VERSION ""

NS_ :

BS_:

BU_: Dummy_FO TestTool_FO LRR_FO RFSRR_FO LFSRR_FO RSRR_FO VIS_FO EOCM_F_FO

BO_ 1323 F_Fwd_Fus_Obj_TrackB_11: 7 EOCM_F_FO
 SG_ FwdFusTrkB11DynProp : 11|3@0+ (1,0) [0|7] ""  Dummy_FO
 SG_ FwdFusTrkB11RelLnAccl : 8|9@0- (0.125,0) [-32|31.875] "m/s^2"  Dummy_FO
 SG_ FwdFusTrkB11RelLane : 31|2@0+ (1,0) [0|3] ""  Dummy_FO
 SG_ FwdFusTrkB11Height : 54|6@0+ (0.25,0) [0|15.75] "m"  Dummy_FO
 SG_ FFusTrkB11ObjSrcLFSrr : 29|1@0+ (1,0) [0|1] ""  Dummy_FO
 SG_ FFusTrkB11ObjSrcLCSrr : 28|1@0+ (1,0) [0|1] ""  Dummy_FO
 SG_ FFusTrkB11ObjSrcRCSrr : 27|1@0+ (1,0) [0|1] ""  Dummy_FO
 SG_ FFusTrkB11ObjSrcRFSrr : 26|1@0+ (1,0) [0|1] ""  Dummy_FO
 SG_ FFusTrkB11ObjSrcVIs : 25|1@0+ (1,0) [0|1] ""  Dummy_FO
 SG_ FwdFusTrkB11ObjSrcLrr : 24|1@0+ (1,0) [0|1] ""  Dummy_FO
 SG_ FwdFusTrkB11NmCycTrkd : 39|3@0+ (1,0) [0|7] ""  Dummy_FO
 SG_ FwdFusTrkB11LatPosDev : 36|3@0+ (1,0) [0|7] ""  Dummy_FO
 SG_ FwdFusTrkB11LngPosDev : 33|3@0+ (1,0) [0|7] ""  Dummy_FO
 SG_ FwdFusTrkBAnlgRlLn11 : 46|8@0- (0.1,0) [-12.8|12.7] ""  Dummy_FO
 SG_ FwdFusTrkB11RollingCnt : 7|2@0+ (1,0) [0|3] ""  Dummy_FO
 SG_ FwdFusTrkB11Width : 5|6@0+ (0.25,0) [0|15.75] "m"  Dummy_FO
 SG_ FwdFusTrkB11MsgIndex : 15|4@0+ (1,0) [0|15] ""  Dummy_FO

BO_ 1322 F_Fwd_Fus_Obj_TrackB_10: 7 EOCM_F_FO
 SG_ FwdFusTrkBAnlgRlLn10 : 46|8@0- (0.1,0) [-12.8|12.7] ""  Dummy_FO
 SG_ FwdFusTrkB10RollingCnt : 7|2@0+ (1,0) [0|3] ""  Dummy_FO
 SG_ FwdFusTrkB10Width : 5|6@0+ (0.25,0) [0|15.75] "m"  Dummy_FO
 SG_ FwdFusTrkB10MsgIndex : 15|4@0+ (1,0) [0|15] ""  Dummy_FO
 SG_ FwdFusTrkB10DynProp : 11|3@0+ (1,0) [0|7] ""  Dummy_FO
 SG_ FwdFusTrkB10RelLnAccl : 8|9@0- (0.125,0) [-32|31.875] "m/s^2"  Dummy_FO
 SG_ FwdFusTrkB10RelLane : 31|2@0+ (1,0) [0|3] ""  Dummy_FO
 SG_ FwdFusTrkB10Height : 54|6@0+ (0.25,0) [0|15.75] "m"  Dummy_FO
 SG_ FFusTrkB10ObjSrcLFSrr : 29|1@0+ (1,0) [0|1] ""  Dummy_FO
 SG_ FFusTrkB10ObjSrcLCSrr : 28|1@0+ (1,0) [0|1] ""  Dummy_FO
 SG_ FFusTrkB10ObjSrcRCSrr : 27|1@0+ (1,0) [0|1] ""  Dummy_FO
 SG_ FFusTrkB10ObjSrcRFSrr : 26|1@0+ (1,0) [0|1] ""  Dummy_FO
 SG_ FFusTrkB10ObjSrcVIs : 25|1@0+ (1,0) [0|1] ""  Dummy_FO
 SG_ FwdFusTrkB10ObjSrcLrr : 24|1@0+ (1,0) [0|1] ""  Dummy_FO
 SG_ FwdFusTrkB10NmCycTrkd : 39|3@0+ (1,0) [0|7] ""  Dummy_FO
 SG_ FwdFusTrkB10LatPosDev : 36|3@0+ (1,0) [0|7] ""  Dummy_FO
 SG_ FwdFusTrkB10LngPosDev : 33|3@0+ (1,0) [0|7] ""  Dummy_FO

BO_ 1313 F_Fwd_Fus_Obj_TrackB_1: 7 EOCM_F_FO
 SG_ FwdFusTrkBAnlgRlLn1 : 46|8@0- (0.1,0) [-12.8|12.7] ""  Dummy_FO
 SG_ FwdFusTrkB1RollingCnt : 7|2@0+ (1,0) [0|3] ""  Dummy_FO
 SG_ FwdFusTrkB1Width : 5|6@0+ (0.25,0) [0|15.75] "m"  Dummy_FO
 SG_ FwdFusTrkB1MsgIndex : 15|4@0+ (1,0) [0|15] ""  Dummy_FO
 SG_ FwdFusTrkB1DynProp : 11|3@0+ (1,0) [0|7] ""  Dummy_FO
 SG_ FwdFusTrkB1RelLnAccl : 8|9@0- (0.125,0) [-32|31.875] "m/s^2"  Dummy_FO
 SG_ FwdFusTrkB1RelLane : 31|2@0+ (1,0) [0|3] ""  Dummy_FO
 SG_ FwdFusTrkB1Height : 54|6@0+ (0.25,0) [0|15.75] "m"  Dummy_FO
 SG_ FFusTrkB1ObjSrcLFSrr : 29|1@0+ (1,0) [0|1] ""  Dummy_FO
 SG_ FFusTrkB1ObjSrcLCSrr : 28|1@0+ (1,0) [0|1] ""  Dummy_FO
 SG_ FFusTrkB1ObjSrcRCSrr : 27|1@0+ (1,0) [0|1] ""  Dummy_FO
 SG_ FFusTrkB1ObjSrcRFSrr : 26|1@0+ (1,0) [0|1] ""  Dummy_FO
 SG_ FFusTrkB1ObjSrcVIs : 25|1@0+ (1,0) [0|1] ""  Dummy_FO
 SG_ FwdFusTrkB1ObjSrcLrr : 24|1@0+ (1,0) [0|1] ""  Dummy_FO
 SG_ FwdFusTrkB1NmCycTrkd : 39|3@0+ (1,0) [0|7] ""  Dummy_FO
 SG_ FwdFusTrkB1LatPosDev : 36|3@0+ (1,0) [0|7] ""  Dummy_FO
 SG_ FwdFusTrkB1LngPosDev : 33|3@0+ (1,0) [0|7] ""  Dummy_FO

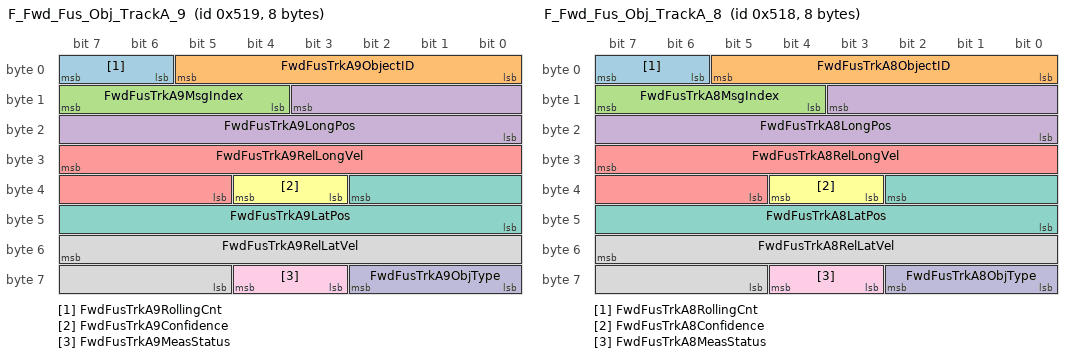
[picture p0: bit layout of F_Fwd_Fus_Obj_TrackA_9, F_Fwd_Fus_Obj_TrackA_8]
BO_ 1305 F_Fwd_Fus_Obj_TrackA_9: 8 EOCM_F_FO
 SG_ FwdFusTrkA9RollingCnt : 7|2@0+ (1,0) [0|3] ""  Dummy_FO
 SG_ FwdFusTrkA9ObjectID : 5|6@0+ (1,0) [0|63] ""  Dummy_FO
 SG_ FwdFusTrkA9MsgIndex : 15|4@0+ (1,0) [0|15] ""  Dummy_FO
 SG_ FwdFusTrkA9LongPos : 11|12@0- (0.125,0) [-256|255.875] "m"  Dummy_FO
 SG_ FwdFusTrkA9RelLongVel : 31|11@0- (0.125,0) [-128|127.875] "m/s"  Dummy_FO
 SG_ FwdFusTrkA9Confidence : 36|2@0+ (1,0) [0|3] ""  Dummy_FO
 SG_ FwdFusTrkA9LatPos : 34|11@0- (0.125,0) [-128|127.875] "m"  Dummy_FO
 SG_ FwdFusTrkA9RelLatVel : 55|11@0- (0.125,0) [-128|127.875] "m/s"  Dummy_FO
 SG_ FwdFusTrkA9MeasStatus : 60|2@0+ (1,0) [0|3] ""  Dummy_FO
 SG_ FwdFusTrkA9ObjType : 58|3@0+ (1,0) [0|7] ""  Dummy_FO

BO_ 1304 F_Fwd_Fus_Obj_TrackA_8: 8 EOCM_F_FO
 SG_ FwdFusTrkA8RollingCnt : 7|2@0+ (1,0) [0|3] ""  Dummy_FO
 SG_ FwdFusTrkA8ObjectID : 5|6@0+ (1,0) [0|63] ""  Dummy_FO
 SG_ FwdFusTrkA8MsgIndex : 15|4@0+ (1,0) [0|15] ""  Dummy_FO
 SG_ FwdFusTrkA8LongPos : 11|12@0- (0.125,0) [-256|255.875] "m"  Dummy_FO
 SG_ FwdFusTrkA8RelLongVel : 31|11@0- (0.125,0) [-128|127.875] "m/s"  Dummy_FO
 SG_ FwdFusTrkA8Confidence : 36|2@0+ (1,0) [0|3] ""  Dummy_FO
 SG_ FwdFusTrkA8LatPos : 34|11@0- (0.125,0) [-128|127.875] "m"  Dummy_FO
 SG_ FwdFusTrkA8RelLatVel : 55|11@0- (0.125,0) [-128|127.875] "m/s"  Dummy_FO
 SG_ FwdFusTrkA8MeasStatus : 60|2@0+ (1,0) [0|3] ""  Dummy_FO
 SG_ FwdFusTrkA8ObjType : 58|3@0+ (1,0) [0|7] ""  Dummy_FO

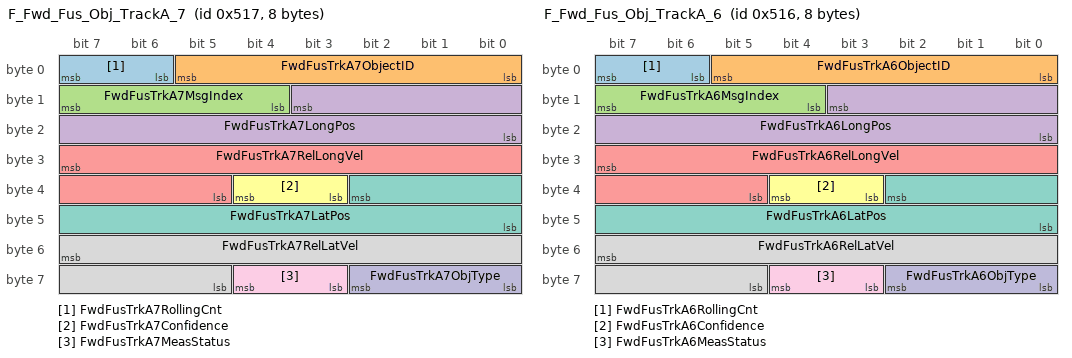
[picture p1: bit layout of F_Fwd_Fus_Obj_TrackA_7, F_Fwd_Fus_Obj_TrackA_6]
BO_ 1303 F_Fwd_Fus_Obj_TrackA_7: 8 EOCM_F_FO
 SG_ FwdFusTrkA7RollingCnt : 7|2@0+ (1,0) [0|3] ""  Dummy_FO
 SG_ FwdFusTrkA7ObjectID : 5|6@0+ (1,0) [0|63] ""  Dummy_FO
 SG_ FwdFusTrkA7MsgIndex : 15|4@0+ (1,0) [0|15] ""  Dummy_FO
 SG_ FwdFusTrkA7LongPos : 11|12@0- (0.125,0) [-256|255.875] "m"  Dummy_FO
 SG_ FwdFusTrkA7RelLongVel : 31|11@0- (0.125,0) [-128|127.875] "m/s"  Dummy_FO
 SG_ FwdFusTrkA7Confidence : 36|2@0+ (1,0) [0|3] ""  Dummy_FO
 SG_ FwdFusTrkA7LatPos : 34|11@0- (0.125,0) [-128|127.875] "m"  Dummy_FO
 SG_ FwdFusTrkA7RelLatVel : 55|11@0- (0.125,0) [-128|127.875] "m/s"  Dummy_FO
 SG_ FwdFusTrkA7MeasStatus : 60|2@0+ (1,0) [0|3] ""  Dummy_FO
 SG_ FwdFusTrkA7ObjType : 58|3@0+ (1,0) [0|7] ""  Dummy_FO

BO_ 1302 F_Fwd_Fus_Obj_TrackA_6: 8 EOCM_F_FO
 SG_ FwdFusTrkA6RollingCnt : 7|2@0+ (1,0) [0|3] ""  Dummy_FO
 SG_ FwdFusTrkA6ObjectID : 5|6@0+ (1,0) [0|63] ""  Dummy_FO
 SG_ FwdFusTrkA6MsgIndex : 15|4@0+ (1,0) [0|15] ""  Dummy_FO
 SG_ FwdFusTrkA6LongPos : 11|12@0- (0.125,0) [-256|255.875] "m"  Dummy_FO
 SG_ FwdFusTrkA6RelLongVel : 31|11@0- (0.125,0) [-128|127.875] "m/s"  Dummy_FO
 SG_ FwdFusTrkA6Confidence : 36|2@0+ (1,0) [0|3] ""  Dummy_FO
 SG_ FwdFusTrkA6LatPos : 34|11@0- (0.125,0) [-128|127.875] "m"  Dummy_FO
 SG_ FwdFusTrkA6RelLatVel : 55|11@0- (0.125,0) [-128|127.875] "m/s"  Dummy_FO
 SG_ FwdFusTrkA6MeasStatus : 60|2@0+ (1,0) [0|3] ""  Dummy_FO
 SG_ FwdFusTrkA6ObjType : 58|3@0+ (1,0) [0|7] ""  Dummy_FO

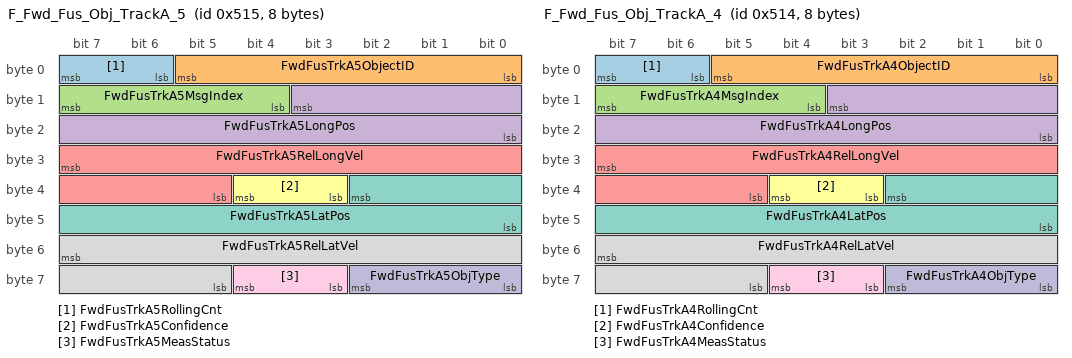
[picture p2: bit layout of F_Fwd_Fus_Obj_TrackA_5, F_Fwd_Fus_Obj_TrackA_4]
BO_ 1301 F_Fwd_Fus_Obj_TrackA_5: 8 EOCM_F_FO
 SG_ FwdFusTrkA5RollingCnt : 7|2@0+ (1,0) [0|3] ""  Dummy_FO
 SG_ FwdFusTrkA5ObjectID : 5|6@0+ (1,0) [0|63] ""  Dummy_FO
 SG_ FwdFusTrkA5MsgIndex : 15|4@0+ (1,0) [0|15] ""  Dummy_FO
 SG_ FwdFusTrkA5LongPos : 11|12@0- (0.125,0) [-256|255.875] "m"  Dummy_FO
 SG_ FwdFusTrkA5RelLongVel : 31|11@0- (0.125,0) [-128|127.875] "m/s"  Dummy_FO
 SG_ FwdFusTrkA5Confidence : 36|2@0+ (1,0) [0|3] ""  Dummy_FO
 SG_ FwdFusTrkA5LatPos : 34|11@0- (0.125,0) [-128|127.875] "m"  Dummy_FO
 SG_ FwdFusTrkA5RelLatVel : 55|11@0- (0.125,0) [-128|127.875] "m/s"  Dummy_FO
 SG_ FwdFusTrkA5MeasStatus : 60|2@0+ (1,0) [0|3] ""  Dummy_FO
 SG_ FwdFusTrkA5ObjType : 58|3@0+ (1,0) [0|7] ""  Dummy_FO

BO_ 1300 F_Fwd_Fus_Obj_TrackA_4: 8 EOCM_F_FO
 SG_ FwdFusTrkA4RollingCnt : 7|2@0+ (1,0) [0|3] ""  Dummy_FO
 SG_ FwdFusTrkA4ObjectID : 5|6@0+ (1,0) [0|63] ""  Dummy_FO
 SG_ FwdFusTrkA4MsgIndex : 15|4@0+ (1,0) [0|15] ""  Dummy_FO
 SG_ FwdFusTrkA4LongPos : 11|12@0- (0.125,0) [-256|255.875] "m"  Dummy_FO
 SG_ FwdFusTrkA4RelLongVel : 31|11@0- (0.125,0) [-128|127.875] "m/s"  Dummy_FO
 SG_ FwdFusTrkA4Confidence : 36|2@0+ (1,0) [0|3] ""  Dummy_FO
 SG_ FwdFusTrkA4LatPos : 34|11@0- (0.125,0) [-128|127.875] "m"  Dummy_FO
 SG_ FwdFusTrkA4RelLatVel : 55|11@0- (0.125,0) [-128|127.875] "m/s"  Dummy_FO
 SG_ FwdFusTrkA4MeasStatus : 60|2@0+ (1,0) [0|3] ""  Dummy_FO
 SG_ FwdFusTrkA4ObjType : 58|3@0+ (1,0) [0|7] ""  Dummy_FO

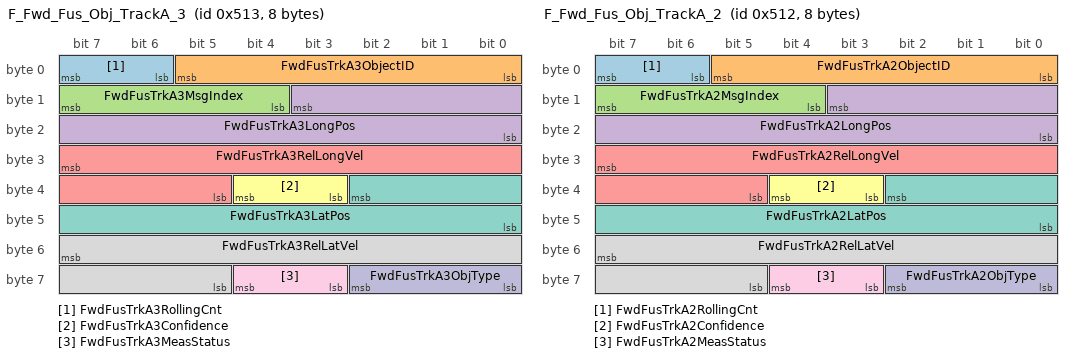
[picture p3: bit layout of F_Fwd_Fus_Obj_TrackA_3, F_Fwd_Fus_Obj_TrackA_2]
BO_ 1299 F_Fwd_Fus_Obj_TrackA_3: 8 EOCM_F_FO
 SG_ FwdFusTrkA3RollingCnt : 7|2@0+ (1,0) [0|3] ""  Dummy_FO
 SG_ FwdFusTrkA3ObjectID : 5|6@0+ (1,0) [0|63] ""  Dummy_FO
 SG_ FwdFusTrkA3MsgIndex : 15|4@0+ (1,0) [0|15] ""  Dummy_FO
 SG_ FwdFusTrkA3LongPos : 11|12@0- (0.125,0) [-256|255.875] "m"  Dummy_FO
 SG_ FwdFusTrkA3RelLongVel : 31|11@0- (0.125,0) [-128|127.875] "m/s"  Dummy_FO
 SG_ FwdFusTrkA3Confidence : 36|2@0+ (1,0) [0|3] ""  Dummy_FO
 SG_ FwdFusTrkA3LatPos : 34|11@0- (0.125,0) [-128|127.875] "m"  Dummy_FO
 SG_ FwdFusTrkA3RelLatVel : 55|11@0- (0.125,0) [-128|127.875] "m/s"  Dummy_FO
 SG_ FwdFusTrkA3MeasStatus : 60|2@0+ (1,0) [0|3] ""  Dummy_FO
 SG_ FwdFusTrkA3ObjType : 58|3@0+ (1,0) [0|7] ""  Dummy_FO

BO_ 1298 F_Fwd_Fus_Obj_TrackA_2: 8 EOCM_F_FO
 SG_ FwdFusTrkA2RollingCnt : 7|2@0+ (1,0) [0|3] ""  Dummy_FO
 SG_ FwdFusTrkA2ObjectID : 5|6@0+ (1,0) [0|63] ""  Dummy_FO
 SG_ FwdFusTrkA2MsgIndex : 15|4@0+ (1,0) [0|15] ""  Dummy_FO
 SG_ FwdFusTrkA2LongPos : 11|12@0- (0.125,0) [-256|255.875] "m"  Dummy_FO
 SG_ FwdFusTrkA2RelLongVel : 31|11@0- (0.125,0) [-128|127.875] "m/s"  Dummy_FO
 SG_ FwdFusTrkA2Confidence : 36|2@0+ (1,0) [0|3] ""  Dummy_FO
 SG_ FwdFusTrkA2LatPos : 34|11@0- (0.125,0) [-128|127.875] "m"  Dummy_FO
 SG_ FwdFusTrkA2RelLatVel : 55|11@0- (0.125,0) [-128|127.875] "m/s"  Dummy_FO
 SG_ FwdFusTrkA2MeasStatus : 60|2@0+ (1,0) [0|3] ""  Dummy_FO
 SG_ FwdFusTrkA2ObjType : 58|3@0+ (1,0) [0|7] ""  Dummy_FO

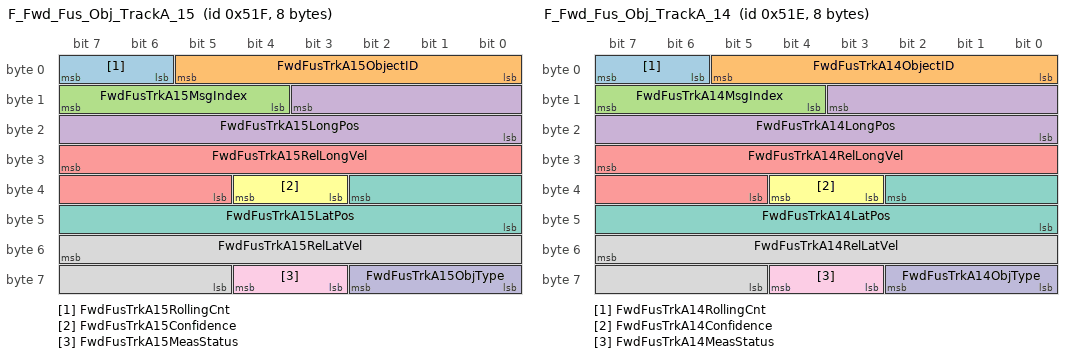
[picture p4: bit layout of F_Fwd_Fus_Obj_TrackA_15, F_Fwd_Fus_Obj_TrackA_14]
BO_ 1311 F_Fwd_Fus_Obj_TrackA_15: 8 EOCM_F_FO
 SG_ FwdFusTrkA15RollingCnt : 7|2@0+ (1,0) [0|3] ""  Dummy_FO
 SG_ FwdFusTrkA15ObjectID : 5|6@0+ (1,0) [0|63] ""  Dummy_FO
 SG_ FwdFusTrkA15MsgIndex : 15|4@0+ (1,0) [0|15] ""  Dummy_FO
 SG_ FwdFusTrkA15LongPos : 11|12@0- (0.125,0) [-256|255.875] "m"  Dummy_FO
 SG_ FwdFusTrkA15RelLongVel : 31|11@0- (0.125,0) [-128|127.875] "m/s"  Dummy_FO
 SG_ FwdFusTrkA15Confidence : 36|2@0+ (1,0) [0|3] ""  Dummy_FO
 SG_ FwdFusTrkA15LatPos : 34|11@0- (0.125,0) [-128|127.875] "m"  Dummy_FO
 SG_ FwdFusTrkA15RelLatVel : 55|11@0- (0.125,0) [-128|127.875] "m/s"  Dummy_FO
 SG_ FwdFusTrkA15MeasStatus : 60|2@0+ (1,0) [0|3] ""  Dummy_FO
 SG_ FwdFusTrkA15ObjType : 58|3@0+ (1,0) [0|7] ""  Dummy_FO

BO_ 1310 F_Fwd_Fus_Obj_TrackA_14: 8 EOCM_F_FO
 SG_ FwdFusTrkA14RollingCnt : 7|2@0+ (1,0) [0|3] ""  Dummy_FO
 SG_ FwdFusTrkA14ObjectID : 5|6@0+ (1,0) [0|63] ""  Dummy_FO
 SG_ FwdFusTrkA14MsgIndex : 15|4@0+ (1,0) [0|15] ""  Dummy_FO
 SG_ FwdFusTrkA14LongPos : 11|12@0- (0.125,0) [-256|255.875] "m"  Dummy_FO
 SG_ FwdFusTrkA14RelLongVel : 31|11@0- (0.125,0) [-128|127.875] "m/s"  Dummy_FO
 SG_ FwdFusTrkA14Confidence : 36|2@0+ (1,0) [0|3] ""  Dummy_FO
 SG_ FwdFusTrkA14LatPos : 34|11@0- (0.125,0) [-128|127.875] "m"  Dummy_FO
 SG_ FwdFusTrkA14RelLatVel : 55|11@0- (0.125,0) [-128|127.875] "m/s"  Dummy_FO
 SG_ FwdFusTrkA14MeasStatus : 60|2@0+ (1,0) [0|3] ""  Dummy_FO
 SG_ FwdFusTrkA14ObjType : 58|3@0+ (1,0) [0|7] ""  Dummy_FO

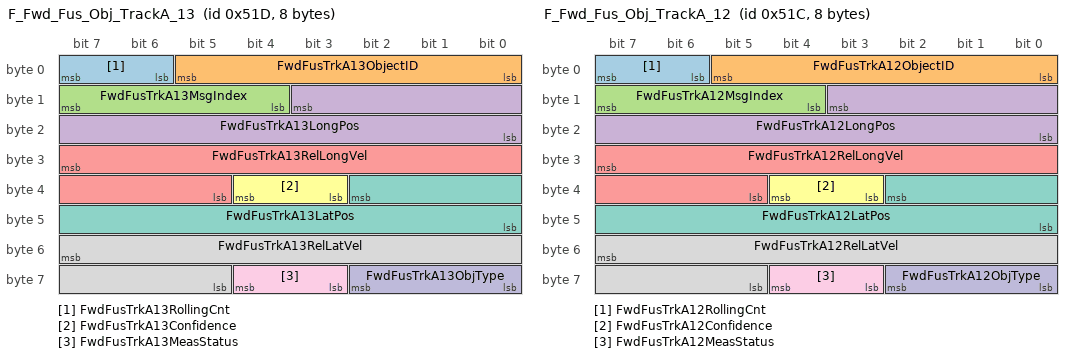
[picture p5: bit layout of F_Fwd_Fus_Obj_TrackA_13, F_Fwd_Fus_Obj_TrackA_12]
BO_ 1309 F_Fwd_Fus_Obj_TrackA_13: 8 EOCM_F_FO
 SG_ FwdFusTrkA13RollingCnt : 7|2@0+ (1,0) [0|3] ""  Dummy_FO
 SG_ FwdFusTrkA13ObjectID : 5|6@0+ (1,0) [0|63] ""  Dummy_FO
 SG_ FwdFusTrkA13MsgIndex : 15|4@0+ (1,0) [0|15] ""  Dummy_FO
 SG_ FwdFusTrkA13LongPos : 11|12@0- (0.125,0) [-256|255.875] "m"  Dummy_FO
 SG_ FwdFusTrkA13RelLongVel : 31|11@0- (0.125,0) [-128|127.875] "m/s"  Dummy_FO
 SG_ FwdFusTrkA13Confidence : 36|2@0+ (1,0) [0|3] ""  Dummy_FO
 SG_ FwdFusTrkA13LatPos : 34|11@0- (0.125,0) [-128|127.875] "m"  Dummy_FO
 SG_ FwdFusTrkA13RelLatVel : 55|11@0- (0.125,0) [-128|127.875] "m/s"  Dummy_FO
 SG_ FwdFusTrkA13MeasStatus : 60|2@0+ (1,0) [0|3] ""  Dummy_FO
 SG_ FwdFusTrkA13ObjType : 58|3@0+ (1,0) [0|7] ""  Dummy_FO

BO_ 1308 F_Fwd_Fus_Obj_TrackA_12: 8 EOCM_F_FO
 SG_ FwdFusTrkA12RollingCnt : 7|2@0+ (1,0) [0|3] ""  Dummy_FO
 SG_ FwdFusTrkA12ObjectID : 5|6@0+ (1,0) [0|63] ""  Dummy_FO
 SG_ FwdFusTrkA12MsgIndex : 15|4@0+ (1,0) [0|15] ""  Dummy_FO
 SG_ FwdFusTrkA12LongPos : 11|12@0- (0.125,0) [-256|255.875] "m"  Dummy_FO
 SG_ FwdFusTrkA12RelLongVel : 31|11@0- (0.125,0) [-128|127.875] "m/s"  Dummy_FO
 SG_ FwdFusTrkA12Confidence : 36|2@0+ (1,0) [0|3] ""  Dummy_FO
 SG_ FwdFusTrkA12LatPos : 34|11@0- (0.125,0) [-128|127.875] "m"  Dummy_FO
 SG_ FwdFusTrkA12RelLatVel : 55|11@0- (0.125,0) [-128|127.875] "m/s"  Dummy_FO
 SG_ FwdFusTrkA12MeasStatus : 60|2@0+ (1,0) [0|3] ""  Dummy_FO
 SG_ FwdFusTrkA12ObjType : 58|3@0+ (1,0) [0|7] ""  Dummy_FO

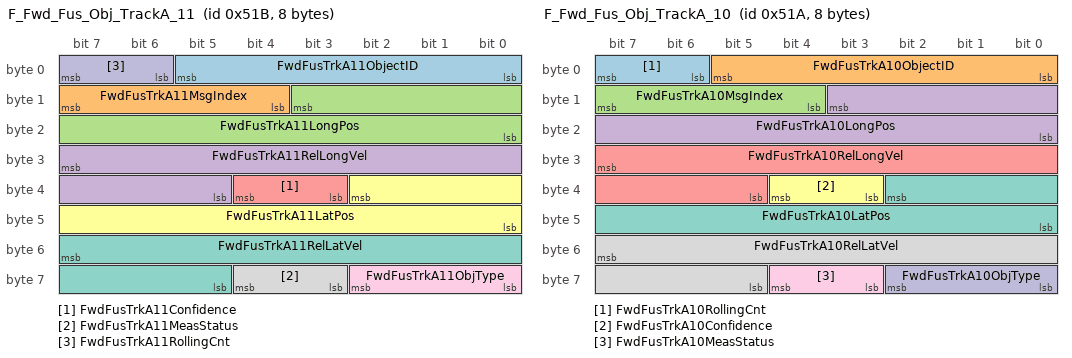
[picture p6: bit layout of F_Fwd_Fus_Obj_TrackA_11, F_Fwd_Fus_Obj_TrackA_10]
BO_ 1307 F_Fwd_Fus_Obj_TrackA_11: 8 EOCM_F_FO
 SG_ FwdFusTrkA11ObjectID : 5|6@0+ (1,0) [0|63] ""  Dummy_FO
 SG_ FwdFusTrkA11MsgIndex : 15|4@0+ (1,0) [0|15] ""  Dummy_FO
 SG_ FwdFusTrkA11LongPos : 11|12@0- (0.125,0) [-256|255.875] "m"  Dummy_FO
 SG_ FwdFusTrkA11RelLongVel : 31|11@0- (0.125,0) [-128|127.875] "m/s"  Dummy_FO
 SG_ FwdFusTrkA11Confidence : 36|2@0+ (1,0) [0|3] ""  Dummy_FO
 SG_ FwdFusTrkA11LatPos : 34|11@0- (0.125,0) [-128|127.875] "m"  Dummy_FO
 SG_ FwdFusTrkA11RelLatVel : 55|11@0- (0.125,0) [-128|127.875] "m/s"  Dummy_FO
 SG_ FwdFusTrkA11MeasStatus : 60|2@0+ (1,0) [0|3] ""  Dummy_FO
 SG_ FwdFusTrkA11ObjType : 58|3@0+ (1,0) [0|7] ""  Dummy_FO
 SG_ FwdFusTrkA11RollingCnt : 7|2@0+ (1,0) [0|3] ""  Dummy_FO

BO_ 1306 F_Fwd_Fus_Obj_TrackA_10: 8 EOCM_F_FO
 SG_ FwdFusTrkA10RollingCnt : 7|2@0+ (1,0) [0|3] ""  Dummy_FO
 SG_ FwdFusTrkA10ObjectID : 5|6@0+ (1,0) [0|63] ""  Dummy_FO
 SG_ FwdFusTrkA10MsgIndex : 15|4@0+ (1,0) [0|15] ""  Dummy_FO
 SG_ FwdFusTrkA10LongPos : 11|12@0- (0.125,0) [-256|255.875] "m"  Dummy_FO
 SG_ FwdFusTrkA10RelLongVel : 31|11@0- (0.125,0) [-128|127.875] "m/s"  Dummy_FO
 SG_ FwdFusTrkA10Confidence : 36|2@0+ (1,0) [0|3] ""  Dummy_FO
 SG_ FwdFusTrkA10LatPos : 34|11@0- (0.125,0) [-128|127.875] "m"  Dummy_FO
 SG_ FwdFusTrkA10RelLatVel : 55|11@0- (0.125,0) [-128|127.875] "m/s"  Dummy_FO
 SG_ FwdFusTrkA10MeasStatus : 60|2@0+ (1,0) [0|3] ""  Dummy_FO
 SG_ FwdFusTrkA10ObjType : 58|3@0+ (1,0) [0|7] ""  Dummy_FO

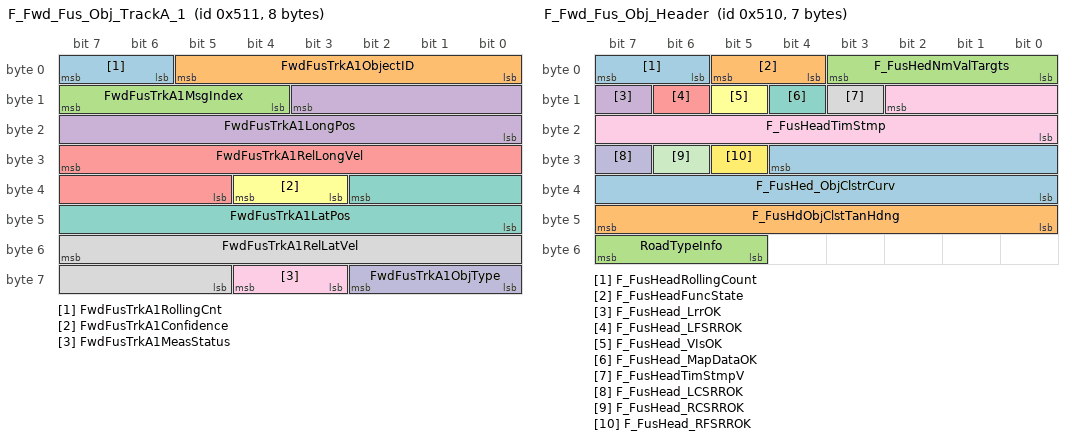
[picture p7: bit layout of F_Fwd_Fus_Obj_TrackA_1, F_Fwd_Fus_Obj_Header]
BO_ 1297 F_Fwd_Fus_Obj_TrackA_1: 8 EOCM_F_FO
 SG_ FwdFusTrkA1RollingCnt : 7|2@0+ (1,0) [0|3] ""  Dummy_FO
 SG_ FwdFusTrkA1ObjectID : 5|6@0+ (1,0) [0|63] ""  Dummy_FO
 SG_ FwdFusTrkA1MsgIndex : 15|4@0+ (1,0) [0|15] ""  Dummy_FO
 SG_ FwdFusTrkA1LongPos : 11|12@0- (0.125,0) [-256|255.875] "m"  Dummy_FO
 SG_ FwdFusTrkA1RelLongVel : 31|11@0- (0.125,0) [-128|127.875] "m/s"  Dummy_FO
 SG_ FwdFusTrkA1Confidence : 36|2@0+ (1,0) [0|3] ""  Dummy_FO
 SG_ FwdFusTrkA1LatPos : 34|11@0- (0.125,0) [-128|127.875] "m"  Dummy_FO
 SG_ FwdFusTrkA1RelLatVel : 55|11@0- (0.125,0) [-128|127.875] "m/s"  Dummy_FO
 SG_ FwdFusTrkA1MeasStatus : 60|2@0+ (1,0) [0|3] ""  Dummy_FO
 SG_ FwdFusTrkA1ObjType : 58|3@0+ (1,0) [0|7] ""  Dummy_FO

BO_ 1296 F_Fwd_Fus_Obj_Header: 7 EOCM_F_FO
 SG_ F_FusHeadRollingCount : 7|2@0+ (1,0) [0|3] ""  Dummy_FO
 SG_ F_FusHeadFuncState : 5|2@0+ (1,0) [0|3] ""  Dummy_FO
 SG_ F_FusHedNmValTargts : 3|4@0+ (1,0) [0|15] ""  Dummy_FO
 SG_ F_FusHead_LrrOK : 15|1@0+ (1,0) [0|1] ""  Dummy_FO
 SG_ F_FusHead_LFSRROK : 14|1@0+ (1,0) [0|1] ""  Dummy_FO
 SG_ F_FusHead_VIsOK : 13|1@0+ (1,0) [0|1] ""  Dummy_FO
 SG_ F_FusHead_MapDataOK : 12|1@0+ (1,0) [0|1] ""  Dummy_FO
 SG_ F_FusHeadTimStmpV : 11|1@0+ (1,0) [0|1] ""  Dummy_FO
 SG_ F_FusHeadTimStmp : 10|11@0+ (1,0) [0|2047] "ms"  Dummy_FO
 SG_ F_FusHead_LCSRROK : 31|1@0+ (1,0) [0|1] ""  Dummy_FO
 SG_ F_FusHead_RCSRROK : 30|1@0+ (1,0) [0|1] ""  Dummy_FO
 SG_ F_FusHead_RFSRROK : 29|1@0+ (1,0) [0|1] ""  Dummy_FO
 SG_ F_FusHed_ObjClstrCurv : 28|13@0- (5E-005,0) [-0.2048|0.20475] "1/m"  Dummy_FO
 SG_ F_FusHdObjClstTanHdng : 47|8@0- (0.002,0) [-0.256|0.254] "m/m"  Dummy_FO
 SG_ RoadTypeInfo : 55|3@0+ (1,0) [0|7] ""  Dummy_FO

BO_ 257 USDT_Req_to_All_FO_ECUs: 8 TestTool_FO
 SG_ DgnInf : 7|64@0+ (1,0) [0|1.844674407371E+019] ""  VIS_FO,RFSRR_FO,LRR_FO,LFSRR_FO,RSRR_FO,EOCM_F_FO

BO_ 1338 VPDR_Debug: 8 EOCM_F_FO
 SG_ FrtRWARateDiagFA : 43|1@0+ (1,0) [0|1] ""  Dummy_FO
 SG_ FrtRWABiasDiagFA : 42|1@0+ (1,0) [0|1] ""  Dummy_FO
 SG_ HWAFrtVal : 41|1@0+ (1,0) [0|1] ""  Dummy_FO
 SG_ HWADotValFrt : 40|1@0+ (1,0) [0|1] ""  Dummy_FO
 SG_ S2VehAxRangeFA : 39|1@0+ (1,0) [0|1] ""  Dummy_FO
 SG_ S2VehAxRateFA : 38|1@0+ (1,0) [0|1] ""  Dummy_FO
 SG_ S2VehAxBiasFA : 37|1@0+ (1,0) [0|1] ""  Dummy_FO
 SG_ VehAxCompFA : 36|1@0+ (1,0) [0|1] ""  Dummy_FO
 SG_ S1VehAxVal : 35|1@0+ (1,0) [0|1] ""  Dummy_FO
 SG_ S2VehAxVal : 34|1@0+ (1,0) [0|1] ""  Dummy_FO
 SG_ FrtRWACorrFA : 33|1@0+ (1,0) [0|1] ""  Dummy_FO
 SG_ FrtRWARangeDiagFA : 32|1@0+ (1,0) [0|1] ""  Dummy_FO
 SG_ S2VehAyBiasFA : 31|1@0+ (1,0) [0|1] ""  Dummy_FO
 SG_ VehAyCompFA : 30|1@0+ (1,0) [0|1] ""  Dummy_FO
 SG_ S1VehAyVal : 29|1@0+ (1,0) [0|1] ""  Dummy_FO
 SG_ S2VehAyVal : 28|1@0+ (1,0) [0|1] ""  Dummy_FO
 SG_ VehAxCorrFA : 27|1@0+ (1,0) [0|1] ""  Dummy_FO
 SG_ S1VehAxRangeFA : 26|1@0+ (1,0) [0|1] ""  Dummy_FO
 SG_ S1VehAxRateFA : 25|1@0+ (1,0) [0|1] ""  Dummy_FO
 SG_ S1VehAxBiasFA : 24|1@0+ (1,0) [0|1] ""  Dummy_FO
 SG_ S1VehWzVal : 23|1@0+ (1,0) [0|1] ""  Dummy_FO
 SG_ S2VehWzVal : 22|1@0+ (1,0) [0|1] ""  Dummy_FO
 SG_ VehAyCorrDiagFA : 21|1@0+ (1,0) [0|1] ""  Dummy_FO
 SG_ S1VehAyRangeFA : 20|1@0+ (1,0) [0|1] ""  Dummy_FO
 SG_ S1VehAyRateFA : 19|1@0+ (1,0) [0|1] ""  Dummy_FO
 SG_ S1VehAyBiasFA : 18|1@0+ (1,0) [0|1] ""  Dummy_FO
 SG_ S2VehAyRangeFA : 17|1@0+ (1,0) [0|1] ""  Dummy_FO
 SG_ S2VehAyRateFA : 16|1@0+ (1,0) [0|1] ""  Dummy_FO
 SG_ VehWzCorrDiagFA : 15|1@0+ (1,0) [0|1] ""  Dummy_FO
 SG_ S1VehWzRangeFA : 14|1@0+ (1,0) [0|1] ""  Dummy_FO
 SG_ S1VehWzRateFA : 13|1@0+ (1,0) [0|1] ""  Dummy_FO
 SG_ S1VehWzBiasFA : 12|1@0+ (1,0) [0|1] ""  Dummy_FO
 SG_ S2VehWzRangeFA : 11|1@0+ (1,0) [0|1] ""  Dummy_FO
 SG_ S2VehWzRateFA : 10|1@0+ (1,0) [0|1] ""  Dummy_FO
 SG_ S2VehWzBiasFA : 9|1@0+ (1,0) [0|1] ""  Dummy_FO
 SG_ VehWzCompFA : 8|1@0+ (1,0) [0|1] ""  Dummy_FO
 SG_ WhlVxLFCorrDiagFA : 7|1@0+ (1,0) [0|1] ""  Dummy_FO
 SG_ WhlVxRFCorrDiagFA : 6|1@0+ (1,0) [0|1] ""  Dummy_FO
 SG_ WhlVxLRCorrDiagFA : 5|1@0+ (1,0) [0|1] ""  Dummy_FO
 SG_ WhlVxRRCorrDiagFA : 4|1@0+ (1,0) [0|1] ""  Dummy_FO
 SG_ WhlLFVal : 3|1@0+ (1,0) [0|1] ""  Dummy_FO
 SG_ WhlRFVal : 2|1@0+ (1,0) [0|1] ""  Dummy_FO
 SG_ WhlLRVal : 1|1@0+ (1,0) [0|1] ""  Dummy_FO
 SG_ WhlRRVal : 0|1@0+ (1,0) [0|1] ""  Dummy_FO

BO_ 1328 Diag_Debug1: 8 EOCM_F_FO
 SG_ AlrtWrnIndReqFP : 1|1@0+ (1,0) [0|1] ""  Dummy_FO
 SG_ AlrtWrnIndReqFA : 0|1@0+ (1,0) [0|1] ""  Dummy_FO
 SG_ ILRSRRSnsr_FP : 24|1@0+ (1,0) [0|1] ""  Dummy_FO
 SG_ ILRSRRSnsr_FA : 23|1@0+ (1,0) [0|1] ""  Dummy_FO
 SG_ ILRSRRFrehns_FA : 22|1@0+ (1,0) [0|1] ""  Dummy_FO
 SG_ VehPathEstCrvCSFP : 21|1@0+ (1,0) [0|1] ""  Dummy_FO
 SG_ VehPathEstCrvCSFA : 20|1@0+ (1,0) [0|1] ""  Dummy_FO
 SG_ VehPathWzEstCSFP : 19|1@0+ (1,0) [0|1] ""  Dummy_FO
 SG_ VehPathWzEstCSFA : 18|1@0+ (1,0) [0|1] ""  Dummy_FO
 SG_ VehPathVyEstCSFP : 17|1@0+ (1,0) [0|1] ""  Dummy_FO
 SG_ VehPathVyEstCSFA : 16|1@0+ (1,0) [0|1] ""  Dummy_FO
 SG_ VehPathVxEstCSFP : 15|1@0+ (1,0) [0|1] ""  Dummy_FO
 SG_ VehPathVxEstCSFA : 14|1@0+ (1,0) [0|1] ""  Dummy_FO
 SG_ TCPHiThrtTTCCSFP : 13|1@0+ (1,0) [0|1] ""  Dummy_FO
 SG_ TCPHiThrtTTCCSFA : 12|1@0+ (1,0) [0|1] ""  Dummy_FO
 SG_ TCPHiThrtLyCSFP : 11|1@0+ (1,0) [0|1] ""  Dummy_FO
 SG_ TCPHiThrtLyCSFA : 10|1@0+ (1,0) [0|1] ""  Dummy_FO
 SG_ TCPHiThLxVxAxCSFP : 9|1@0+ (1,0) [0|1] ""  Dummy_FO
 SG_ TCPHiThLxVxAxCSFA : 8|1@0+ (1,0) [0|1] ""  Dummy_FO
 SG_ CurSetValDiagFP : 7|1@0+ (1,0) [0|1] ""  Dummy_FO
 SG_ CurSetValDiagFA : 6|1@0+ (1,0) [0|1] ""  Dummy_FO
 SG_ CrsAltDvrSlTpDiagFP : 5|1@0+ (1,0) [0|1] ""  Dummy_FO
 SG_ CrsAltDvrSlTpDiagFA : 4|1@0+ (1,0) [0|1] ""  Dummy_FO
 SG_ FCAStatDiagFP : 3|1@0+ (1,0) [0|1] ""  Dummy_FO
 SG_ FCAStatDiagFA : 2|1@0+ (1,0) [0|1] ""  Dummy_FO
 SG_ RVBBrkCtrlStFP : 62|1@0+ (1,0) [0|1] ""  Dummy_FO
 SG_ RVBBrkCtrlStFA : 61|1@0+ (1,0) [0|1] ""  Dummy_FO
 SG_ RVBOpStFP : 60|1@0+ (1,0) [0|1] ""  Dummy_FO
 SG_ RVBOpStFA : 59|1@0+ (1,0) [0|1] ""  Dummy_FO
 SG_ RVBBrkCtrlAccFP : 58|1@0+ (1,0) [0|1] ""  Dummy_FO
 SG_ RVBBrkCtrlAccFA : 57|1@0+ (1,0) [0|1] ""  Dummy_FO
 SG_ RVBAxlTrqRqFP : 56|1@0+ (1,0) [0|1] ""  Dummy_FO
 SG_ RVBAxlTrqRqFA : 55|1@0+ (1,0) [0|1] ""  Dummy_FO
 SG_ TVRUPATTCFP : 54|1@0+ (1,0) [0|1] ""  Dummy_FO
 SG_ TVRUPATTCFA : 53|1@0+ (1,0) [0|1] ""  Dummy_FO
 SG_ TVRHiThrtObjIDFP : 52|1@0+ (1,0) [0|1] ""  Dummy_FO
 SG_ TVRHiThrtObjIDFA : 51|1@0+ (1,0) [0|1] ""  Dummy_FO
 SG_ TVRHiThrtTTCFP : 50|1@0+ (1,0) [0|1] ""  Dummy_FO
 SG_ TVRHiThrtTTCFA : 49|1@0+ (1,0) [0|1] ""  Dummy_FO
 SG_ TVRHiThrtLxFP : 48|1@0+ (1,0) [0|1] ""  Dummy_FO
 SG_ TVRHiThrtLxFA : 47|1@0+ (1,0) [0|1] ""  Dummy_FO
 SG_ TVRHiThrtLyFP : 46|1@0+ (1,0) [0|1] ""  Dummy_FO
 SG_ TVRHiThrtLyFA : 45|1@0+ (1,0) [0|1] ""  Dummy_FO
 SG_ ROFFuncStFP : 44|1@0+ (1,0) [0|1] ""  Dummy_FO
 SG_ ROFFuncStFA : 43|1@0+ (1,0) [0|1] ""  Dummy_FO
 SG_ ROFObjIDFP : 42|1@0+ (1,0) [0|1] ""  Dummy_FO
 SG_ ROFObjIDFA : 41|1@0+ (1,0) [0|1] ""  Dummy_FO
 SG_ ROFLatPstnVelRatFP : 40|1@0+ (1,0) [0|1] ""  Dummy_FO
 SG_ ROFLatPstnVelRatFA : 39|1@0+ (1,0) [0|1] ""  Dummy_FO
 SG_ ROFLonPstnVelFP : 38|1@0+ (1,0) [0|1] ""  Dummy_FO
 SG_ ROFLonPstnVelFA : 37|1@0+ (1,0) [0|1] ""  Dummy_FO
 SG_ ROFRltvLatVelDiagFP : 36|1@0+ (1,0) [0|1] ""  Dummy_FO
 SG_ ROFRltvLatVelDiagFA : 35|1@0+ (1,0) [0|1] ""  Dummy_FO
 SG_ ROFRltvLatPstnDiagFP : 34|1@0+ (1,0) [0|1] ""  Dummy_FO
 SG_ ROFRltvLatPstnDiagFA : 33|1@0+ (1,0) [0|1] ""  Dummy_FO
 SG_ ROFNrRltvLonPstnFP : 32|1@0+ (1,0) [0|1] ""  Dummy_FO
 SG_ ROFNrRltvLonPstnFA : 31|1@0+ (1,0) [0|1] ""  Dummy_FO
 SG_ ROFLonPstnVelRatFP : 30|1@0+ (1,0) [0|1] ""  Dummy_FO
 SG_ ROFLonPstnVelRatFA : 29|1@0+ (1,0) [0|1] ""  Dummy_FO
 SG_ ROFConfDiagFP : 28|1@0+ (1,0) [0|1] ""  Dummy_FO
 SG_ ROFConfDiagFA : 27|1@0+ (1,0) [0|1] ""  Dummy_FO
 SG_ ROFRltvLnDiagFP : 26|1@0+ (1,0) [0|1] ""  Dummy_FO
 SG_ ROFRltvLnDiagFA : 25|1@0+ (1,0) [0|1] ""  Dummy_FO

BO_ 1335 Diag_Debug3: 8 EOCM_F_FO
 SG_ BrkSysCmdAxDiagFPQ : 63|1@0+ (1,0) [0|1] ""  Dummy_FO
 SG_ BrkSysCmdAxDiagFAQ : 62|1@0+ (1,0) [0|1] ""  Dummy_FO
 SG_ AxleTorqReqDiagFPQ : 61|1@0+ (1,0) [0|1] ""  Dummy_FO
 SG_ AxleTorqReqDiagFAQ : 60|1@0+ (1,0) [0|1] ""  Dummy_FO
 SG_ AutoBrkTypeDiagFPQ : 59|1@0+ (1,0) [0|1] ""  Dummy_FO
 SG_ AutoBrkTypeDiagFAQ : 58|1@0+ (1,0) [0|1] ""  Dummy_FO
 SG_ TCPHiThrtTTCFPQ : 57|1@0+ (1,0) [0|1] ""  Dummy_FO
 SG_ TCPHiThrtTTCFAQ : 56|1@0+ (1,0) [0|1] ""  Dummy_FO
 SG_ TCPHiThrtTmpMemFPQ : 55|1@0+ (1,0) [0|1] ""  Dummy_FO
 SG_ TCPHiThrtTmpMemFAQ : 54|1@0+ (1,0) [0|1] ""  Dummy_FO
 SG_ TCPHiThrtLxVxAxFPQ : 53|1@0+ (1,0) [0|1] ""  Dummy_FO
 SG_ TCPHiThrtLxVxAxFAQ : 52|1@0+ (1,0) [0|1] ""  Dummy_FO
 SG_ TCPHiThrtVyFPQ : 51|1@0+ (1,0) [0|1] ""  Dummy_FO
 SG_ TCPHiThrtVyFAQ : 50|1@0+ (1,0) [0|1] ""  Dummy_FO
 SG_ TCPHiThrtLyFPQ : 49|1@0+ (1,0) [0|1] ""  Dummy_FO
 SG_ TCPHiThrtLyFAQ : 48|1@0+ (1,0) [0|1] ""  Dummy_FO
 SG_ TCPHiThrtConPriFPQ : 47|1@0+ (1,0) [0|1] ""  Dummy_FO
 SG_ TCPHiThrtConPriFAQ : 46|1@0+ (1,0) [0|1] ""  Dummy_FO
 SG_ TCPHiThrtCJLFPQ : 45|1@0+ (1,0) [0|1] ""  Dummy_FO
 SG_ TCPHiThrtCJLFAQ : 44|1@0+ (1,0) [0|1] ""  Dummy_FO
 SG_ TCPDynPropDiagFPQ : 43|1@0+ (1,0) [0|1] ""  Dummy_FO
 SG_ TCPDynPropDiagFAQ : 42|1@0+ (1,0) [0|1] ""  Dummy_FO
 SG_ FOFRdTypInfoFPQ : 41|1@0+ (1,0) [0|1] ""  Dummy_FO
 SG_ FOFRdTypInfoFAQ : 40|1@0+ (1,0) [0|1] ""  Dummy_FO
 SG_ FOFRltvLnDiagFPQ : 39|1@0+ (1,0) [0|1] ""  Dummy_FO
 SG_ FOFRltvLnDiagFAQ : 38|1@0+ (1,0) [0|1] ""  Dummy_FO
 SG_ FOFNumCycDiagFPQ : 37|1@0+ (1,0) [0|1] ""  Dummy_FO
 SG_ FOFNumCycDiagFAQ : 36|1@0+ (1,0) [0|1] ""  Dummy_FO
 SG_ FOFNumFusCyclsFPQ : 35|1@0+ (1,0) [0|1] ""  Dummy_FO
 SG_ FOFNumFusCyclsFAQ : 34|1@0+ (1,0) [0|1] ""  Dummy_FO
 SG_ FOFNrRltvLonPstnFPQ : 33|1@0+ (1,0) [0|1] ""  Dummy_FO
 SG_ FOFNrRltvLonPstnFAQ : 32|1@0+ (1,0) [0|1] ""  Dummy_FO
 SG_ FOFLonVelAccRatFPQ : 31|1@0+ (1,0) [0|1] ""  Dummy_FO
 SG_ FOFLonVelAccRatFAQ : 30|1@0+ (1,0) [0|1] ""  Dummy_FO
 SG_ FOFLonPstnVelRatFPQ : 29|1@0+ (1,0) [0|1] ""  Dummy_FO
 SG_ FOFLonPstnVelRatFAQ : 28|1@0+ (1,0) [0|1] ""  Dummy_FO
 SG_ FOFLonPosVelAccFPQ : 27|1@0+ (1,0) [0|1] ""  Dummy_FO
 SG_ FOFLonPosVelAccFAQ : 26|1@0+ (1,0) [0|1] ""  Dummy_FO
 SG_ FOFLatVelDiagFPQ : 25|1@0+ (1,0) [0|1] ""  Dummy_FO
 SG_ FOFLatVelDiagFAQ : 24|1@0+ (1,0) [0|1] ""  Dummy_FO
 SG_ FOFLatPstnDiagFPQ : 23|1@0+ (1,0) [0|1] ""  Dummy_FO
 SG_ FOFLatPstnDiagFAQ : 22|1@0+ (1,0) [0|1] ""  Dummy_FO
 SG_ FOFConfDiagFPQ : 21|1@0+ (1,0) [0|1] ""  Dummy_FO
 SG_ FOFConfDiagFAQ : 20|1@0+ (1,0) [0|1] ""  Dummy_FO
 SG_ ILFOvrlpRtlChk_FAQ : 19|1@0+ (1,0) [0|1] ""  Dummy_FO
 SG_ IRFOvrlpRtlChk_FAQ : 18|1@0+ (1,0) [0|1] ""  Dummy_FO
 SG_ LRROvrlpRtlChk_FAQ : 17|1@0+ (1,0) [0|1] ""  Dummy_FO
 SG_ VISOvrlpRtlChk_FAQ : 16|1@0+ (1,0) [0|1] ""  Dummy_FO
 SG_ VISAlign_FAQ : 15|1@0+ (1,0) [0|1] ""  Dummy_FO
 SG_ VISSnsr_FAQ : 14|1@0+ (1,0) [0|1] ""  Dummy_FO
 SG_ VISSnsr_FPQ : 13|1@0+ (1,0) [0|1] ""  Dummy_FO
 SG_ VISFrshns_FAQ : 12|1@0+ (1,0) [0|1] ""  Dummy_FO
 SG_ LRRAlign_FAQ : 11|1@0+ (1,0) [0|1] ""  Dummy_FO
 SG_ LRRFrshns_FAQ : 10|1@0+ (1,0) [0|1] ""  Dummy_FO
 SG_ LRRSnsr_FAQ : 9|1@0+ (1,0) [0|1] ""  Dummy_FO
 SG_ LRRSnsr_FPQ : 8|1@0+ (1,0) [0|1] ""  Dummy_FO
 SG_ IRFSRRAlign_FAQ : 7|1@0+ (1,0) [0|1] ""  Dummy_FO
 SG_ IRFSRRFrehns_FAQ : 6|1@0+ (1,0) [0|1] ""  Dummy_FO
 SG_ IRFSRRSnsr_FAQ : 5|1@0+ (1,0) [0|1] ""  Dummy_FO
 SG_ IRFSRRSnsr_FPQ : 4|1@0+ (1,0) [0|1] ""  Dummy_FO
 SG_ ILFSRRSnsr_FPQ : 3|1@0+ (1,0) [0|1] ""  Dummy_FO
 SG_ ILFSRRSnsr_FAQ : 2|1@0+ (1,0) [0|1] ""  Dummy_FO
 SG_ ILFSRRFrshns_FAQ : 1|1@0+ (1,0) [0|1] ""  Dummy_FO
 SG_ ILFSRRAlign_FAQ : 0|1@0+ (1,0) [0|1] ""  Dummy_FO

BO_ 1331 Diag_Debug2: 8 EOCM_F_FO
 SG_ TCPHiThrtTmpMemFP : 63|1@0+ (1,0) [0|1] ""  Dummy_FO
 SG_ TCPHiThrtTmpMemFA : 62|1@0+ (1,0) [0|1] ""  Dummy_FO
 SG_ TCPHiThrtConPriFP : 61|1@0+ (1,0) [0|1] ""  Dummy_FO
 SG_ TCPHiThrtConPriFA : 60|1@0+ (1,0) [0|1] ""  Dummy_FO
 SG_ TCPHiThrtCJLFP : 59|1@0+ (1,0) [0|1] ""  Dummy_FO
 SG_ TCPHiThrtTTCFP : 58|1@0+ (1,0) [0|1] ""  Dummy_FO
 SG_ TCPHiThrtTTCFA : 57|1@0+ (1,0) [0|1] ""  Dummy_FO
 SG_ TCPHiThrtVyFP : 56|1@0+ (1,0) [0|1] ""  Dummy_FO
 SG_ TCPHiThrtVyFA : 55|1@0+ (1,0) [0|1] ""  Dummy_FO
 SG_ TCPHiThrtLyFP : 54|1@0+ (1,0) [0|1] ""  Dummy_FO
 SG_ TCPHiThrtLyFA : 53|1@0+ (1,0) [0|1] ""  Dummy_FO
 SG_ TCPHiThrtLxVxAxFP : 52|1@0+ (1,0) [0|1] ""  Dummy_FO
 SG_ TCPHiThrtLxVxAxFA : 51|1@0+ (1,0) [0|1] ""  Dummy_FO
 SG_ FOFRdTypInfoFP : 50|1@0+ (1,0) [0|1] ""  Dummy_FO
 SG_ FOFRdTypInfoFA : 49|1@0+ (1,0) [0|1] ""  Dummy_FO
 SG_ AutoBrkTypeDiagFA : 48|1@0+ (1,0) [0|1] ""  Dummy_FO
 SG_ BrkSysCmdAxDiagFP : 47|1@0+ (1,0) [0|1] ""  Dummy_FO
 SG_ BrkSysCmdAxDiagFA : 46|1@0+ (1,0) [0|1] ""  Dummy_FO
 SG_ AxleTorqReqDiagFP : 45|1@0+ (1,0) [0|1] ""  Dummy_FO
 SG_ AxleTorqReqDiagFA : 44|1@0+ (1,0) [0|1] ""  Dummy_FO
 SG_ TCPDynPropDiagFP : 43|1@0+ (1,0) [0|1] ""  Dummy_FO
 SG_ TCPDynPropDiagFA : 42|1@0+ (1,0) [0|1] ""  Dummy_FO
 SG_ TCPHiThrtCJLFA : 41|1@0+ (1,0) [0|1] ""  Dummy_FO
 SG_ FOFNumFusCyclsFP : 40|1@0+ (1,0) [0|1] ""  Dummy_FO
 SG_ AutoBrkTypeDiagFP : 39|1@0+ (1,0) [0|1] ""  Dummy_FO
 SG_ FOFNumFusCyclsFA : 38|1@0+ (1,0) [0|1] ""  Dummy_FO
 SG_ FOFLatVelDiagFP : 37|1@0+ (1,0) [0|1] ""  Dummy_FO
 SG_ FOFLatVelDiagFA : 36|1@0+ (1,0) [0|1] ""  Dummy_FO
 SG_ FOFLatPstnDiagFP : 35|1@0+ (1,0) [0|1] ""  Dummy_FO
 SG_ FOFLatPstnDiagFA : 34|1@0+ (1,0) [0|1] ""  Dummy_FO
 SG_ FOFNumCycDiagFP : 33|1@0+ (1,0) [0|1] ""  Dummy_FO
 SG_ FOFNumCycDiagFA : 32|1@0+ (1,0) [0|1] ""  Dummy_FO
 SG_ FOFRltvLnDiagFP : 31|1@0+ (1,0) [0|1] ""  Dummy_FO
 SG_ FOFRltvLnDiagFA : 30|1@0+ (1,0) [0|1] ""  Dummy_FO
 SG_ FOFConfDiagFP : 29|1@0+ (1,0) [0|1] ""  Dummy_FO
 SG_ FOFConfDiagFA : 28|1@0+ (1,0) [0|1] ""  Dummy_FO
 SG_ FOFLonVelAccRatFP : 27|1@0+ (1,0) [0|1] ""  Dummy_FO
 SG_ FOFLonVelAccRatFA : 26|1@0+ (1,0) [0|1] ""  Dummy_FO
 SG_ FOFLonPstnVelRatFP : 25|1@0+ (1,0) [0|1] ""  Dummy_FO
 SG_ FOFLonPstnVelRatFA : 24|1@0+ (1,0) [0|1] ""  Dummy_FO
 SG_ FOFNrRltvLonPstnFP : 23|1@0+ (1,0) [0|1] ""  Dummy_FO
 SG_ FOFNrRltvLonPstnFA : 22|1@0+ (1,0) [0|1] ""  Dummy_FO
 SG_ FOFLonPosVelAccFP : 21|1@0+ (1,0) [0|1] ""  Dummy_FO
 SG_ FOFLonPosVelAccFA : 20|1@0+ (1,0) [0|1] ""  Dummy_FO
 SG_ VISOvrlpRtlChk_FA : 19|1@0+ (1,0) [0|1] ""  Dummy_FO
 SG_ LRROvrlpRtlChk_FA : 18|1@0+ (1,0) [0|1] ""  Dummy_FO
 SG_ IRFOvrlpRtlChk_FA : 17|1@0+ (1,0) [0|1] ""  Dummy_FO
 SG_ ILFOvrlpRtlChk_FA : 16|1@0+ (1,0) [0|1] ""  Dummy_FO
 SG_ VISAlign_FA : 15|1@0+ (1,0) [0|1] ""  Dummy_FO
 SG_ VISFrshns_FA : 14|1@0+ (1,0) [0|1] ""  Dummy_FO
 SG_ VISSnsr_FP : 13|1@0+ (1,0) [0|1] ""  Dummy_FO
 SG_ VISSnsr_FA : 12|1@0+ (1,0) [0|1] ""  Dummy_FO
 SG_ LRRAlign_FA : 11|1@0+ (1,0) [0|1] ""  Dummy_FO
 SG_ LRRFrshns_FA : 10|1@0+ (1,0) [0|1] ""  Dummy_FO
 SG_ LRRSnsr_FP : 9|1@0+ (1,0) [0|1] ""  Dummy_FO
 SG_ LRRSnsr_FA : 8|1@0+ (1,0) [0|1] ""  Dummy_FO
 SG_ IRFSRRAlign_FA : 7|1@0+ (1,0) [0|1] ""  Dummy_FO
 SG_ IRFSRRFrehns_FA : 6|1@0+ (1,0) [0|1] ""  Dummy_FO
 SG_ IRFSRRSnsr_FP : 5|1@0+ (1,0) [0|1] ""  Dummy_FO
 SG_ IRFSRRSnsr_FA : 4|1@0+ (1,0) [0|1] ""  Dummy_FO
 SG_ ILFSRRAlign_FA : 3|1@0+ (1,0) [0|1] ""  Dummy_FO
 SG_ ILFSRRFrshns_FA : 2|1@0+ (1,0) [0|1] ""  Dummy_FO
 SG_ ILFSRRSnsr_FP : 1|1@0+ (1,0) [0|1] ""  Dummy_FO
 SG_ ILFSRRSnsr_FA : 0|1@0+ (1,0) [0|1] ""  Dummy_FO

BO_ 1787 AL_Test_Tool_Rsp_RFSRR: 8 RFSRR_FO
 SG_ RFSRREngRspDta : 7|64@0+ (1,0) [0|1.844674407371E+019] ""  Dummy_FO

BO_ 1788 AL_Test_Tool_Rsp_LFSRR: 8 LFSRR_FO
 SG_ LFSRREngRspDta : 7|64@0+ (1,0) [0|1.844674407371E+019] ""  Dummy_FO

BO_ 1790 AL_Test_Tool_Req_RFSRR: 8 Dummy_FO
 SG_ RFSRREngCmdDta : 7|64@0+ (1,0) [0|1.844674407371E+019] ""  RFSRR_FO

BO_ 1791 AL_Test_Tool_Req_LFSRR: 8 Dummy_FO
 SG_ LFSRREngCmdDta : 7|64@0+ (1,0) [0|1.844674407371E+019] ""  LFSRR_FO

BO_ 1786 AL_Test_Tool_Rsp_RSRR: 8 RSRR_FO
 SG_ RSRREngRspDta : 7|64@0+ (1,0) [0|1.844674407371E+019] ""  Dummy_FO

BO_ 1789 AL_Test_Tool_Req_RSRR: 8 Dummy_FO
 SG_ RSRREngCmdDta : 7|64@0+ (1,0) [0|1.844674407371E+019] ""  RSRR_FO

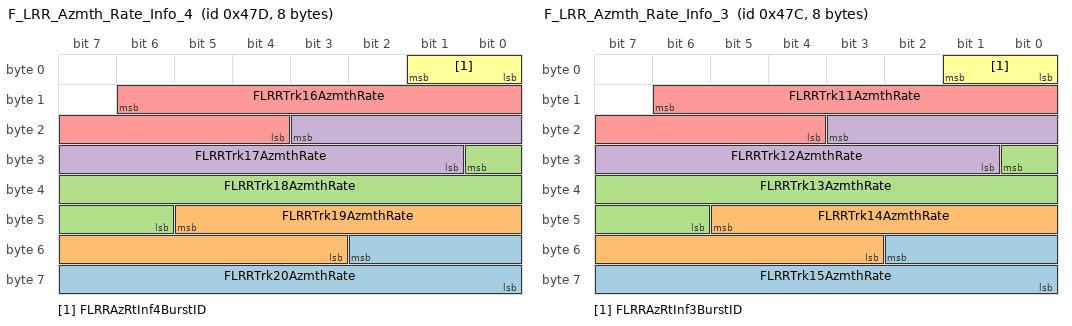
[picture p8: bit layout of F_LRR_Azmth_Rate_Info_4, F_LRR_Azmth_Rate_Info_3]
BO_ 1149 F_LRR_Azmth_Rate_Info_4: 8 LRR_FO
 SG_ FLRRTrk20AzmthRate : 50|11@0- (0.125,0) [-128|127.875] "deg/s"  EOCM_F_FO
 SG_ FLRRTrk19AzmthRate : 45|11@0- (0.125,0) [-128|127.875] "deg/s"  EOCM_F_FO
 SG_ FLRRTrk18AzmthRate : 24|11@0- (0.125,0) [-128|127.875] "deg/s"  EOCM_F_FO
 SG_ FLRRTrk17AzmthRate : 19|11@0- (0.125,0) [-128|127.875] "deg/s"  EOCM_F_FO
 SG_ FLRRTrk16AzmthRate : 14|11@0- (0.125,0) [-128|127.875] "deg/s"  EOCM_F_FO
 SG_ FLRRAzRtInf4BurstID : 1|2@0+ (1,0) [0|3] ""  EOCM_F_FO

BO_ 1148 F_LRR_Azmth_Rate_Info_3: 8 LRR_FO
 SG_ FLRRTrk15AzmthRate : 50|11@0- (0.125,0) [-128|127.875] "deg/s"  EOCM_F_FO
 SG_ FLRRTrk14AzmthRate : 45|11@0- (0.125,0) [-128|127.875] "deg/s"  EOCM_F_FO
 SG_ FLRRTrk13AzmthRate : 24|11@0- (0.125,0) [-128|127.875] "deg/s"  EOCM_F_FO
 SG_ FLRRTrk12AzmthRate : 19|11@0- (0.125,0) [-128|127.875] "deg/s"  EOCM_F_FO
 SG_ FLRRTrk11AzmthRate : 14|11@0- (0.125,0) [-128|127.875] "deg/s"  EOCM_F_FO
 SG_ FLRRAzRtInf3BurstID : 1|2@0+ (1,0) [0|3] ""  EOCM_F_FO

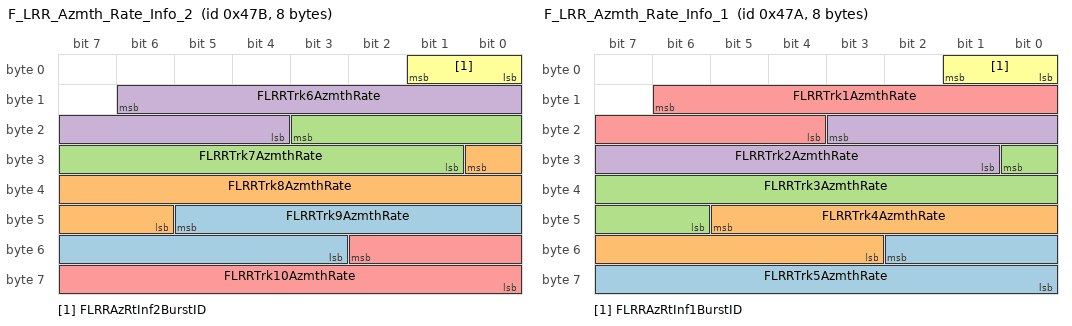
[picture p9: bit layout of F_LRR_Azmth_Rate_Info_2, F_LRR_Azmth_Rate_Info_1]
BO_ 1147 F_LRR_Azmth_Rate_Info_2: 8 LRR_FO
 SG_ FLRRTrk9AzmthRate : 45|11@0- (0.125,0) [-128|127.875] "deg/s"  EOCM_F_FO
 SG_ FLRRTrk8AzmthRate : 24|11@0- (0.125,0) [-128|127.875] "deg/s"  EOCM_F_FO
 SG_ FLRRTrk7AzmthRate : 19|11@0- (0.125,0) [-128|127.875] "deg/s"  EOCM_F_FO
 SG_ FLRRTrk6AzmthRate : 14|11@0- (0.125,0) [-128|127.875] "deg/s"  EOCM_F_FO
 SG_ FLRRTrk10AzmthRate : 50|11@0- (0.125,0) [-128|127.875] "deg/s"  EOCM_F_FO
 SG_ FLRRAzRtInf2BurstID : 1|2@0+ (1,0) [0|3] ""  EOCM_F_FO

BO_ 1146 F_LRR_Azmth_Rate_Info_1: 8 LRR_FO
 SG_ FLRRTrk5AzmthRate : 50|11@0- (0.125,0) [-128|127.875] "deg/s"  EOCM_F_FO
 SG_ FLRRTrk4AzmthRate : 45|11@0- (0.125,0) [-128|127.875] "deg/s"  EOCM_F_FO
 SG_ FLRRTrk3AzmthRate : 24|11@0- (0.125,0) [-128|127.875] "deg/s"  EOCM_F_FO
 SG_ FLRRTrk2AzmthRate : 19|11@0- (0.125,0) [-128|127.875] "deg/s"  EOCM_F_FO
 SG_ FLRRTrk1AzmthRate : 14|11@0- (0.125,0) [-128|127.875] "deg/s"  EOCM_F_FO
 SG_ FLRRAzRtInf1BurstID : 1|2@0+ (1,0) [0|3] ""  EOCM_F_FO

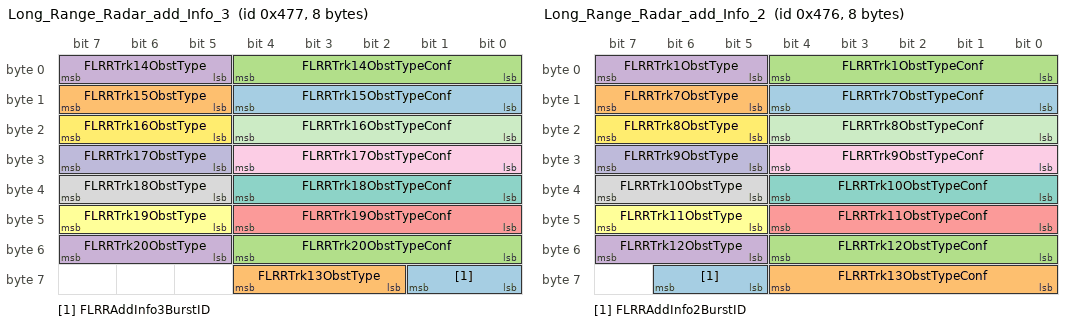
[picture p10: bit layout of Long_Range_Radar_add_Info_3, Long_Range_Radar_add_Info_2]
BO_ 1143 Long_Range_Radar_add_Info_3: 8 LRR_FO
 SG_ FLRRAddInfo3BurstID : 57|2@0+ (1,0) [0|3] ""  EOCM_F_FO
 SG_ FLRRTrk13ObstType : 60|3@0+ (1,0) [0|7] ""  EOCM_F_FO
 SG_ FLRRTrk20ObstTypeConf : 52|5@0+ (0.0323,0) [0|1.0013] ""  EOCM_F_FO
 SG_ FLRRTrk20ObstType : 55|3@0+ (1,0) [0|7] ""  EOCM_F_FO
 SG_ FLRRTrk19ObstTypeConf : 44|5@0+ (0.0323,0) [0|1.0013] ""  EOCM_F_FO
 SG_ FLRRTrk19ObstType : 47|3@0+ (1,0) [0|7] ""  EOCM_F_FO
 SG_ FLRRTrk18ObstTypeConf : 36|5@0+ (0.0323,0) [0|1.0013] ""  EOCM_F_FO
 SG_ FLRRTrk18ObstType : 39|3@0+ (1,0) [0|7] ""  EOCM_F_FO
 SG_ FLRRTrk17ObstTypeConf : 28|5@0+ (0.0323,0) [0|1.0013] ""  EOCM_F_FO
 SG_ FLRRTrk17ObstType : 31|3@0+ (1,0) [0|7] ""  EOCM_F_FO
 SG_ FLRRTrk16ObstTypeConf : 20|5@0+ (0.0323,0) [0|1.0013] ""  EOCM_F_FO
 SG_ FLRRTrk16ObstType : 23|3@0+ (1,0) [0|7] ""  EOCM_F_FO
 SG_ FLRRTrk15ObstTypeConf : 12|5@0+ (0.0323,0) [0|1.0013] ""  EOCM_F_FO
 SG_ FLRRTrk15ObstType : 15|3@0+ (1,0) [0|7] ""  EOCM_F_FO
 SG_ FLRRTrk14ObstTypeConf : 4|5@0+ (0.0323,0) [0|1.0013] ""  EOCM_F_FO
 SG_ FLRRTrk14ObstType : 7|3@0+ (1,0) [0|7] ""  EOCM_F_FO

BO_ 1142 Long_Range_Radar_add_Info_2: 8 LRR_FO
 SG_ FLRRAddInfo2BurstID : 62|2@0+ (1,0) [0|3] ""  EOCM_F_FO
 SG_ FLRRTrk13ObstTypeConf : 60|5@0+ (0.0323,0) [0|1.0013] ""  EOCM_F_FO
 SG_ FLRRTrk12ObstTypeConf : 52|5@0+ (0.0323,0) [0|1.0013] ""  EOCM_F_FO
 SG_ FLRRTrk12ObstType : 55|3@0+ (1,0) [0|7] ""  EOCM_F_FO
 SG_ FLRRTrk11ObstTypeConf : 44|5@0+ (0.0323,0) [0|1.0013] ""  EOCM_F_FO
 SG_ FLRRTrk11ObstType : 47|3@0+ (1,0) [0|7] ""  EOCM_F_FO
 SG_ FLRRTrk10ObstTypeConf : 36|5@0+ (0.0323,0) [0|1.0013] ""  EOCM_F_FO
 SG_ FLRRTrk10ObstType : 39|3@0+ (1,0) [0|7] ""  EOCM_F_FO
 SG_ FLRRTrk9ObstTypeConf : 28|5@0+ (0.0323,0) [0|1.0013] ""  EOCM_F_FO
 SG_ FLRRTrk9ObstType : 31|3@0+ (1,0) [0|7] ""  EOCM_F_FO
 SG_ FLRRTrk8ObstTypeConf : 20|5@0+ (0.0323,0) [0|1.0013] ""  EOCM_F_FO
 SG_ FLRRTrk8ObstType : 23|3@0+ (1,0) [0|7] ""  EOCM_F_FO
 SG_ FLRRTrk7ObstTypeConf : 12|5@0+ (0.0323,0) [0|1.0013] ""  EOCM_F_FO
 SG_ FLRRTrk7ObstType : 15|3@0+ (1,0) [0|7] ""  EOCM_F_FO
 SG_ FLRRTrk1ObstTypeConf : 4|5@0+ (0.0323,0) [0|1.0013] ""  EOCM_F_FO
 SG_ FLRRTrk1ObstType : 7|3@0+ (1,0) [0|7] ""  EOCM_F_FO

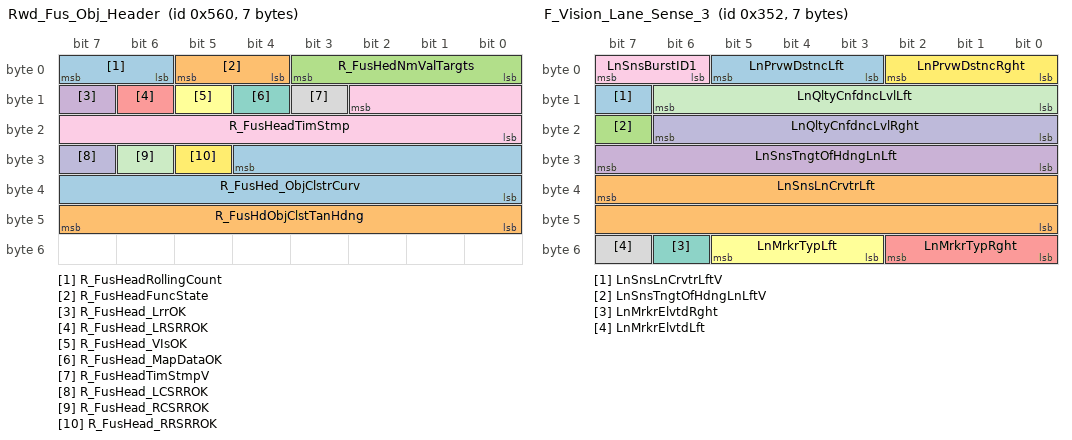
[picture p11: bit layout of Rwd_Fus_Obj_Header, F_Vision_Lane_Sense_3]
BO_ 1376 Rwd_Fus_Obj_Header: 7 EOCM_F_FO
 SG_ R_FusHeadRollingCount : 7|2@0+ (1,0) [0|3] ""  Dummy_FO
 SG_ R_FusHeadFuncState : 5|2@0+ (1,0) [0|3] ""  Dummy_FO
 SG_ R_FusHedNmValTargts : 3|4@0+ (1,0) [0|15] ""  Dummy_FO
 SG_ R_FusHead_LrrOK : 15|1@0+ (1,0) [0|1] ""  Dummy_FO
 SG_ R_FusHead_LRSRROK : 14|1@0+ (1,0) [0|1] ""  Dummy_FO
 SG_ R_FusHead_VIsOK : 13|1@0+ (1,0) [0|1] ""  Dummy_FO
 SG_ R_FusHead_MapDataOK : 12|1@0+ (1,0) [0|1] ""  Dummy_FO
 SG_ R_FusHeadTimStmpV : 11|1@0+ (1,0) [0|1] ""  Dummy_FO
 SG_ R_FusHeadTimStmp : 10|11@0+ (1,0) [0|2047] "ms"  Dummy_FO
 SG_ R_FusHead_LCSRROK : 31|1@0+ (1,0) [0|1] ""  Dummy_FO
 SG_ R_FusHead_RCSRROK : 30|1@0+ (1,0) [0|1] ""  Dummy_FO
 SG_ R_FusHead_RRSRROK : 29|1@0+ (1,0) [0|1] ""  Dummy_FO
 SG_ R_FusHed_ObjClstrCurv : 28|13@0- (5E-005,0) [-0.2048|0.20475] "1/m"  Dummy_FO
 SG_ R_FusHdObjClstTanHdng : 47|8@0- (0.002,0) [-0.256|0.254] "m/m"  Dummy_FO

BO_ 851 F_Vision_Lane_Sense_4: 3 VIS_FO
 SG_ LnSnsCrvtGrdntLft : 15|16@0- (5.96E-008,0) [-0.0019529728|0.0019529132] "1/rad/s"  EOCM_F_FO
 SG_ LnSnsBurstID2 : 1|2@0+ (1,0) [0|3] ""  EOCM_F_FO

BO_ 850 F_Vision_Lane_Sense_3: 7 VIS_FO
 SG_ LnSnsLnCrvtrLftV : 15|1@0+ (1,0) [0|1] ""  EOCM_F_FO
 SG_ LnSnsLnCrvtrLft : 39|16@0- (9.53E-007,0) [-0.031227904|0.031226951] "1/m"  EOCM_F_FO
 SG_ LnSnsTngtOfHdngLnLftV : 23|1@0+ (1,0) [0|1] ""  EOCM_F_FO
 SG_ LnSnsTngtOfHdngLnLft : 31|8@0- (0.002,0) [-0.256|0.254] "m/m"  EOCM_F_FO
 SG_ LnMrkrTypRght : 50|3@0+ (1,0) [0|0] ""  EOCM_F_FO
 SG_ LnMrkrTypLft : 53|3@0+ (1,0) [0|0] ""  EOCM_F_FO
 SG_ LnMrkrElvtdRght : 54|1@0+ (1,0) [0|1] ""  EOCM_F_FO
 SG_ LnMrkrElvtdLft : 55|1@0+ (1,0) [0|1] ""  EOCM_F_FO
 SG_ LnSnsBurstID1 : 7|2@0+ (1,0) [0|3] ""  EOCM_F_FO
 SG_ LnQltyCnfdncLvlRght : 22|7@0+ (0.7874016,0) [0|100.0000032] "%"  EOCM_F_FO
 SG_ LnQltyCnfdncLvlLft : 14|7@0+ (0.7874016,0) [0|100.0000032] "%"  EOCM_F_FO
 SG_ LnPrvwDstncRght : 2|3@0+ (10,0) [0|70] "m"  EOCM_F_FO
 SG_ LnPrvwDstncLft : 5|3@0+ (10,0) [0|70] "m"  EOCM_F_FO

BA_DEF_ SG_  "VNSigSLHSSharedDiagnostic" ENUM  "No","Yes";
BA_DEF_ SG_  "SignalType" STRING ;
BA_DEF_ SG_  "PacketOrder" INT 0 65535;
BA_DEF_ SG_  "SignalLongName" STRING ;
BA_DEF_ SG_  "GenSigStartValue" INT 0 65535;
BA_DEF_ SG_  "VNSigAllNodes" ENUM  "No","Yes";
BA_DEF_ SG_  "GenSigSendType" ENUM  "not used","not used","not used","not used","not used","not used","not used","NoSigSendType","not used","not used","OnAnyChange","OnChangeIfActive","OnDelta";
BA_DEF_ SG_  "GenSigSendOnInit" ENUM  "Not Initialized","Application","Handler";
BA_DEF_ BO_  "GenMsgILSupport" ENUM  "No","Yes";
BA_DEF_ BO_  "TpApplType" STRING ;
BA_DEF_ BO_  "Prio" INT 0 7;
BA_DEF_ BO_  "MessageSubnet" ENUM  "LS","MS","HS","CE","PE","HV","FO";
BA_DEF_ BO_  "DiagState" ENUM  "No","Yes";
BA_DEF_ BO_  "GenMsgDelayTime" INT 0 100000;
BA_DEF_ BO_  "GenMsgCycleTime" INT 0 100000;
BA_DEF_ BO_  "GenMsgCycleTimeFast" INT 0 100000;
BA_DEF_ BO_  "GenMsgSendType" ENUM  "cyclicX","spontanX","cyclicIfActiveX","spontanWithDelay","cyclicAndSpontanX","cyclicAndSpontanWithDelay","spontanWithRepitition","cyclicIfActiveAndSpontanWD";
BA_DEF_ BO_  "DiagResponse" ENUM  "No","Yes";
BA_DEF_ BO_  "DiagRequest" ENUM  "No","Yes";
BA_DEF_ BO_  "NmMessage" ENUM  "No","Yes";
BA_DEF_REL_ BU_SG_REL_  "GenSigSuprvRespComment" STRING ;
BA_DEF_REL_ BU_SG_REL_  "GenSigVBitResp" ENUM  "No","Yes";
BA_DEF_REL_ BU_SG_REL_  "GenSigVBitRespComment" STRING ;
BA_DEF_REL_ BU_SG_REL_  "GenSigVDAFailComment" STRING ;
BA_DEF_REL_ BU_SG_REL_  "GenSigSuprvResp" ENUM  "None","Notify App","Substitute Default";
BA_DEF_REL_ BU_SG_REL_  "GenSigTimeoutMsg" HEX -2147483648 268435455;
BA_DEF_REL_ BU_SG_REL_  "GenSigTimeoutTime" INT 0 15000;
BA_DEF_DEF_  "VNSigSLHSSharedDiagnostic" "No";
BA_DEF_DEF_  "SignalType" "";
BA_DEF_DEF_  "PacketOrder" 0;
BA_DEF_DEF_  "SignalLongName" "";
BA_DEF_DEF_  "GenSigStartValue" 0;
BA_DEF_DEF_  "VNSigAllNodes" "No";
BA_DEF_DEF_  "GenSigSendType" "NoSigSendType";
BA_DEF_DEF_  "GenSigSendOnInit" "Not Initialized";
BA_DEF_DEF_  "GenMsgILSupport" "Yes";
BA_DEF_DEF_  "TpApplType" "";
BA_DEF_DEF_  "Prio" 4;
BA_DEF_DEF_  "MessageSubnet" "FO";
BA_DEF_DEF_  "DiagState" "No";
BA_DEF_DEF_  "GenMsgDelayTime" 0;
BA_DEF_DEF_  "GenMsgCycleTime" 0;
BA_DEF_DEF_  "GenMsgCycleTimeFast" 0;
BA_DEF_DEF_  "GenMsgSendType" "spontanX";
BA_DEF_DEF_  "DiagResponse" "No";
BA_DEF_DEF_  "DiagRequest" "No";
BA_DEF_DEF_  "NmMessage" "No";
BA_DEF_DEF_REL_ "GenSigSuprvRespComment" "";
BA_DEF_DEF_REL_ "GenSigVBitResp" "No";
BA_DEF_DEF_REL_ "GenSigVBitRespComment" "";
BA_DEF_DEF_REL_ "GenSigVDAFailComment" "";
BA_DEF_DEF_REL_ "GenSigSuprvResp" "None";
BA_DEF_DEF_REL_ "GenSigTimeoutMsg" 0;
BA_DEF_DEF_REL_ "GenSigTimeoutTime" 0;
BA_ "Prio" BO_ 1323 0;
BA_ "GenMsgCycleTime" BO_ 1323 80;
BA_ "GenMsgSendType" BO_ 1323 0;
BA_ "Prio" BO_ 1322 0;
BA_ "GenMsgCycleTime" BO_ 1322 80;
BA_ "GenMsgSendType" BO_ 1322 0;
BA_ "Prio" BO_ 1313 0;
BA_ "GenMsgCycleTime" BO_ 1313 80;
BA_ "GenMsgSendType" BO_ 1313 0;
BA_ "Prio" BO_ 1305 0;
BA_ "GenMsgCycleTime" BO_ 1305 80;
BA_ "GenMsgSendType" BO_ 1305 0;
BA_ "Prio" BO_ 1304 0;
BA_ "GenMsgCycleTime" BO_ 1304 80;
BA_ "GenMsgSendType" BO_ 1304 0;
BA_ "Prio" BO_ 1303 0;
BA_ "GenMsgCycleTime" BO_ 1303 80;
BA_ "GenMsgSendType" BO_ 1303 0;
BA_ "Prio" BO_ 1302 0;
BA_ "GenMsgCycleTime" BO_ 1302 80;
BA_ "GenMsgSendType" BO_ 1302 0;
BA_ "Prio" BO_ 1301 0;
BA_ "GenMsgCycleTime" BO_ 1301 80;
BA_ "GenMsgSendType" BO_ 1301 0;
BA_ "Prio" BO_ 1300 0;
BA_ "GenMsgCycleTime" BO_ 1300 80;
BA_ "GenMsgSendType" BO_ 1300 0;
BA_ "Prio" BO_ 1299 0;
BA_ "GenMsgCycleTime" BO_ 1299 80;
BA_ "GenMsgSendType" BO_ 1299 0;
BA_ "Prio" BO_ 1298 0;
BA_ "GenMsgCycleTime" BO_ 1298 80;
BA_ "GenMsgSendType" BO_ 1298 0;
BA_ "Prio" BO_ 1311 0;
BA_ "GenMsgCycleTime" BO_ 1311 80;
BA_ "GenMsgSendType" BO_ 1311 0;
BA_ "Prio" BO_ 1310 0;
BA_ "GenMsgCycleTime" BO_ 1310 80;
BA_ "GenMsgSendType" BO_ 1310 0;
BA_ "Prio" BO_ 1309 0;
BA_ "GenMsgCycleTime" BO_ 1309 80;
BA_ "GenMsgSendType" BO_ 1309 0;
BA_ "Prio" BO_ 1308 0;
BA_ "GenMsgCycleTime" BO_ 1308 80;
BA_ "GenMsgSendType" BO_ 1308 0;
BA_ "Prio" BO_ 1307 0;
BA_ "GenMsgCycleTime" BO_ 1307 80;
BA_ "GenMsgSendType" BO_ 1307 0;
BA_ "Prio" BO_ 1306 0;
BA_ "GenMsgCycleTime" BO_ 1306 80;
BA_ "GenMsgSendType" BO_ 1306 0;
BA_ "Prio" BO_ 1297 0;
BA_ "GenMsgCycleTime" BO_ 1297 80;
BA_ "GenMsgSendType" BO_ 1297 0;
BA_ "Prio" BO_ 1296 0;
BA_ "GenMsgCycleTime" BO_ 1296 80;
BA_ "GenMsgSendType" BO_ 1296 0;
BA_ "GenMsgILSupport" BO_ 257 0;
BA_ "Prio" BO_ 257 0;
BA_ "DiagState" BO_ 257 1;
BA_ "Prio" BO_ 1338 0;
BA_ "GenMsgCycleTime" BO_ 1338 100;
BA_ "GenMsgSendType" BO_ 1338 0;
BA_ "Prio" BO_ 1328 0;
BA_ "GenMsgCycleTime" BO_ 1328 100;
BA_ "GenMsgSendType" BO_ 1328 0;
BA_ "Prio" BO_ 1335 0;
BA_ "GenMsgCycleTime" BO_ 1335 100;
BA_ "GenMsgSendType" BO_ 1335 0;
BA_ "Prio" BO_ 1331 0;
BA_ "GenMsgCycleTime" BO_ 1331 100;
BA_ "GenMsgSendType" BO_ 1331 0;
BA_ "Prio" BO_ 1787 0;
BA_ "GenMsgCycleTime" BO_ 1787 100;
BA_ "GenMsgSendType" BO_ 1787 0;
BA_ "Prio" BO_ 1788 0;
BA_ "GenMsgCycleTime" BO_ 1788 100;
BA_ "GenMsgSendType" BO_ 1788 0;
BA_ "Prio" BO_ 1790 0;
BA_ "GenMsgCycleTime" BO_ 1790 100;
BA_ "GenMsgSendType" BO_ 1790 0;
BA_ "Prio" BO_ 1791 0;
BA_ "GenMsgCycleTime" BO_ 1791 100;
BA_ "GenMsgSendType" BO_ 1791 0;
BA_ "Prio" BO_ 1786 0;
BA_ "GenMsgCycleTime" BO_ 1786 100;
BA_ "GenMsgSendType" BO_ 1786 0;
BA_ "Prio" BO_ 1789 0;
BA_ "GenMsgCycleTime" BO_ 1789 100;
BA_ "GenMsgSendType" BO_ 1789 0;
BA_ "Prio" BO_ 1149 0;
BA_ "GenMsgDelayTime" BO_ 1149 60;
BA_ "Prio" BO_ 1148 0;
BA_ "GenMsgDelayTime" BO_ 1148 60;
BA_ "Prio" BO_ 1147 0;
BA_ "GenMsgDelayTime" BO_ 1147 60;
BA_ "Prio" BO_ 1146 0;
BA_ "GenMsgDelayTime" BO_ 1146 60;
BA_ "Prio" BO_ 1143 0;
BA_ "GenMsgDelayTime" BO_ 1143 60;
BA_ "Prio" BO_ 1142 0;
BA_ "GenMsgDelayTime" BO_ 1142 60;
BA_ "Prio" BO_ 1376 0;
BA_ "GenMsgCycleTime" BO_ 1376 100;
BA_ "GenMsgSendType" BO_ 1376 0;
BA_ "Prio" BO_ 851 0;
BA_ "GenMsgDelayTime" BO_ 851 55;
BA_ "Prio" BO_ 850 0;
BA_ "GenMsgDelayTime" BO_ 850 55;
BA_ "SignalType" SG_ 1323 FwdFusTrkB11DynProp "ENM";
BA_ "SignalLongName" SG_ 1323 FwdFusTrkB11DynProp "Forward Fusion Track B11 Dynamic Property";
BA_ "VNSigAllNodes" SG_ 1323 FwdFusTrkB11DynProp 1;
BA_ "SignalType" SG_ 1323 FwdFusTrkB11RelLnAccl "SNM";
BA_ "SignalLongName" SG_ 1323 FwdFusTrkB11RelLnAccl "Forward Fusion Track B11 Relative Lane Acceleration";
BA_ "VNSigAllNodes" SG_ 1323 FwdFusTrkB11RelLnAccl 1;
BA_ "SignalType" SG_ 1323 FwdFusTrkB11RelLane "ENM";
BA_ "SignalLongName" SG_ 1323 FwdFusTrkB11RelLane "Forward Fusion Track B11 Relative Lane";
BA_ "VNSigAllNodes" SG_ 1323 FwdFusTrkB11RelLane 1;
BA_ "SignalType" SG_ 1323 FwdFusTrkB11Height "UNM";
BA_ "SignalLongName" SG_ 1323 FwdFusTrkB11Height "Forward Fusion Track B11 Height";
BA_ "GenSigStartValue" SG_ 1323 FwdFusTrkB11Height 1;
BA_ "VNSigAllNodes" SG_ 1323 FwdFusTrkB11Height 1;
BA_ "SignalType" SG_ 1323 FFusTrkB11ObjSrcLFSrr "ENM";
BA_ "SignalLongName" SG_ 1323 FFusTrkB11ObjSrcLFSrr "Forward Fusion Track B11 Object Source LFSRR";
BA_ "VNSigAllNodes" SG_ 1323 FFusTrkB11ObjSrcLFSrr 1;
BA_ "SignalType" SG_ 1323 FFusTrkB11ObjSrcLCSrr "ENM";
BA_ "SignalLongName" SG_ 1323 FFusTrkB11ObjSrcLCSrr "Forward Fusion Track B11 Object Source LCSRR";
BA_ "VNSigAllNodes" SG_ 1323 FFusTrkB11ObjSrcLCSrr 1;
BA_ "SignalType" SG_ 1323 FFusTrkB11ObjSrcRCSrr "ENM";
BA_ "SignalLongName" SG_ 1323 FFusTrkB11ObjSrcRCSrr "Forward Fusion Track B11 Object Source RCSRR";
BA_ "VNSigAllNodes" SG_ 1323 FFusTrkB11ObjSrcRCSrr 1;
BA_ "SignalType" SG_ 1323 FFusTrkB11ObjSrcRFSrr "ENM";
BA_ "SignalLongName" SG_ 1323 FFusTrkB11ObjSrcRFSrr "Forward Fusion Track B11 Object Source RFSRR";
BA_ "VNSigAllNodes" SG_ 1323 FFusTrkB11ObjSrcRFSrr 1;
BA_ "SignalType" SG_ 1323 FFusTrkB11ObjSrcVIs "ENM";
BA_ "SignalLongName" SG_ 1323 FFusTrkB11ObjSrcVIs "Forward Fusion Track B11 Object Source VIS";
BA_ "VNSigAllNodes" SG_ 1323 FFusTrkB11ObjSrcVIs 1;
BA_ "SignalType" SG_ 1323 FwdFusTrkB11ObjSrcLrr "ENM";
BA_ "SignalLongName" SG_ 1323 FwdFusTrkB11ObjSrcLrr "Forward Fusion Track B11 Object Source LRR";
BA_ "VNSigAllNodes" SG_ 1323 FwdFusTrkB11ObjSrcLrr 1;
BA_ "SignalType" SG_ 1323 FwdFusTrkB11NmCycTrkd "UNM";
BA_ "SignalLongName" SG_ 1323 FwdFusTrkB11NmCycTrkd "Forward Fusion Track B11 Number of Cycles Tracked";
BA_ "VNSigAllNodes" SG_ 1323 FwdFusTrkB11NmCycTrkd 1;
BA_ "SignalType" SG_ 1323 FwdFusTrkB11LatPosDev "UNM";
BA_ "SignalLongName" SG_ 1323 FwdFusTrkB11LatPosDev "Forward Fusion Track B11 Lateral Positiion Deviation";
BA_ "VNSigAllNodes" SG_ 1323 FwdFusTrkB11LatPosDev 1;
BA_ "SignalType" SG_ 1323 FwdFusTrkB11LngPosDev "UNM";
BA_ "SignalLongName" SG_ 1323 FwdFusTrkB11LngPosDev "Forward Fusion Track B11 Longitudinal Position Deviation";
BA_ "VNSigAllNodes" SG_ 1323 FwdFusTrkB11LngPosDev 1;
BA_ "SignalType" SG_ 1323 FwdFusTrkBAnlgRlLn11 "SNM";
BA_ "SignalLongName" SG_ 1323 FwdFusTrkBAnlgRlLn11 "Fwd Fusion Track B Analog relative Lane 11";
BA_ "VNSigAllNodes" SG_ 1323 FwdFusTrkBAnlgRlLn11 1;
BA_ "SignalType" SG_ 1323 FwdFusTrkB11RollingCnt "UNM";
BA_ "SignalLongName" SG_ 1323 FwdFusTrkB11RollingCnt "Forward Fusion Track B11 Rolling Count";
BA_ "VNSigAllNodes" SG_ 1323 FwdFusTrkB11RollingCnt 1;
BA_ "SignalType" SG_ 1323 FwdFusTrkB11Width "UNM";
BA_ "SignalLongName" SG_ 1323 FwdFusTrkB11Width "Forward Fusion Track B11 Width";
BA_ "GenSigStartValue" SG_ 1323 FwdFusTrkB11Width 1;
BA_ "VNSigAllNodes" SG_ 1323 FwdFusTrkB11Width 1;
BA_ "SignalType" SG_ 1323 FwdFusTrkB11MsgIndex "UNM";
BA_ "SignalLongName" SG_ 1323 FwdFusTrkB11MsgIndex "Forward Fusion Track B11 Message Index";
BA_ "VNSigAllNodes" SG_ 1323 FwdFusTrkB11MsgIndex 1;
BA_ "SignalType" SG_ 1322 FwdFusTrkBAnlgRlLn10 "SNM";
BA_ "SignalLongName" SG_ 1322 FwdFusTrkBAnlgRlLn10 "Fwd Fusion Track B Analog relative Lane 10";
BA_ "VNSigAllNodes" SG_ 1322 FwdFusTrkBAnlgRlLn10 1;
BA_ "SignalType" SG_ 1322 FwdFusTrkB10RollingCnt "UNM";
BA_ "SignalLongName" SG_ 1322 FwdFusTrkB10RollingCnt "Forward Fusion Track B10 Rolling Count";
BA_ "VNSigAllNodes" SG_ 1322 FwdFusTrkB10RollingCnt 1;
BA_ "SignalType" SG_ 1322 FwdFusTrkB10Width "UNM";
BA_ "SignalLongName" SG_ 1322 FwdFusTrkB10Width "Forward Fusion Track B10 Width";
BA_ "GenSigStartValue" SG_ 1322 FwdFusTrkB10Width 1;
BA_ "VNSigAllNodes" SG_ 1322 FwdFusTrkB10Width 1;
BA_ "SignalType" SG_ 1322 FwdFusTrkB10MsgIndex "UNM";
BA_ "SignalLongName" SG_ 1322 FwdFusTrkB10MsgIndex "Forward Fusion Track B10 Message Index";
BA_ "VNSigAllNodes" SG_ 1322 FwdFusTrkB10MsgIndex 1;
BA_ "SignalType" SG_ 1322 FwdFusTrkB10DynProp "ENM";
BA_ "SignalLongName" SG_ 1322 FwdFusTrkB10DynProp "Forward Fusion Track B10 Dynamic Property";
BA_ "VNSigAllNodes" SG_ 1322 FwdFusTrkB10DynProp 1;
BA_ "SignalType" SG_ 1322 FwdFusTrkB10RelLnAccl "SNM";
BA_ "SignalLongName" SG_ 1322 FwdFusTrkB10RelLnAccl "Forward Fusion Track B10 Relative Lane Acceleration";
BA_ "VNSigAllNodes" SG_ 1322 FwdFusTrkB10RelLnAccl 1;
BA_ "SignalType" SG_ 1322 FwdFusTrkB10RelLane "ENM";
BA_ "SignalLongName" SG_ 1322 FwdFusTrkB10RelLane "Forward Fusion Track B10 Relative Lane";
BA_ "VNSigAllNodes" SG_ 1322 FwdFusTrkB10RelLane 1;
BA_ "SignalType" SG_ 1322 FwdFusTrkB10Height "UNM";
BA_ "SignalLongName" SG_ 1322 FwdFusTrkB10Height "Forward Fusion Track B10 Height";
BA_ "GenSigStartValue" SG_ 1322 FwdFusTrkB10Height 1;
BA_ "VNSigAllNodes" SG_ 1322 FwdFusTrkB10Height 1;
BA_ "SignalType" SG_ 1322 FFusTrkB10ObjSrcLFSrr "ENM";
BA_ "SignalLongName" SG_ 1322 FFusTrkB10ObjSrcLFSrr "Forward Fusion Track B10 Object Source LFSRR";
BA_ "VNSigAllNodes" SG_ 1322 FFusTrkB10ObjSrcLFSrr 1;
BA_ "SignalType" SG_ 1322 FFusTrkB10ObjSrcLCSrr "ENM";
BA_ "SignalLongName" SG_ 1322 FFusTrkB10ObjSrcLCSrr "Forward Fusion Track B10 Object Source LCSRR";
BA_ "VNSigAllNodes" SG_ 1322 FFusTrkB10ObjSrcLCSrr 1;
BA_ "SignalType" SG_ 1322 FFusTrkB10ObjSrcRCSrr "ENM";
BA_ "SignalLongName" SG_ 1322 FFusTrkB10ObjSrcRCSrr "Forward Fusion Track B10 Object Source RCSRR";
BA_ "VNSigAllNodes" SG_ 1322 FFusTrkB10ObjSrcRCSrr 1;
BA_ "SignalType" SG_ 1322 FFusTrkB10ObjSrcRFSrr "ENM";
BA_ "SignalLongName" SG_ 1322 FFusTrkB10ObjSrcRFSrr "Forward Fusion Track B10 Object Source RFSRR";
BA_ "VNSigAllNodes" SG_ 1322 FFusTrkB10ObjSrcRFSrr 1;
BA_ "SignalType" SG_ 1322 FFusTrkB10ObjSrcVIs "ENM";
BA_ "SignalLongName" SG_ 1322 FFusTrkB10ObjSrcVIs "Forward Fusion Track B10 Object Source VIS";
BA_ "VNSigAllNodes" SG_ 1322 FFusTrkB10ObjSrcVIs 1;
BA_ "SignalType" SG_ 1322 FwdFusTrkB10ObjSrcLrr "ENM";
BA_ "SignalLongName" SG_ 1322 FwdFusTrkB10ObjSrcLrr "Forward Fusion Track B10 Object Source LRR";
BA_ "VNSigAllNodes" SG_ 1322 FwdFusTrkB10ObjSrcLrr 1;
BA_ "SignalType" SG_ 1322 FwdFusTrkB10NmCycTrkd "UNM";
BA_ "SignalLongName" SG_ 1322 FwdFusTrkB10NmCycTrkd "Forward Fusion Track B10 Number of Cycles Tracked";
BA_ "VNSigAllNodes" SG_ 1322 FwdFusTrkB10NmCycTrkd 1;
BA_ "SignalType" SG_ 1322 FwdFusTrkB10LatPosDev "UNM";
BA_ "SignalLongName" SG_ 1322 FwdFusTrkB10LatPosDev "Forward Fusion Track B10 Lateral Positiion Deviation";
BA_ "VNSigAllNodes" SG_ 1322 FwdFusTrkB10LatPosDev 1;
BA_ "SignalType" SG_ 1322 FwdFusTrkB10LngPosDev "UNM";
BA_ "SignalLongName" SG_ 1322 FwdFusTrkB10LngPosDev "Forward Fusion Track B10 Longitudinal Position Deviation";
BA_ "VNSigAllNodes" SG_ 1322 FwdFusTrkB10LngPosDev 1;
BA_ "SignalType" SG_ 1313 FwdFusTrkBAnlgRlLn1 "SNM";
BA_ "SignalLongName" SG_ 1313 FwdFusTrkBAnlgRlLn1 "Fwd Fusion Track B Analog relative Lane 1";
BA_ "VNSigAllNodes" SG_ 1313 FwdFusTrkBAnlgRlLn1 1;
BA_ "SignalType" SG_ 1313 FwdFusTrkB1RollingCnt "UNM";
BA_ "SignalLongName" SG_ 1313 FwdFusTrkB1RollingCnt "Forward Fusion Track B1 Rolling Count";
BA_ "VNSigAllNodes" SG_ 1313 FwdFusTrkB1RollingCnt 1;
BA_ "SignalType" SG_ 1313 FwdFusTrkB1Width "UNM";
BA_ "SignalLongName" SG_ 1313 FwdFusTrkB1Width "Forward Fusion Track B1Width";
BA_ "GenSigStartValue" SG_ 1313 FwdFusTrkB1Width 1;
BA_ "VNSigAllNodes" SG_ 1313 FwdFusTrkB1Width 1;
BA_ "SignalType" SG_ 1313 FwdFusTrkB1MsgIndex "UNM";
BA_ "SignalLongName" SG_ 1313 FwdFusTrkB1MsgIndex "Forward Fusion Track B1 Message Index";
BA_ "VNSigAllNodes" SG_ 1313 FwdFusTrkB1MsgIndex 1;
BA_ "SignalType" SG_ 1313 FwdFusTrkB1DynProp "ENM";
BA_ "SignalLongName" SG_ 1313 FwdFusTrkB1DynProp "Forward Fusion Track B1 Dynamic Property";
BA_ "VNSigAllNodes" SG_ 1313 FwdFusTrkB1DynProp 1;
BA_ "SignalType" SG_ 1313 FwdFusTrkB1RelLnAccl "SNM";
BA_ "SignalLongName" SG_ 1313 FwdFusTrkB1RelLnAccl "Forward Fusion Track B1 Relative Lane Acceleration";
BA_ "VNSigAllNodes" SG_ 1313 FwdFusTrkB1RelLnAccl 1;
BA_ "SignalType" SG_ 1313 FwdFusTrkB1RelLane "ENM";
BA_ "SignalLongName" SG_ 1313 FwdFusTrkB1RelLane "Forward Fusion Track B1 Relative Lane";
BA_ "VNSigAllNodes" SG_ 1313 FwdFusTrkB1RelLane 1;
BA_ "SignalType" SG_ 1313 FwdFusTrkB1Height "UNM";
BA_ "SignalLongName" SG_ 1313 FwdFusTrkB1Height "Forward Fusion Track B1 Height";
BA_ "GenSigStartValue" SG_ 1313 FwdFusTrkB1Height 1;
BA_ "VNSigAllNodes" SG_ 1313 FwdFusTrkB1Height 1;
BA_ "SignalType" SG_ 1313 FFusTrkB1ObjSrcLFSrr "ENM";
BA_ "SignalLongName" SG_ 1313 FFusTrkB1ObjSrcLFSrr "Forward Fusion Track B1 Object Source LSRR";
BA_ "VNSigAllNodes" SG_ 1313 FFusTrkB1ObjSrcLFSrr 1;
BA_ "SignalType" SG_ 1313 FFusTrkB1ObjSrcLCSrr "ENM";
BA_ "SignalLongName" SG_ 1313 FFusTrkB1ObjSrcLCSrr "Forward Fusion Track B1 Object Source LCSRR";
BA_ "VNSigAllNodes" SG_ 1313 FFusTrkB1ObjSrcLCSrr 1;
BA_ "SignalType" SG_ 1313 FFusTrkB1ObjSrcRCSrr "ENM";
BA_ "SignalLongName" SG_ 1313 FFusTrkB1ObjSrcRCSrr "Forward Fusion Track B1 Object Source RCSrr";
BA_ "VNSigAllNodes" SG_ 1313 FFusTrkB1ObjSrcRCSrr 1;
BA_ "SignalType" SG_ 1313 FFusTrkB1ObjSrcRFSrr "ENM";
BA_ "SignalLongName" SG_ 1313 FFusTrkB1ObjSrcRFSrr "Forward Fusion Track B1 Object Source RFSRR";
BA_ "VNSigAllNodes" SG_ 1313 FFusTrkB1ObjSrcRFSrr 1;
BA_ "SignalType" SG_ 1313 FFusTrkB1ObjSrcVIs "ENM";
BA_ "SignalLongName" SG_ 1313 FFusTrkB1ObjSrcVIs "Forward Fusion Track B1 Object Source VIS";
BA_ "VNSigAllNodes" SG_ 1313 FFusTrkB1ObjSrcVIs 1;
BA_ "SignalType" SG_ 1313 FwdFusTrkB1ObjSrcLrr "ENM";
BA_ "SignalLongName" SG_ 1313 FwdFusTrkB1ObjSrcLrr "Forward Fusion Track B1 Object Source LRR";
BA_ "VNSigAllNodes" SG_ 1313 FwdFusTrkB1ObjSrcLrr 1;
BA_ "SignalType" SG_ 1313 FwdFusTrkB1NmCycTrkd "UNM";
BA_ "SignalLongName" SG_ 1313 FwdFusTrkB1NmCycTrkd "Forward Fusion Track B1 Number of Cycles Tracked";
BA_ "VNSigAllNodes" SG_ 1313 FwdFusTrkB1NmCycTrkd 1;
BA_ "SignalType" SG_ 1313 FwdFusTrkB1LatPosDev "UNM";
BA_ "SignalLongName" SG_ 1313 FwdFusTrkB1LatPosDev "Forward Fusion Track B1 Lateral Positiion Deviation";
BA_ "VNSigAllNodes" SG_ 1313 FwdFusTrkB1LatPosDev 1;
BA_ "SignalType" SG_ 1313 FwdFusTrkB1LngPosDev "UNM";
BA_ "SignalLongName" SG_ 1313 FwdFusTrkB1LngPosDev "Forward Fusion Track B1 Longitudinal Position Deviation";
BA_ "VNSigAllNodes" SG_ 1313 FwdFusTrkB1LngPosDev 1;
BA_ "SignalType" SG_ 1305 FwdFusTrkA9RollingCnt "UNM";
BA_ "SignalLongName" SG_ 1305 FwdFusTrkA9RollingCnt "Forward Fusion Track A9 Rolling Count";
BA_ "VNSigAllNodes" SG_ 1305 FwdFusTrkA9RollingCnt 1;
BA_ "SignalType" SG_ 1305 FwdFusTrkA9ObjectID "UNM";
BA_ "SignalLongName" SG_ 1305 FwdFusTrkA9ObjectID "Forward Fusion Track A9 Object ID";
BA_ "VNSigAllNodes" SG_ 1305 FwdFusTrkA9ObjectID 1;
BA_ "SignalType" SG_ 1305 FwdFusTrkA9MsgIndex "UNM";
BA_ "SignalLongName" SG_ 1305 FwdFusTrkA9MsgIndex "Forward Fusion Track A9 Message Index";
BA_ "VNSigAllNodes" SG_ 1305 FwdFusTrkA9MsgIndex 1;
BA_ "SignalType" SG_ 1305 FwdFusTrkA9LongPos "SNM";
BA_ "SignalLongName" SG_ 1305 FwdFusTrkA9LongPos "Forward Fusion Track A9 Longitudinal Position";
BA_ "VNSigAllNodes" SG_ 1305 FwdFusTrkA9LongPos 1;
BA_ "SignalType" SG_ 1305 FwdFusTrkA9RelLongVel "SNM";
BA_ "SignalLongName" SG_ 1305 FwdFusTrkA9RelLongVel "Forward Fusion Track A9 Relative Longitudinal Velocity";
BA_ "VNSigAllNodes" SG_ 1305 FwdFusTrkA9RelLongVel 1;
BA_ "SignalType" SG_ 1305 FwdFusTrkA9Confidence "ENM";
BA_ "SignalLongName" SG_ 1305 FwdFusTrkA9Confidence "Forward Fusion Track A9 Confidence";
BA_ "VNSigAllNodes" SG_ 1305 FwdFusTrkA9Confidence 1;
BA_ "SignalType" SG_ 1305 FwdFusTrkA9LatPos "SNM";
BA_ "SignalLongName" SG_ 1305 FwdFusTrkA9LatPos "Forward Fusion Track A9 Lateral Position";
BA_ "VNSigAllNodes" SG_ 1305 FwdFusTrkA9LatPos 1;
BA_ "SignalType" SG_ 1305 FwdFusTrkA9RelLatVel "SNM";
BA_ "SignalLongName" SG_ 1305 FwdFusTrkA9RelLatVel "Forward Fusion Track A9 Relative Lateral Velocity";
BA_ "VNSigAllNodes" SG_ 1305 FwdFusTrkA9RelLatVel 1;
BA_ "SignalType" SG_ 1305 FwdFusTrkA9MeasStatus "ENM";
BA_ "SignalLongName" SG_ 1305 FwdFusTrkA9MeasStatus "Forward Fusion Track A9 Measurement Status";
BA_ "VNSigAllNodes" SG_ 1305 FwdFusTrkA9MeasStatus 1;
BA_ "SignalType" SG_ 1305 FwdFusTrkA9ObjType "ENM";
BA_ "SignalLongName" SG_ 1305 FwdFusTrkA9ObjType "Forward Fusion Track A9 Object Type";
BA_ "VNSigAllNodes" SG_ 1305 FwdFusTrkA9ObjType 1;
BA_ "SignalType" SG_ 1304 FwdFusTrkA8RollingCnt "UNM";
BA_ "SignalLongName" SG_ 1304 FwdFusTrkA8RollingCnt "Forward Fusion Track A8 Rolling Count";
BA_ "VNSigAllNodes" SG_ 1304 FwdFusTrkA8RollingCnt 1;
BA_ "SignalType" SG_ 1304 FwdFusTrkA8ObjectID "UNM";
BA_ "SignalLongName" SG_ 1304 FwdFusTrkA8ObjectID "Forward Fusion Track A8 Object ID";
BA_ "VNSigAllNodes" SG_ 1304 FwdFusTrkA8ObjectID 1;
BA_ "SignalType" SG_ 1304 FwdFusTrkA8MsgIndex "UNM";
BA_ "SignalLongName" SG_ 1304 FwdFusTrkA8MsgIndex "Forward Fusion Track A8 Message Index";
BA_ "VNSigAllNodes" SG_ 1304 FwdFusTrkA8MsgIndex 1;
BA_ "SignalType" SG_ 1304 FwdFusTrkA8LongPos "SNM";
BA_ "SignalLongName" SG_ 1304 FwdFusTrkA8LongPos "Forward Fusion Track A8 Longitudinal Position";
BA_ "VNSigAllNodes" SG_ 1304 FwdFusTrkA8LongPos 1;
BA_ "SignalType" SG_ 1304 FwdFusTrkA8RelLongVel "SNM";
BA_ "SignalLongName" SG_ 1304 FwdFusTrkA8RelLongVel "Forward Fusion Track A8 Relative Longitudinal Velocity";
BA_ "VNSigAllNodes" SG_ 1304 FwdFusTrkA8RelLongVel 1;
BA_ "SignalType" SG_ 1304 FwdFusTrkA8Confidence "ENM";
BA_ "SignalLongName" SG_ 1304 FwdFusTrkA8Confidence "Forward Fusion Track A8 Confidence";
BA_ "VNSigAllNodes" SG_ 1304 FwdFusTrkA8Confidence 1;
BA_ "SignalType" SG_ 1304 FwdFusTrkA8LatPos "SNM";
BA_ "SignalLongName" SG_ 1304 FwdFusTrkA8LatPos "Forward Fusion Track A8 Lateral Position";
BA_ "VNSigAllNodes" SG_ 1304 FwdFusTrkA8LatPos 1;
BA_ "SignalType" SG_ 1304 FwdFusTrkA8RelLatVel "SNM";
BA_ "SignalLongName" SG_ 1304 FwdFusTrkA8RelLatVel "Forward Fusion Track A8 Relative Lateral Velocity";
BA_ "VNSigAllNodes" SG_ 1304 FwdFusTrkA8RelLatVel 1;
BA_ "SignalType" SG_ 1304 FwdFusTrkA8MeasStatus "ENM";
BA_ "SignalLongName" SG_ 1304 FwdFusTrkA8MeasStatus "Forward Fusion Track A8 Measurement Status";
BA_ "VNSigAllNodes" SG_ 1304 FwdFusTrkA8MeasStatus 1;
BA_ "SignalType" SG_ 1304 FwdFusTrkA8ObjType "ENM";
BA_ "SignalLongName" SG_ 1304 FwdFusTrkA8ObjType "Forward Fusion Track A8 Object Type";
BA_ "VNSigAllNodes" SG_ 1304 FwdFusTrkA8ObjType 1;
BA_ "SignalType" SG_ 1303 FwdFusTrkA7RollingCnt "UNM";
BA_ "SignalLongName" SG_ 1303 FwdFusTrkA7RollingCnt "Forward Fusion Track A7 Rolling Count";
BA_ "VNSigAllNodes" SG_ 1303 FwdFusTrkA7RollingCnt 1;
BA_ "SignalType" SG_ 1303 FwdFusTrkA7ObjectID "UNM";
BA_ "SignalLongName" SG_ 1303 FwdFusTrkA7ObjectID "Forward Fusion Track A7 Object ID";
BA_ "VNSigAllNodes" SG_ 1303 FwdFusTrkA7ObjectID 1;
BA_ "SignalType" SG_ 1303 FwdFusTrkA7MsgIndex "UNM";
BA_ "SignalLongName" SG_ 1303 FwdFusTrkA7MsgIndex "Forward Fusion Track A7 Message Index";
BA_ "VNSigAllNodes" SG_ 1303 FwdFusTrkA7MsgIndex 1;
BA_ "SignalType" SG_ 1303 FwdFusTrkA7LongPos "SNM";
BA_ "SignalLongName" SG_ 1303 FwdFusTrkA7LongPos "Forward Fusion Track A7 Longitudinal Position";
BA_ "VNSigAllNodes" SG_ 1303 FwdFusTrkA7LongPos 1;
BA_ "SignalType" SG_ 1303 FwdFusTrkA7RelLongVel "SNM";
BA_ "SignalLongName" SG_ 1303 FwdFusTrkA7RelLongVel "Forward Fusion Track A7 Relative Longitudinal Velocity";
BA_ "VNSigAllNodes" SG_ 1303 FwdFusTrkA7RelLongVel 1;
BA_ "SignalType" SG_ 1303 FwdFusTrkA7Confidence "ENM";
BA_ "SignalLongName" SG_ 1303 FwdFusTrkA7Confidence "Forward Fusion Track A7 Confidence";
BA_ "VNSigAllNodes" SG_ 1303 FwdFusTrkA7Confidence 1;
BA_ "SignalType" SG_ 1303 FwdFusTrkA7LatPos "SNM";
BA_ "SignalLongName" SG_ 1303 FwdFusTrkA7LatPos "Forward Fusion Track A7 Lateral Position";
BA_ "VNSigAllNodes" SG_ 1303 FwdFusTrkA7LatPos 1;
BA_ "SignalType" SG_ 1303 FwdFusTrkA7RelLatVel "SNM";
BA_ "SignalLongName" SG_ 1303 FwdFusTrkA7RelLatVel "Forward Fusion Track A7 Relative Lateral Velocity";
BA_ "VNSigAllNodes" SG_ 1303 FwdFusTrkA7RelLatVel 1;
BA_ "SignalType" SG_ 1303 FwdFusTrkA7MeasStatus "ENM";
BA_ "SignalLongName" SG_ 1303 FwdFusTrkA7MeasStatus "Forward Fusion Track A7 Measurement Status";
BA_ "VNSigAllNodes" SG_ 1303 FwdFusTrkA7MeasStatus 1;
BA_ "SignalType" SG_ 1303 FwdFusTrkA7ObjType "ENM";
BA_ "SignalLongName" SG_ 1303 FwdFusTrkA7ObjType "Forward Fusion Track A7 Object Type";
BA_ "VNSigAllNodes" SG_ 1303 FwdFusTrkA7ObjType 1;
BA_ "SignalType" SG_ 1302 FwdFusTrkA6RollingCnt "UNM";
BA_ "SignalLongName" SG_ 1302 FwdFusTrkA6RollingCnt "Forward Fusion Track A6 Rolling Count";
BA_ "VNSigAllNodes" SG_ 1302 FwdFusTrkA6RollingCnt 1;
BA_ "SignalType" SG_ 1302 FwdFusTrkA6ObjectID "UNM";
BA_ "SignalLongName" SG_ 1302 FwdFusTrkA6ObjectID "Forward Fusion Track A6 Object ID";
BA_ "VNSigAllNodes" SG_ 1302 FwdFusTrkA6ObjectID 1;
BA_ "SignalType" SG_ 1302 FwdFusTrkA6MsgIndex "UNM";
BA_ "SignalLongName" SG_ 1302 FwdFusTrkA6MsgIndex "Forward Fusion Track A6 Message Index";
BA_ "VNSigAllNodes" SG_ 1302 FwdFusTrkA6MsgIndex 1;
BA_ "SignalType" SG_ 1302 FwdFusTrkA6LongPos "SNM";
BA_ "SignalLongName" SG_ 1302 FwdFusTrkA6LongPos "Forward Fusion Track A6 Longitudinal Position";
BA_ "VNSigAllNodes" SG_ 1302 FwdFusTrkA6LongPos 1;
BA_ "SignalType" SG_ 1302 FwdFusTrkA6RelLongVel "SNM";
BA_ "SignalLongName" SG_ 1302 FwdFusTrkA6RelLongVel "Forward Fusion Track A6 Relative Longitudinal Velocity";
BA_ "VNSigAllNodes" SG_ 1302 FwdFusTrkA6RelLongVel 1;
BA_ "SignalType" SG_ 1302 FwdFusTrkA6Confidence "ENM";
BA_ "SignalLongName" SG_ 1302 FwdFusTrkA6Confidence "Forward Fusion Track A6 Confidence";
BA_ "VNSigAllNodes" SG_ 1302 FwdFusTrkA6Confidence 1;
BA_ "SignalType" SG_ 1302 FwdFusTrkA6LatPos "SNM";
BA_ "SignalLongName" SG_ 1302 FwdFusTrkA6LatPos "Forward Fusion Track A6 Lateral Position";
BA_ "VNSigAllNodes" SG_ 1302 FwdFusTrkA6LatPos 1;
BA_ "SignalType" SG_ 1302 FwdFusTrkA6RelLatVel "SNM";
BA_ "SignalLongName" SG_ 1302 FwdFusTrkA6RelLatVel "Forward Fusion Track A6 Relative Lateral Velocity";
BA_ "VNSigAllNodes" SG_ 1302 FwdFusTrkA6RelLatVel 1;
BA_ "SignalType" SG_ 1302 FwdFusTrkA6MeasStatus "ENM";
BA_ "SignalLongName" SG_ 1302 FwdFusTrkA6MeasStatus "Forward Fusion Track A6 Measurement Status";
BA_ "VNSigAllNodes" SG_ 1302 FwdFusTrkA6MeasStatus 1;
BA_ "SignalType" SG_ 1302 FwdFusTrkA6ObjType "ENM";
BA_ "SignalLongName" SG_ 1302 FwdFusTrkA6ObjType "Forward Fusion Track A6 Object Type";
BA_ "VNSigAllNodes" SG_ 1302 FwdFusTrkA6ObjType 1;
BA_ "SignalType" SG_ 1301 FwdFusTrkA5RollingCnt "UNM";
BA_ "SignalLongName" SG_ 1301 FwdFusTrkA5RollingCnt "Forward Fusion Track A5 Rolling Count";
BA_ "VNSigAllNodes" SG_ 1301 FwdFusTrkA5RollingCnt 1;
BA_ "SignalType" SG_ 1301 FwdFusTrkA5ObjectID "UNM";
BA_ "SignalLongName" SG_ 1301 FwdFusTrkA5ObjectID "Forward Fusion Track A5 Object ID";
BA_ "VNSigAllNodes" SG_ 1301 FwdFusTrkA5ObjectID 1;
BA_ "SignalType" SG_ 1301 FwdFusTrkA5MsgIndex "UNM";
BA_ "SignalLongName" SG_ 1301 FwdFusTrkA5MsgIndex "Forward Fusion Track A5 Message Index";
BA_ "VNSigAllNodes" SG_ 1301 FwdFusTrkA5MsgIndex 1;
BA_ "SignalType" SG_ 1301 FwdFusTrkA5LongPos "SNM";
BA_ "SignalLongName" SG_ 1301 FwdFusTrkA5LongPos "Forward Fusion Track A5 Longitudinal Position";
BA_ "VNSigAllNodes" SG_ 1301 FwdFusTrkA5LongPos 1;
BA_ "SignalType" SG_ 1301 FwdFusTrkA5RelLongVel "SNM";
BA_ "SignalLongName" SG_ 1301 FwdFusTrkA5RelLongVel "Forward Fusion Track A5 Relative Longitudinal Velocity";
BA_ "VNSigAllNodes" SG_ 1301 FwdFusTrkA5RelLongVel 1;
BA_ "SignalType" SG_ 1301 FwdFusTrkA5Confidence "ENM";
BA_ "SignalLongName" SG_ 1301 FwdFusTrkA5Confidence "Forward Fusion Track A5 Confidence";
BA_ "VNSigAllNodes" SG_ 1301 FwdFusTrkA5Confidence 1;
BA_ "SignalType" SG_ 1301 FwdFusTrkA5LatPos "SNM";
BA_ "SignalLongName" SG_ 1301 FwdFusTrkA5LatPos "Forward Fusion Track A5 Lateral Position";
BA_ "VNSigAllNodes" SG_ 1301 FwdFusTrkA5LatPos 1;
BA_ "SignalType" SG_ 1301 FwdFusTrkA5RelLatVel "SNM";
BA_ "SignalLongName" SG_ 1301 FwdFusTrkA5RelLatVel "Forward Fusion Track A5 Relative Lateral Velocity";
BA_ "VNSigAllNodes" SG_ 1301 FwdFusTrkA5RelLatVel 1;
BA_ "SignalType" SG_ 1301 FwdFusTrkA5MeasStatus "ENM";
BA_ "SignalLongName" SG_ 1301 FwdFusTrkA5MeasStatus "Forward Fusion Track A5 Measurement Status";
BA_ "VNSigAllNodes" SG_ 1301 FwdFusTrkA5MeasStatus 1;
BA_ "SignalType" SG_ 1301 FwdFusTrkA5ObjType "ENM";
BA_ "SignalLongName" SG_ 1301 FwdFusTrkA5ObjType "Forward Fusion Track A5 Object Type";
BA_ "VNSigAllNodes" SG_ 1301 FwdFusTrkA5ObjType 1;
BA_ "SignalType" SG_ 1300 FwdFusTrkA4RollingCnt "UNM";
BA_ "SignalLongName" SG_ 1300 FwdFusTrkA4RollingCnt "Forward Fusion Track A4 Rolling Count";
BA_ "VNSigAllNodes" SG_ 1300 FwdFusTrkA4RollingCnt 1;
BA_ "SignalType" SG_ 1300 FwdFusTrkA4ObjectID "UNM";
BA_ "SignalLongName" SG_ 1300 FwdFusTrkA4ObjectID "Forward Fusion Track A4 Object ID";
BA_ "VNSigAllNodes" SG_ 1300 FwdFusTrkA4ObjectID 1;
BA_ "SignalType" SG_ 1300 FwdFusTrkA4MsgIndex "UNM";
BA_ "SignalLongName" SG_ 1300 FwdFusTrkA4MsgIndex "Forward Fusion Track A4 Message Index";
BA_ "VNSigAllNodes" SG_ 1300 FwdFusTrkA4MsgIndex 1;
BA_ "SignalType" SG_ 1300 FwdFusTrkA4LongPos "SNM";
BA_ "SignalLongName" SG_ 1300 FwdFusTrkA4LongPos "Forward Fusion Track A4 Longitudinal Position";
BA_ "VNSigAllNodes" SG_ 1300 FwdFusTrkA4LongPos 1;
BA_ "SignalType" SG_ 1300 FwdFusTrkA4RelLongVel "SNM";
BA_ "SignalLongName" SG_ 1300 FwdFusTrkA4RelLongVel "Forward Fusion Track A4 Relative Longitudinal Velocity";
BA_ "VNSigAllNodes" SG_ 1300 FwdFusTrkA4RelLongVel 1;
BA_ "SignalType" SG_ 1300 FwdFusTrkA4Confidence "ENM";
BA_ "SignalLongName" SG_ 1300 FwdFusTrkA4Confidence "Forward Fusion Track A4 Confidence";
BA_ "VNSigAllNodes" SG_ 1300 FwdFusTrkA4Confidence 1;
BA_ "SignalType" SG_ 1300 FwdFusTrkA4LatPos "SNM";
BA_ "SignalLongName" SG_ 1300 FwdFusTrkA4LatPos "Forward Fusion Track A4 Lateral Position";
BA_ "VNSigAllNodes" SG_ 1300 FwdFusTrkA4LatPos 1;
BA_ "SignalType" SG_ 1300 FwdFusTrkA4RelLatVel "SNM";
BA_ "SignalLongName" SG_ 1300 FwdFusTrkA4RelLatVel "Forward Fusion Track A4 Relative Lateral Velocity";
BA_ "VNSigAllNodes" SG_ 1300 FwdFusTrkA4RelLatVel 1;
BA_ "SignalType" SG_ 1300 FwdFusTrkA4MeasStatus "ENM";
BA_ "SignalLongName" SG_ 1300 FwdFusTrkA4MeasStatus "Forward Fusion Track A4 Measurement Status";
BA_ "VNSigAllNodes" SG_ 1300 FwdFusTrkA4MeasStatus 1;
BA_ "SignalType" SG_ 1300 FwdFusTrkA4ObjType "ENM";
BA_ "SignalLongName" SG_ 1300 FwdFusTrkA4ObjType "Forward Fusion Track A4 Object Type";
BA_ "VNSigAllNodes" SG_ 1300 FwdFusTrkA4ObjType 1;
BA_ "SignalType" SG_ 1299 FwdFusTrkA3RollingCnt "UNM";
BA_ "SignalLongName" SG_ 1299 FwdFusTrkA3RollingCnt "Forward Fusion Track A3 Rolling Count";
BA_ "VNSigAllNodes" SG_ 1299 FwdFusTrkA3RollingCnt 1;
BA_ "SignalType" SG_ 1299 FwdFusTrkA3ObjectID "UNM";
BA_ "SignalLongName" SG_ 1299 FwdFusTrkA3ObjectID "Forward Fusion Track A3 Object ID";
BA_ "VNSigAllNodes" SG_ 1299 FwdFusTrkA3ObjectID 1;
BA_ "SignalType" SG_ 1299 FwdFusTrkA3MsgIndex "UNM";
BA_ "SignalLongName" SG_ 1299 FwdFusTrkA3MsgIndex "Forward Fusion Track A3 Message Index";
BA_ "VNSigAllNodes" SG_ 1299 FwdFusTrkA3MsgIndex 1;
BA_ "SignalType" SG_ 1299 FwdFusTrkA3LongPos "SNM";
BA_ "SignalLongName" SG_ 1299 FwdFusTrkA3LongPos "Forward Fusion Track A3 Longitudinal Position";
BA_ "VNSigAllNodes" SG_ 1299 FwdFusTrkA3LongPos 1;
BA_ "SignalType" SG_ 1299 FwdFusTrkA3RelLongVel "SNM";
BA_ "SignalLongName" SG_ 1299 FwdFusTrkA3RelLongVel "Forward Fusion Track A3 Relative Longitudinal Velocity";
BA_ "VNSigAllNodes" SG_ 1299 FwdFusTrkA3RelLongVel 1;
BA_ "SignalType" SG_ 1299 FwdFusTrkA3Confidence "ENM";
BA_ "SignalLongName" SG_ 1299 FwdFusTrkA3Confidence "Forward Fusion Track A3 Confidence";
BA_ "VNSigAllNodes" SG_ 1299 FwdFusTrkA3Confidence 1;
BA_ "SignalType" SG_ 1299 FwdFusTrkA3LatPos "SNM";
BA_ "SignalLongName" SG_ 1299 FwdFusTrkA3LatPos "Forward Fusion Track A3 Lateral Position";
BA_ "VNSigAllNodes" SG_ 1299 FwdFusTrkA3LatPos 1;
BA_ "SignalType" SG_ 1299 FwdFusTrkA3RelLatVel "SNM";
BA_ "SignalLongName" SG_ 1299 FwdFusTrkA3RelLatVel "Forward Fusion Track A3 Relative Lateral Velocity";
BA_ "VNSigAllNodes" SG_ 1299 FwdFusTrkA3RelLatVel 1;
BA_ "SignalType" SG_ 1299 FwdFusTrkA3MeasStatus "ENM";
BA_ "SignalLongName" SG_ 1299 FwdFusTrkA3MeasStatus "Forward Fusion Track A3 Measurement Status";
BA_ "VNSigAllNodes" SG_ 1299 FwdFusTrkA3MeasStatus 1;
BA_ "SignalType" SG_ 1299 FwdFusTrkA3ObjType "ENM";
BA_ "SignalLongName" SG_ 1299 FwdFusTrkA3ObjType "Forward Fusion Track A3 Object Type";
BA_ "VNSigAllNodes" SG_ 1299 FwdFusTrkA3ObjType 1;
BA_ "SignalType" SG_ 1298 FwdFusTrkA2RollingCnt "UNM";
BA_ "SignalLongName" SG_ 1298 FwdFusTrkA2RollingCnt "Forward Fusion Track A2 Rolling Count";
BA_ "VNSigAllNodes" SG_ 1298 FwdFusTrkA2RollingCnt 1;
BA_ "SignalType" SG_ 1298 FwdFusTrkA2ObjectID "UNM";
BA_ "SignalLongName" SG_ 1298 FwdFusTrkA2ObjectID "Forward Fusion Track A2 Object ID";
BA_ "VNSigAllNodes" SG_ 1298 FwdFusTrkA2ObjectID 1;
BA_ "SignalType" SG_ 1298 FwdFusTrkA2MsgIndex "UNM";
BA_ "SignalLongName" SG_ 1298 FwdFusTrkA2MsgIndex "Forward Fusion Track A2 Message Index";
BA_ "VNSigAllNodes" SG_ 1298 FwdFusTrkA2MsgIndex 1;
BA_ "SignalType" SG_ 1298 FwdFusTrkA2LongPos "SNM";
BA_ "SignalLongName" SG_ 1298 FwdFusTrkA2LongPos "Forward Fusion Track A2 Longitudinal Position";
BA_ "VNSigAllNodes" SG_ 1298 FwdFusTrkA2LongPos 1;
BA_ "SignalType" SG_ 1298 FwdFusTrkA2RelLongVel "SNM";
BA_ "SignalLongName" SG_ 1298 FwdFusTrkA2RelLongVel "Forward Fusion Track A2 Relative Longitudinal Velocity";
BA_ "VNSigAllNodes" SG_ 1298 FwdFusTrkA2RelLongVel 1;
BA_ "SignalType" SG_ 1298 FwdFusTrkA2Confidence "ENM";
BA_ "SignalLongName" SG_ 1298 FwdFusTrkA2Confidence "Forward Fusion Track A2 Confidence";
BA_ "VNSigAllNodes" SG_ 1298 FwdFusTrkA2Confidence 1;
BA_ "SignalType" SG_ 1298 FwdFusTrkA2LatPos "SNM";
BA_ "SignalLongName" SG_ 1298 FwdFusTrkA2LatPos "Forward Fusion Track A2 Lateral Position";
BA_ "VNSigAllNodes" SG_ 1298 FwdFusTrkA2LatPos 1;
BA_ "SignalType" SG_ 1298 FwdFusTrkA2RelLatVel "SNM";
BA_ "SignalLongName" SG_ 1298 FwdFusTrkA2RelLatVel "Forward Fusion Track A2 Relative Lateral Velocity";
BA_ "VNSigAllNodes" SG_ 1298 FwdFusTrkA2RelLatVel 1;
BA_ "SignalType" SG_ 1298 FwdFusTrkA2MeasStatus "ENM";
BA_ "SignalLongName" SG_ 1298 FwdFusTrkA2MeasStatus "Forward Fusion Track A2 Measurement Status";
BA_ "VNSigAllNodes" SG_ 1298 FwdFusTrkA2MeasStatus 1;
BA_ "SignalType" SG_ 1298 FwdFusTrkA2ObjType "ENM";
BA_ "SignalLongName" SG_ 1298 FwdFusTrkA2ObjType "Forward Fusion Track A2 Object Type";
BA_ "VNSigAllNodes" SG_ 1298 FwdFusTrkA2ObjType 1;
BA_ "SignalType" SG_ 1311 FwdFusTrkA15RollingCnt "UNM";
BA_ "SignalLongName" SG_ 1311 FwdFusTrkA15RollingCnt "Forward Fusion Track A15 Rolling Count";
BA_ "VNSigAllNodes" SG_ 1311 FwdFusTrkA15RollingCnt 1;
BA_ "SignalType" SG_ 1311 FwdFusTrkA15ObjectID "UNM";
BA_ "SignalLongName" SG_ 1311 FwdFusTrkA15ObjectID "Forward Fusion Track A15 Object ID";
BA_ "VNSigAllNodes" SG_ 1311 FwdFusTrkA15ObjectID 1;
BA_ "SignalType" SG_ 1311 FwdFusTrkA15MsgIndex "UNM";
BA_ "SignalLongName" SG_ 1311 FwdFusTrkA15MsgIndex "Forward Fusion Track A15 Message Index";
BA_ "VNSigAllNodes" SG_ 1311 FwdFusTrkA15MsgIndex 1;
BA_ "SignalType" SG_ 1311 FwdFusTrkA15LongPos "SNM";
BA_ "SignalLongName" SG_ 1311 FwdFusTrkA15LongPos "Forward Fusion Track A15 Longitudinal Position";
BA_ "VNSigAllNodes" SG_ 1311 FwdFusTrkA15LongPos 1;
BA_ "SignalType" SG_ 1311 FwdFusTrkA15RelLongVel "SNM";
BA_ "SignalLongName" SG_ 1311 FwdFusTrkA15RelLongVel "Forward Fusion Track A15 Relative Longitudinal Velocity";
BA_ "VNSigAllNodes" SG_ 1311 FwdFusTrkA15RelLongVel 1;
BA_ "SignalType" SG_ 1311 FwdFusTrkA15Confidence "ENM";
BA_ "SignalLongName" SG_ 1311 FwdFusTrkA15Confidence "Forward Fusion Track A15 Confidence";
BA_ "VNSigAllNodes" SG_ 1311 FwdFusTrkA15Confidence 1;
BA_ "SignalType" SG_ 1311 FwdFusTrkA15LatPos "SNM";
BA_ "SignalLongName" SG_ 1311 FwdFusTrkA15LatPos "Forward Fusion Track A15 Lateral Position";
BA_ "VNSigAllNodes" SG_ 1311 FwdFusTrkA15LatPos 1;
BA_ "SignalType" SG_ 1311 FwdFusTrkA15RelLatVel "SNM";
BA_ "SignalLongName" SG_ 1311 FwdFusTrkA15RelLatVel "Forward Fusion Track A15 Relative Lateral Velocity";
BA_ "VNSigAllNodes" SG_ 1311 FwdFusTrkA15RelLatVel 1;
BA_ "SignalType" SG_ 1311 FwdFusTrkA15MeasStatus "ENM";
BA_ "SignalLongName" SG_ 1311 FwdFusTrkA15MeasStatus "Forward Fusion Track A15 Measurement Status";
BA_ "VNSigAllNodes" SG_ 1311 FwdFusTrkA15MeasStatus 1;
BA_ "SignalType" SG_ 1311 FwdFusTrkA15ObjType "ENM";
BA_ "SignalLongName" SG_ 1311 FwdFusTrkA15ObjType "Forward Fusion Track A15 Object Type";
BA_ "VNSigAllNodes" SG_ 1311 FwdFusTrkA15ObjType 1;
BA_ "SignalType" SG_ 1310 FwdFusTrkA14RollingCnt "UNM";
BA_ "SignalLongName" SG_ 1310 FwdFusTrkA14RollingCnt "Forward Fusion Track A14 Rolling Count";
BA_ "VNSigAllNodes" SG_ 1310 FwdFusTrkA14RollingCnt 1;
BA_ "SignalType" SG_ 1310 FwdFusTrkA14ObjectID "UNM";
BA_ "SignalLongName" SG_ 1310 FwdFusTrkA14ObjectID "Forward Fusion Track A14 Object ID";
BA_ "VNSigAllNodes" SG_ 1310 FwdFusTrkA14ObjectID 1;
BA_ "SignalType" SG_ 1310 FwdFusTrkA14MsgIndex "UNM";
BA_ "SignalLongName" SG_ 1310 FwdFusTrkA14MsgIndex "Forward Fusion Track A14 Message Index";
BA_ "VNSigAllNodes" SG_ 1310 FwdFusTrkA14MsgIndex 1;
BA_ "SignalType" SG_ 1310 FwdFusTrkA14LongPos "SNM";
BA_ "SignalLongName" SG_ 1310 FwdFusTrkA14LongPos "Forward Fusion Track A14 Longitudinal Position";
BA_ "VNSigAllNodes" SG_ 1310 FwdFusTrkA14LongPos 1;
BA_ "SignalType" SG_ 1310 FwdFusTrkA14RelLongVel "SNM";
BA_ "SignalLongName" SG_ 1310 FwdFusTrkA14RelLongVel "Forward Fusion Track A14 Relative Longitudinal Velocity";
BA_ "VNSigAllNodes" SG_ 1310 FwdFusTrkA14RelLongVel 1;
BA_ "SignalType" SG_ 1310 FwdFusTrkA14Confidence "ENM";
BA_ "SignalLongName" SG_ 1310 FwdFusTrkA14Confidence "Forward Fusion Track A14 Confidence";
BA_ "VNSigAllNodes" SG_ 1310 FwdFusTrkA14Confidence 1;
BA_ "SignalType" SG_ 1310 FwdFusTrkA14LatPos "SNM";
BA_ "SignalLongName" SG_ 1310 FwdFusTrkA14LatPos "Forward Fusion Track A14 Lateral Position";
BA_ "VNSigAllNodes" SG_ 1310 FwdFusTrkA14LatPos 1;
BA_ "SignalType" SG_ 1310 FwdFusTrkA14RelLatVel "SNM";
BA_ "SignalLongName" SG_ 1310 FwdFusTrkA14RelLatVel "Forward Fusion Track A14 Relative Lateral Velocity";
BA_ "VNSigAllNodes" SG_ 1310 FwdFusTrkA14RelLatVel 1;
BA_ "SignalType" SG_ 1310 FwdFusTrkA14MeasStatus "ENM";
BA_ "SignalLongName" SG_ 1310 FwdFusTrkA14MeasStatus "Forward Fusion Track A14 Measurement Status";
BA_ "VNSigAllNodes" SG_ 1310 FwdFusTrkA14MeasStatus 1;
BA_ "SignalType" SG_ 1310 FwdFusTrkA14ObjType "ENM";
BA_ "SignalLongName" SG_ 1310 FwdFusTrkA14ObjType "Forward Fusion Track A14 Object Type";
BA_ "VNSigAllNodes" SG_ 1310 FwdFusTrkA14ObjType 1;
BA_ "SignalType" SG_ 1309 FwdFusTrkA13RollingCnt "UNM";
BA_ "SignalLongName" SG_ 1309 FwdFusTrkA13RollingCnt "Forward Fusion Track A13 Rolling Count";
BA_ "VNSigAllNodes" SG_ 1309 FwdFusTrkA13RollingCnt 1;
BA_ "SignalType" SG_ 1309 FwdFusTrkA13ObjectID "UNM";
BA_ "SignalLongName" SG_ 1309 FwdFusTrkA13ObjectID "Forward Fusion Track A13 Object ID";
BA_ "VNSigAllNodes" SG_ 1309 FwdFusTrkA13ObjectID 1;
BA_ "SignalType" SG_ 1309 FwdFusTrkA13MsgIndex "UNM";
BA_ "SignalLongName" SG_ 1309 FwdFusTrkA13MsgIndex "Forward Fusion Track A13 Message Index";
BA_ "VNSigAllNodes" SG_ 1309 FwdFusTrkA13MsgIndex 1;
BA_ "SignalType" SG_ 1309 FwdFusTrkA13LongPos "SNM";
BA_ "SignalLongName" SG_ 1309 FwdFusTrkA13LongPos "Forward Fusion Track A13 Longitudinal Position";
BA_ "VNSigAllNodes" SG_ 1309 FwdFusTrkA13LongPos 1;
BA_ "SignalType" SG_ 1309 FwdFusTrkA13RelLongVel "SNM";
BA_ "SignalLongName" SG_ 1309 FwdFusTrkA13RelLongVel "Forward Fusion Track A13 Relative Longitudinal Velocity";
BA_ "VNSigAllNodes" SG_ 1309 FwdFusTrkA13RelLongVel 1;
BA_ "SignalType" SG_ 1309 FwdFusTrkA13Confidence "ENM";
BA_ "SignalLongName" SG_ 1309 FwdFusTrkA13Confidence "Forward Fusion Track A13 Confidence";
BA_ "VNSigAllNodes" SG_ 1309 FwdFusTrkA13Confidence 1;
BA_ "SignalType" SG_ 1309 FwdFusTrkA13LatPos "SNM";
BA_ "SignalLongName" SG_ 1309 FwdFusTrkA13LatPos "Forward Fusion Track A13 Lateral Position";
BA_ "VNSigAllNodes" SG_ 1309 FwdFusTrkA13LatPos 1;
BA_ "SignalType" SG_ 1309 FwdFusTrkA13RelLatVel "SNM";
BA_ "SignalLongName" SG_ 1309 FwdFusTrkA13RelLatVel "Forward Fusion Track A13 Relative Lateral Velocity";
BA_ "VNSigAllNodes" SG_ 1309 FwdFusTrkA13RelLatVel 1;
BA_ "SignalType" SG_ 1309 FwdFusTrkA13MeasStatus "ENM";
BA_ "SignalLongName" SG_ 1309 FwdFusTrkA13MeasStatus "Forward Fusion Track A13 Measurement Status";
BA_ "VNSigAllNodes" SG_ 1309 FwdFusTrkA13MeasStatus 1;
BA_ "SignalType" SG_ 1309 FwdFusTrkA13ObjType "ENM";
BA_ "SignalLongName" SG_ 1309 FwdFusTrkA13ObjType "Forward Fusion Track A13 Object Type";
BA_ "VNSigAllNodes" SG_ 1309 FwdFusTrkA13ObjType 1;
BA_ "SignalType" SG_ 1308 FwdFusTrkA12RollingCnt "UNM";
BA_ "SignalLongName" SG_ 1308 FwdFusTrkA12RollingCnt "Forward Fusion Track A12 Rolling Count";
BA_ "VNSigAllNodes" SG_ 1308 FwdFusTrkA12RollingCnt 1;
BA_ "SignalType" SG_ 1308 FwdFusTrkA12ObjectID "UNM";
BA_ "SignalLongName" SG_ 1308 FwdFusTrkA12ObjectID "Forward Fusion Track A12 Object ID";
BA_ "VNSigAllNodes" SG_ 1308 FwdFusTrkA12ObjectID 1;
BA_ "SignalType" SG_ 1308 FwdFusTrkA12MsgIndex "UNM";
BA_ "SignalLongName" SG_ 1308 FwdFusTrkA12MsgIndex "Forward Fusion Track A12 Message Index";
BA_ "VNSigAllNodes" SG_ 1308 FwdFusTrkA12MsgIndex 1;
BA_ "SignalType" SG_ 1308 FwdFusTrkA12LongPos "SNM";
BA_ "SignalLongName" SG_ 1308 FwdFusTrkA12LongPos "Forward Fusion Track A12 Longitudinal Position";
BA_ "VNSigAllNodes" SG_ 1308 FwdFusTrkA12LongPos 1;
BA_ "SignalType" SG_ 1308 FwdFusTrkA12RelLongVel "SNM";
BA_ "SignalLongName" SG_ 1308 FwdFusTrkA12RelLongVel "Forward Fusion Track A12 Relative Longitudinal Velocity";
BA_ "VNSigAllNodes" SG_ 1308 FwdFusTrkA12RelLongVel 1;
BA_ "SignalType" SG_ 1308 FwdFusTrkA12Confidence "ENM";
BA_ "SignalLongName" SG_ 1308 FwdFusTrkA12Confidence "Forward Fusion Track A12 Confidence";
BA_ "VNSigAllNodes" SG_ 1308 FwdFusTrkA12Confidence 1;
BA_ "SignalType" SG_ 1308 FwdFusTrkA12LatPos "SNM";
BA_ "SignalLongName" SG_ 1308 FwdFusTrkA12LatPos "Forward Fusion Track A12 Lateral Position";
BA_ "VNSigAllNodes" SG_ 1308 FwdFusTrkA12LatPos 1;
BA_ "SignalType" SG_ 1308 FwdFusTrkA12RelLatVel "SNM";
BA_ "SignalLongName" SG_ 1308 FwdFusTrkA12RelLatVel "Forward Fusion Track A12 Relative Lateral Velocity";
BA_ "VNSigAllNodes" SG_ 1308 FwdFusTrkA12RelLatVel 1;
BA_ "SignalType" SG_ 1308 FwdFusTrkA12MeasStatus "ENM";
BA_ "SignalLongName" SG_ 1308 FwdFusTrkA12MeasStatus "Forward Fusion Track A12 Measurement Status";
BA_ "VNSigAllNodes" SG_ 1308 FwdFusTrkA12MeasStatus 1;
BA_ "SignalType" SG_ 1308 FwdFusTrkA12ObjType "ENM";
BA_ "SignalLongName" SG_ 1308 FwdFusTrkA12ObjType "Forward Fusion Track A12 Object Type";
BA_ "VNSigAllNodes" SG_ 1308 FwdFusTrkA12ObjType 1;
BA_ "SignalType" SG_ 1307 FwdFusTrkA11ObjectID "UNM";
BA_ "SignalLongName" SG_ 1307 FwdFusTrkA11ObjectID "Forward Fusion Track A11 Object ID";
BA_ "VNSigAllNodes" SG_ 1307 FwdFusTrkA11ObjectID 1;
BA_ "SignalType" SG_ 1307 FwdFusTrkA11MsgIndex "UNM";
BA_ "SignalLongName" SG_ 1307 FwdFusTrkA11MsgIndex "Forward Fusion Track A11 Message Index";
BA_ "VNSigAllNodes" SG_ 1307 FwdFusTrkA11MsgIndex 1;
BA_ "SignalType" SG_ 1307 FwdFusTrkA11LongPos "SNM";
BA_ "SignalLongName" SG_ 1307 FwdFusTrkA11LongPos "Forward Fusion Track A11 Longitudinal Position";
BA_ "VNSigAllNodes" SG_ 1307 FwdFusTrkA11LongPos 1;
BA_ "SignalType" SG_ 1307 FwdFusTrkA11RelLongVel "SNM";
BA_ "SignalLongName" SG_ 1307 FwdFusTrkA11RelLongVel "Forward Fusion Track A11 Relative Longitudinal Velocity";
BA_ "VNSigAllNodes" SG_ 1307 FwdFusTrkA11RelLongVel 1;
BA_ "SignalType" SG_ 1307 FwdFusTrkA11Confidence "ENM";
BA_ "SignalLongName" SG_ 1307 FwdFusTrkA11Confidence "Forward Fusion Track A11 Confidence";
BA_ "VNSigAllNodes" SG_ 1307 FwdFusTrkA11Confidence 1;
BA_ "SignalType" SG_ 1307 FwdFusTrkA11LatPos "SNM";
BA_ "SignalLongName" SG_ 1307 FwdFusTrkA11LatPos "Forward Fusion Track A11 Lateral Position";
BA_ "VNSigAllNodes" SG_ 1307 FwdFusTrkA11LatPos 1;
BA_ "SignalType" SG_ 1307 FwdFusTrkA11RelLatVel "SNM";
BA_ "SignalLongName" SG_ 1307 FwdFusTrkA11RelLatVel "Forward Fusion Track A11 Relative Lateral Velocity";
BA_ "VNSigAllNodes" SG_ 1307 FwdFusTrkA11RelLatVel 1;
BA_ "SignalType" SG_ 1307 FwdFusTrkA11MeasStatus "ENM";
BA_ "SignalLongName" SG_ 1307 FwdFusTrkA11MeasStatus "Forward Fusion Track A11 Measurement Status";
BA_ "VNSigAllNodes" SG_ 1307 FwdFusTrkA11MeasStatus 1;
BA_ "SignalType" SG_ 1307 FwdFusTrkA11ObjType "ENM";
BA_ "SignalLongName" SG_ 1307 FwdFusTrkA11ObjType "Forward Fusion Track A11 Object Type";
BA_ "VNSigAllNodes" SG_ 1307 FwdFusTrkA11ObjType 1;
BA_ "SignalType" SG_ 1307 FwdFusTrkA11RollingCnt "UNM";
BA_ "SignalLongName" SG_ 1307 FwdFusTrkA11RollingCnt "Forward Fusion Track A11 Rolling Count";
BA_ "VNSigAllNodes" SG_ 1307 FwdFusTrkA11RollingCnt 1;
BA_ "SignalType" SG_ 1306 FwdFusTrkA10RollingCnt "UNM";
BA_ "SignalLongName" SG_ 1306 FwdFusTrkA10RollingCnt "Forward Fusion Track A10 Rolling Count";
BA_ "VNSigAllNodes" SG_ 1306 FwdFusTrkA10RollingCnt 1;
BA_ "SignalType" SG_ 1306 FwdFusTrkA10ObjectID "UNM";
BA_ "SignalLongName" SG_ 1306 FwdFusTrkA10ObjectID "Forward Fusion Track A10 Object ID";
BA_ "VNSigAllNodes" SG_ 1306 FwdFusTrkA10ObjectID 1;
BA_ "SignalType" SG_ 1306 FwdFusTrkA10MsgIndex "UNM";
BA_ "SignalLongName" SG_ 1306 FwdFusTrkA10MsgIndex "Forward Fusion Track A10 Message Index";
BA_ "VNSigAllNodes" SG_ 1306 FwdFusTrkA10MsgIndex 1;
BA_ "SignalType" SG_ 1306 FwdFusTrkA10LongPos "SNM";
BA_ "SignalLongName" SG_ 1306 FwdFusTrkA10LongPos "Forward Fusion Track A10 Longitudinal Position";
BA_ "VNSigAllNodes" SG_ 1306 FwdFusTrkA10LongPos 1;
BA_ "SignalType" SG_ 1306 FwdFusTrkA10RelLongVel "SNM";
BA_ "SignalLongName" SG_ 1306 FwdFusTrkA10RelLongVel "Forward Fusion Track A10 Relative Longitudinal Velocity";
BA_ "VNSigAllNodes" SG_ 1306 FwdFusTrkA10RelLongVel 1;
BA_ "SignalType" SG_ 1306 FwdFusTrkA10Confidence "ENM";
BA_ "SignalLongName" SG_ 1306 FwdFusTrkA10Confidence "Forward Fusion Track A10 Confidence";
BA_ "VNSigAllNodes" SG_ 1306 FwdFusTrkA10Confidence 1;
BA_ "SignalType" SG_ 1306 FwdFusTrkA10LatPos "SNM";
BA_ "SignalLongName" SG_ 1306 FwdFusTrkA10LatPos "Forward Fusion Track A10 Lateral Position";
BA_ "VNSigAllNodes" SG_ 1306 FwdFusTrkA10LatPos 1;
BA_ "SignalType" SG_ 1306 FwdFusTrkA10RelLatVel "SNM";
BA_ "SignalLongName" SG_ 1306 FwdFusTrkA10RelLatVel "Forward Fusion Track A10 Relative Lateral Velocity";
BA_ "VNSigAllNodes" SG_ 1306 FwdFusTrkA10RelLatVel 1;
BA_ "SignalType" SG_ 1306 FwdFusTrkA10MeasStatus "ENM";
BA_ "SignalLongName" SG_ 1306 FwdFusTrkA10MeasStatus "Forward Fusion Track A10 Measurement Status";
BA_ "VNSigAllNodes" SG_ 1306 FwdFusTrkA10MeasStatus 1;
BA_ "SignalType" SG_ 1306 FwdFusTrkA10ObjType "ENM";
BA_ "SignalLongName" SG_ 1306 FwdFusTrkA10ObjType "Forward Fusion Track A10 Object Type";
BA_ "VNSigAllNodes" SG_ 1306 FwdFusTrkA10ObjType 1;
BA_ "SignalType" SG_ 1297 FwdFusTrkA1RollingCnt "UNM";
BA_ "SignalLongName" SG_ 1297 FwdFusTrkA1RollingCnt "Forward Fusion Track A1 Rolling Count";
BA_ "VNSigAllNodes" SG_ 1297 FwdFusTrkA1RollingCnt 1;
BA_ "SignalType" SG_ 1297 FwdFusTrkA1ObjectID "UNM";
BA_ "SignalLongName" SG_ 1297 FwdFusTrkA1ObjectID "Forward Fusion Track A1 Object ID";
BA_ "VNSigAllNodes" SG_ 1297 FwdFusTrkA1ObjectID 1;
BA_ "SignalType" SG_ 1297 FwdFusTrkA1MsgIndex "UNM";
BA_ "SignalLongName" SG_ 1297 FwdFusTrkA1MsgIndex "Forward Fusion Track A1 Message Index";
BA_ "VNSigAllNodes" SG_ 1297 FwdFusTrkA1MsgIndex 1;
BA_ "SignalType" SG_ 1297 FwdFusTrkA1LongPos "SNM";
BA_ "SignalLongName" SG_ 1297 FwdFusTrkA1LongPos "Forward Fusion Track A1 Longitudinal Position";
BA_ "VNSigAllNodes" SG_ 1297 FwdFusTrkA1LongPos 1;
BA_ "SignalType" SG_ 1297 FwdFusTrkA1RelLongVel "SNM";
BA_ "SignalLongName" SG_ 1297 FwdFusTrkA1RelLongVel "Forward Fusion Track A1 Relative Longitudinal Velocity";
BA_ "VNSigAllNodes" SG_ 1297 FwdFusTrkA1RelLongVel 1;
BA_ "SignalType" SG_ 1297 FwdFusTrkA1Confidence "ENM";
BA_ "SignalLongName" SG_ 1297 FwdFusTrkA1Confidence "Forward Fusion Track A1 Confidence";
BA_ "VNSigAllNodes" SG_ 1297 FwdFusTrkA1Confidence 1;
BA_ "SignalType" SG_ 1297 FwdFusTrkA1LatPos "SNM";
BA_ "SignalLongName" SG_ 1297 FwdFusTrkA1LatPos "Forward Fusion Track A1 Lateral Position";
BA_ "VNSigAllNodes" SG_ 1297 FwdFusTrkA1LatPos 1;
BA_ "SignalType" SG_ 1297 FwdFusTrkA1RelLatVel "SNM";
BA_ "SignalLongName" SG_ 1297 FwdFusTrkA1RelLatVel "Forward Fusion Track A1 Relative Lateral Velocity";
BA_ "VNSigAllNodes" SG_ 1297 FwdFusTrkA1RelLatVel 1;
BA_ "SignalType" SG_ 1297 FwdFusTrkA1MeasStatus "ENM";
BA_ "SignalLongName" SG_ 1297 FwdFusTrkA1MeasStatus "Forward Fusion Track A1 Measurement Status";
BA_ "VNSigAllNodes" SG_ 1297 FwdFusTrkA1MeasStatus 1;
BA_ "SignalType" SG_ 1297 FwdFusTrkA1ObjType "ENM";
BA_ "SignalLongName" SG_ 1297 FwdFusTrkA1ObjType "Forward Fusion Track A1 Object Type";
BA_ "VNSigAllNodes" SG_ 1297 FwdFusTrkA1ObjType 1;
BA_ "SignalType" SG_ 1296 F_FusHeadRollingCount "UNM";
BA_ "SignalLongName" SG_ 1296 F_FusHeadRollingCount "Forward Fusion Header Rolling Count";
BA_ "VNSigAllNodes" SG_ 1296 F_FusHeadRollingCount 1;
BA_ "SignalType" SG_ 1296 F_FusHeadFuncState "ENM";
BA_ "SignalLongName" SG_ 1296 F_FusHeadFuncState "Forward Fusion Header Functional State";
BA_ "VNSigAllNodes" SG_ 1296 F_FusHeadFuncState 1;
BA_ "SignalType" SG_ 1296 F_FusHedNmValTargts "UNM";
BA_ "SignalLongName" SG_ 1296 F_FusHedNmValTargts "Forward Fusion Header Number of Valid Targets";
BA_ "VNSigAllNodes" SG_ 1296 F_FusHedNmValTargts 1;
BA_ "SignalType" SG_ 1296 F_FusHead_LrrOK "ENM";
BA_ "SignalLongName" SG_ 1296 F_FusHead_LrrOK "Forward Fusion Header Lrr Sensor OK";
BA_ "VNSigAllNodes" SG_ 1296 F_FusHead_LrrOK 1;
BA_ "SignalType" SG_ 1296 F_FusHead_LFSRROK "ENM";
BA_ "SignalLongName" SG_ 1296 F_FusHead_LFSRROK "Forward Fusion Header LFSRR Sensor OK";
BA_ "VNSigAllNodes" SG_ 1296 F_FusHead_LFSRROK 1;
BA_ "SignalType" SG_ 1296 F_FusHead_VIsOK "ENM";
BA_ "SignalLongName" SG_ 1296 F_FusHead_VIsOK "Forward Fusion Header Vision sensor OK";
BA_ "VNSigAllNodes" SG_ 1296 F_FusHead_VIsOK 1;
BA_ "SignalType" SG_ 1296 F_FusHead_MapDataOK "ENM";
BA_ "SignalLongName" SG_ 1296 F_FusHead_MapDataOK "Forward Fusion Header Map Data OK";
BA_ "VNSigAllNodes" SG_ 1296 F_FusHead_MapDataOK 1;
BA_ "SignalType" SG_ 1296 F_FusHeadTimStmpV "ENM";
BA_ "SignalLongName" SG_ 1296 F_FusHeadTimStmpV "Forward Fusion Header Time Stamp Validity";
BA_ "VNSigAllNodes" SG_ 1296 F_FusHeadTimStmpV 1;
BA_ "SignalType" SG_ 1296 F_FusHeadTimStmp "UNM";
BA_ "SignalLongName" SG_ 1296 F_FusHeadTimStmp "Forward Fusion Header Data Time Stamp";
BA_ "VNSigAllNodes" SG_ 1296 F_FusHeadTimStmp 1;
BA_ "SignalType" SG_ 1296 F_FusHead_LCSRROK "ENM";
BA_ "SignalLongName" SG_ 1296 F_FusHead_LCSRROK "Forward Fusion Header LCSRR Sensor OK";
BA_ "VNSigAllNodes" SG_ 1296 F_FusHead_LCSRROK 1;
BA_ "SignalType" SG_ 1296 F_FusHead_RCSRROK "ENM";
BA_ "SignalLongName" SG_ 1296 F_FusHead_RCSRROK "Forward Fusion Header RC SRR OK";
BA_ "VNSigAllNodes" SG_ 1296 F_FusHead_RCSRROK 1;
BA_ "SignalType" SG_ 1296 F_FusHead_RFSRROK "ENM";
BA_ "SignalLongName" SG_ 1296 F_FusHead_RFSRROK "Forward Fusion Header RF SRR OK";
BA_ "VNSigAllNodes" SG_ 1296 F_FusHead_RFSRROK 1;
BA_ "SignalType" SG_ 1296 F_FusHed_ObjClstrCurv "SNM";
BA_ "SignalLongName" SG_ 1296 F_FusHed_ObjClstrCurv "Forward Fusion Header Object Cluster Path Curvature";
BA_ "VNSigAllNodes" SG_ 1296 F_FusHed_ObjClstrCurv 1;
BA_ "SignalType" SG_ 1296 F_FusHdObjClstTanHdng "SNM";
BA_ "SignalLongName" SG_ 1296 F_FusHdObjClstTanHdng "Forward Fusion Header Object Cluster tangetn Heading";
BA_ "VNSigAllNodes" SG_ 1296 F_FusHdObjClstTanHdng 1;
BA_ "SignalType" SG_ 1296 RoadTypeInfo "ENM";
BA_ "SignalLongName" SG_ 1296 RoadTypeInfo "Road Type Info";
BA_ "VNSigAllNodes" SG_ 1296 RoadTypeInfo 1;
BA_ "VNSigSLHSSharedDiagnostic" SG_ 257 DgnInf 1;
BA_ "SignalType" SG_ 257 DgnInf "UNM";
BA_ "SignalLongName" SG_ 257 DgnInf "Diagnostic Information";
BA_ "VNSigAllNodes" SG_ 257 DgnInf 1;
BA_ "SignalType" SG_ 1338 FrtRWARateDiagFA "BLN";
BA_ "SignalLongName" SG_ 1338 FrtRWARateDiagFA "Front Road Wheel Angle Rate Fault";
BA_ "VNSigAllNodes" SG_ 1338 FrtRWARateDiagFA 1;
BA_ "SignalType" SG_ 1338 FrtRWABiasDiagFA "BLN";
BA_ "SignalLongName" SG_ 1338 FrtRWABiasDiagFA "Front Road Wheel Angle Bias Fault";
BA_ "VNSigAllNodes" SG_ 1338 FrtRWABiasDiagFA 1;
BA_ "SignalType" SG_ 1338 HWAFrtVal "BLN";
BA_ "SignalLongName" SG_ 1338 HWAFrtVal "Front Road Wheel Angle Value Valid";
BA_ "VNSigAllNodes" SG_ 1338 HWAFrtVal 1;
BA_ "SignalType" SG_ 1338 HWADotValFrt "BLN";
BA_ "SignalLongName" SG_ 1338 HWADotValFrt "Front Road Wheel Angle Rate Valid";
BA_ "VNSigAllNodes" SG_ 1338 HWADotValFrt 1;
BA_ "SignalType" SG_ 1338 S2VehAxRangeFA "BLN";
BA_ "SignalLongName" SG_ 1338 S2VehAxRangeFA "Secondary Longitudinal Acceleration Range Fault";
BA_ "VNSigAllNodes" SG_ 1338 S2VehAxRangeFA 1;
BA_ "SignalType" SG_ 1338 S2VehAxRateFA "BLN";
BA_ "SignalLongName" SG_ 1338 S2VehAxRateFA "Secondary Longitudinal Acceleration Range Fault";
BA_ "VNSigAllNodes" SG_ 1338 S2VehAxRateFA 1;
BA_ "SignalType" SG_ 1338 S2VehAxBiasFA "BLN";
BA_ "SignalLongName" SG_ 1338 S2VehAxBiasFA "Secondary Longitudinal Acceleration Bias Fault";
BA_ "VNSigAllNodes" SG_ 1338 S2VehAxBiasFA 1;
BA_ "SignalType" SG_ 1338 VehAxCompFA "BLN";
BA_ "SignalLongName" SG_ 1338 VehAxCompFA "Longitudinal Acceleration Comaprison Fault";
BA_ "VNSigAllNodes" SG_ 1338 VehAxCompFA 1;
BA_ "SignalType" SG_ 1338 S1VehAxVal "BLN";
BA_ "SignalLongName" SG_ 1338 S1VehAxVal "Primary Longitudinal Acceleration Sensor Valid";
BA_ "VNSigAllNodes" SG_ 1338 S1VehAxVal 1;
BA_ "SignalType" SG_ 1338 S2VehAxVal "BLN";
BA_ "SignalLongName" SG_ 1338 S2VehAxVal "Secondary Longitudinal Acceleration Sensor Valid";
BA_ "VNSigAllNodes" SG_ 1338 S2VehAxVal 1;
BA_ "SignalType" SG_ 1338 FrtRWACorrFA "BLN";
BA_ "SignalLongName" SG_ 1338 FrtRWACorrFA "Front Road Wheel Angle Correlation Fault";
BA_ "VNSigAllNodes" SG_ 1338 FrtRWACorrFA 1;
BA_ "SignalType" SG_ 1338 FrtRWARangeDiagFA "BLN";
BA_ "SignalLongName" SG_ 1338 FrtRWARangeDiagFA "Front Road Wheel Angle Range Fault";
BA_ "VNSigAllNodes" SG_ 1338 FrtRWARangeDiagFA 1;
BA_ "SignalType" SG_ 1338 S2VehAyBiasFA "BLN";
BA_ "SignalLongName" SG_ 1338 S2VehAyBiasFA "Secondary Lateral Acceleration Bias Fault";
BA_ "VNSigAllNodes" SG_ 1338 S2VehAyBiasFA 1;
BA_ "SignalType" SG_ 1338 VehAyCompFA "BLN";
BA_ "SignalLongName" SG_ 1338 VehAyCompFA "Lateral Acceleration Comaprison Fault";
BA_ "VNSigAllNodes" SG_ 1338 VehAyCompFA 1;
BA_ "SignalType" SG_ 1338 S1VehAyVal "BLN";
BA_ "SignalLongName" SG_ 1338 S1VehAyVal "Primary Lateral Acceleration Sensor Valid";
BA_ "VNSigAllNodes" SG_ 1338 S1VehAyVal 1;
BA_ "SignalType" SG_ 1338 S2VehAyVal "BLN";
BA_ "SignalLongName" SG_ 1338 S2VehAyVal "Secondary Lateral Acceleration Sensor Valid";
BA_ "VNSigAllNodes" SG_ 1338 S2VehAyVal 1;
BA_ "SignalType" SG_ 1338 VehAxCorrFA "BLN";
BA_ "SignalLongName" SG_ 1338 VehAxCorrFA "Vehicle Longitudinal Acceleration Correlation Fault";
BA_ "VNSigAllNodes" SG_ 1338 VehAxCorrFA 1;
BA_ "SignalType" SG_ 1338 S1VehAxRangeFA "BLN";
BA_ "SignalLongName" SG_ 1338 S1VehAxRangeFA "Primary Longitudinal Acceleration Range Fault";
BA_ "VNSigAllNodes" SG_ 1338 S1VehAxRangeFA 1;
BA_ "SignalType" SG_ 1338 S1VehAxRateFA "BLN";
BA_ "SignalLongName" SG_ 1338 S1VehAxRateFA "Primary Longitudinal Acceleration Rate Fault";
BA_ "VNSigAllNodes" SG_ 1338 S1VehAxRateFA 1;
BA_ "SignalType" SG_ 1338 S1VehAxBiasFA "BLN";
BA_ "SignalLongName" SG_ 1338 S1VehAxBiasFA "Primary Longitudinal Acceleration Bias Fault";
BA_ "VNSigAllNodes" SG_ 1338 S1VehAxBiasFA 1;
BA_ "SignalType" SG_ 1338 S1VehWzVal "BLN";
BA_ "SignalLongName" SG_ 1338 S1VehWzVal "Primary Yaw Rate Sensor Valid";
BA_ "VNSigAllNodes" SG_ 1338 S1VehWzVal 1;
BA_ "SignalType" SG_ 1338 S2VehWzVal "BLN";
BA_ "SignalLongName" SG_ 1338 S2VehWzVal "Secondary Yaw Rate Sensor Valid";
BA_ "VNSigAllNodes" SG_ 1338 S2VehWzVal 1;
BA_ "SignalType" SG_ 1338 VehAyCorrDiagFA "BLN";
BA_ "SignalLongName" SG_ 1338 VehAyCorrDiagFA "Vehicle Lateral Acceleration Correlation Fault";
BA_ "VNSigAllNodes" SG_ 1338 VehAyCorrDiagFA 1;
BA_ "SignalType" SG_ 1338 S1VehAyRangeFA "BLN";
BA_ "SignalLongName" SG_ 1338 S1VehAyRangeFA "Primary Lateral Acceleration Range Fault";
BA_ "VNSigAllNodes" SG_ 1338 S1VehAyRangeFA 1;
BA_ "SignalType" SG_ 1338 S1VehAyRateFA "BLN";
BA_ "SignalLongName" SG_ 1338 S1VehAyRateFA "Primary Lateral Acceleration Rate Fault";
BA_ "VNSigAllNodes" SG_ 1338 S1VehAyRateFA 1;
BA_ "SignalType" SG_ 1338 S1VehAyBiasFA "BLN";
BA_ "SignalLongName" SG_ 1338 S1VehAyBiasFA "Primary Lateral Acceleration Bias Fault";
BA_ "VNSigAllNodes" SG_ 1338 S1VehAyBiasFA 1;
BA_ "SignalType" SG_ 1338 S2VehAyRangeFA "BLN";
BA_ "SignalLongName" SG_ 1338 S2VehAyRangeFA "Secondary Lateral Acceleration Range Fault";
BA_ "VNSigAllNodes" SG_ 1338 S2VehAyRangeFA 1;
BA_ "SignalType" SG_ 1338 S2VehAyRateFA "BLN";
BA_ "SignalLongName" SG_ 1338 S2VehAyRateFA "Secondary Lateral Acceleration Rate Fault";
BA_ "VNSigAllNodes" SG_ 1338 S2VehAyRateFA 1;
BA_ "SignalType" SG_ 1338 VehWzCorrDiagFA "BLN";
BA_ "SignalLongName" SG_ 1338 VehWzCorrDiagFA "Vehicle Yaw Rate Correlation Fault";
BA_ "VNSigAllNodes" SG_ 1338 VehWzCorrDiagFA 1;
BA_ "SignalType" SG_ 1338 S1VehWzRangeFA "BLN";
BA_ "SignalLongName" SG_ 1338 S1VehWzRangeFA "Primary Yaw Rate Sensor Range Fault";
BA_ "VNSigAllNodes" SG_ 1338 S1VehWzRangeFA 1;
BA_ "SignalType" SG_ 1338 S1VehWzRateFA "BLN";
BA_ "SignalLongName" SG_ 1338 S1VehWzRateFA "Primary Yaw Rate Sensor Rate Fault";
BA_ "VNSigAllNodes" SG_ 1338 S1VehWzRateFA 1;
BA_ "SignalType" SG_ 1338 S1VehWzBiasFA "BLN";
BA_ "SignalLongName" SG_ 1338 S1VehWzBiasFA "Primary Yaw Rate Sensor Bias Fault";
BA_ "VNSigAllNodes" SG_ 1338 S1VehWzBiasFA 1;
BA_ "SignalType" SG_ 1338 S2VehWzRangeFA "BLN";
BA_ "SignalLongName" SG_ 1338 S2VehWzRangeFA "Secondary Yaw Rate Sensor Range Fault";
BA_ "VNSigAllNodes" SG_ 1338 S2VehWzRangeFA 1;
BA_ "SignalType" SG_ 1338 S2VehWzRateFA "BLN";
BA_ "SignalLongName" SG_ 1338 S2VehWzRateFA "Secondary Yaw Rate Sensor Rate Fault";
BA_ "VNSigAllNodes" SG_ 1338 S2VehWzRateFA 1;
BA_ "SignalType" SG_ 1338 S2VehWzBiasFA "BLN";
BA_ "SignalLongName" SG_ 1338 S2VehWzBiasFA "Secondary Yaw Rate Sensor Bias Fault";
BA_ "VNSigAllNodes" SG_ 1338 S2VehWzBiasFA 1;
BA_ "SignalType" SG_ 1338 VehWzCompFA "BLN";
BA_ "SignalLongName" SG_ 1338 VehWzCompFA "Yaw Rate Sensor Compare Fault";
BA_ "VNSigAllNodes" SG_ 1338 VehWzCompFA 1;
BA_ "SignalType" SG_ 1338 WhlVxLFCorrDiagFA "BLN";
BA_ "SignalLongName" SG_ 1338 WhlVxLFCorrDiagFA "Wheel Speed Correlation Fault Left Front";
BA_ "VNSigAllNodes" SG_ 1338 WhlVxLFCorrDiagFA 1;
BA_ "SignalType" SG_ 1338 WhlVxRFCorrDiagFA "BLN";
BA_ "SignalLongName" SG_ 1338 WhlVxRFCorrDiagFA "Wheel Speed Correlation Fault Right Front";
BA_ "VNSigAllNodes" SG_ 1338 WhlVxRFCorrDiagFA 1;
BA_ "SignalType" SG_ 1338 WhlVxLRCorrDiagFA "BLN";
BA_ "SignalLongName" SG_ 1338 WhlVxLRCorrDiagFA "Wheel Speed Correlation Fault Left Rear";
BA_ "VNSigAllNodes" SG_ 1338 WhlVxLRCorrDiagFA 1;
BA_ "SignalType" SG_ 1338 WhlVxRRCorrDiagFA "BLN";
BA_ "SignalLongName" SG_ 1338 WhlVxRRCorrDiagFA "Wheel Speed Correlation Fault Right Rear";
BA_ "VNSigAllNodes" SG_ 1338 WhlVxRRCorrDiagFA 1;
BA_ "SignalType" SG_ 1338 WhlLFVal "BLN";
BA_ "SignalLongName" SG_ 1338 WhlLFVal "Wheel Speed Validity Left Front";
BA_ "VNSigAllNodes" SG_ 1338 WhlLFVal 1;
BA_ "SignalType" SG_ 1338 WhlRFVal "BLN";
BA_ "SignalLongName" SG_ 1338 WhlRFVal "Wheel Speed Validity Right Front";
BA_ "VNSigAllNodes" SG_ 1338 WhlRFVal 1;
BA_ "SignalType" SG_ 1338 WhlLRVal "BLN";
BA_ "SignalLongName" SG_ 1338 WhlLRVal "Wheel Speed Validity Left Rear";
BA_ "VNSigAllNodes" SG_ 1338 WhlLRVal 1;
BA_ "SignalType" SG_ 1338 WhlRRVal "BLN";
BA_ "SignalLongName" SG_ 1338 WhlRRVal "Wheel Speed Validity Right Rear";
BA_ "VNSigAllNodes" SG_ 1338 WhlRRVal 1;
BA_ "SignalType" SG_ 1328 AlrtWrnIndReqFP "BLN";
BA_ "SignalLongName" SG_ 1328 AlrtWrnIndReqFP "Alert Warning Indicator Request Fault Pending";
BA_ "VNSigAllNodes" SG_ 1328 AlrtWrnIndReqFP 1;
BA_ "SignalType" SG_ 1328 AlrtWrnIndReqFA "BLN";
BA_ "SignalLongName" SG_ 1328 AlrtWrnIndReqFA "Alert Warning Indicator Request Fault Active";
BA_ "VNSigAllNodes" SG_ 1328 AlrtWrnIndReqFA 1;
BA_ "SignalType" SG_ 1328 ILRSRRSnsr_FP "BLN";
BA_ "SignalLongName" SG_ 1328 ILRSRRSnsr_FP "Inner Left Rear SRR Sensor Fault Pending";
BA_ "VNSigAllNodes" SG_ 1328 ILRSRRSnsr_FP 1;
BA_ "SignalType" SG_ 1328 ILRSRRSnsr_FA "BLN";
BA_ "SignalLongName" SG_ 1328 ILRSRRSnsr_FA "Inner Left Rear SRR Sensor Fault Active";
BA_ "VNSigAllNodes" SG_ 1328 ILRSRRSnsr_FA 1;
BA_ "SignalType" SG_ 1328 ILRSRRFrehns_FA "BLN";
BA_ "SignalLongName" SG_ 1328 ILRSRRFrehns_FA "Inner Left Rear SRR Freshness Fault Active";
BA_ "VNSigAllNodes" SG_ 1328 ILRSRRFrehns_FA 1;
BA_ "SignalType" SG_ 1328 VehPathEstCrvCSFP "BLN";
BA_ "SignalLongName" SG_ 1328 VehPathEstCrvCSFP "Vehicle Path Estimated Curvature Compare Signal Fault Active";
BA_ "VNSigAllNodes" SG_ 1328 VehPathEstCrvCSFP 1;
BA_ "SignalType" SG_ 1328 VehPathEstCrvCSFA "BLN";
BA_ "SignalLongName" SG_ 1328 VehPathEstCrvCSFA "Vehicle Path Estimated Curvature Compare Signal Fault Active";
BA_ "VNSigAllNodes" SG_ 1328 VehPathEstCrvCSFA 1;
BA_ "SignalType" SG_ 1328 VehPathWzEstCSFP "BLN";
BA_ "SignalLongName" SG_ 1328 VehPathWzEstCSFP "Vehicle Path Yaw Rate Estimated Compare Signal Fault Pending";
BA_ "VNSigAllNodes" SG_ 1328 VehPathWzEstCSFP 1;
BA_ "SignalType" SG_ 1328 VehPathWzEstCSFA "BLN";
BA_ "SignalLongName" SG_ 1328 VehPathWzEstCSFA "Vehicle Path Yaw Rate Estimated Compare Signal Fault Active";
BA_ "VNSigAllNodes" SG_ 1328 VehPathWzEstCSFA 1;
BA_ "SignalType" SG_ 1328 VehPathVyEstCSFP "BLN";
BA_ "SignalLongName" SG_ 1328 VehPathVyEstCSFP "Vehicle Path Lateral Velocity Estimated Compare Signal Fault Pending";
BA_ "VNSigAllNodes" SG_ 1328 VehPathVyEstCSFP 1;
BA_ "SignalType" SG_ 1328 VehPathVyEstCSFA "BLN";
BA_ "SignalLongName" SG_ 1328 VehPathVyEstCSFA "Vehicle Path Lateral Velocity Estimated Compare Signal Fault Active";
BA_ "VNSigAllNodes" SG_ 1328 VehPathVyEstCSFA 1;
BA_ "SignalType" SG_ 1328 VehPathVxEstCSFP "BLN";
BA_ "SignalLongName" SG_ 1328 VehPathVxEstCSFP "Vehicle Path Longitudinal Velocity Estimated Compare Signal Fault Pending";
BA_ "VNSigAllNodes" SG_ 1328 VehPathVxEstCSFP 1;
BA_ "SignalType" SG_ 1328 VehPathVxEstCSFA "BLN";
BA_ "SignalLongName" SG_ 1328 VehPathVxEstCSFA "Vehicle Path Longitudinal Velocity Estimated Compare Signal Fault Active";
BA_ "VNSigAllNodes" SG_ 1328 VehPathVxEstCSFA 1;
BA_ "SignalType" SG_ 1328 TCPHiThrtTTCCSFP "BLN";
BA_ "SignalLongName" SG_ 1328 TCPHiThrtTTCCSFP "TCP Hi Threat Time to Collision Compare Signal Fault Pending";
BA_ "VNSigAllNodes" SG_ 1328 TCPHiThrtTTCCSFP 1;
BA_ "SignalType" SG_ 1328 TCPHiThrtTTCCSFA "BLN";
BA_ "SignalLongName" SG_ 1328 TCPHiThrtTTCCSFA "TCP Hi Threat Time to Collision Compare Signal Fault Active";
BA_ "VNSigAllNodes" SG_ 1328 TCPHiThrtTTCCSFA 1;
BA_ "SignalType" SG_ 1328 TCPHiThrtLyCSFP "BLN";
BA_ "SignalLongName" SG_ 1328 TCPHiThrtLyCSFP "TCP Hi Threat Lateral Position Compare Signal Fault Pending";
BA_ "VNSigAllNodes" SG_ 1328 TCPHiThrtLyCSFP 1;
BA_ "SignalType" SG_ 1328 TCPHiThrtLyCSFA "BLN";
BA_ "SignalLongName" SG_ 1328 TCPHiThrtLyCSFA "TCP Hi Threat Lateral Position Compare Signal Fault Active";
BA_ "VNSigAllNodes" SG_ 1328 TCPHiThrtLyCSFA 1;
BA_ "SignalType" SG_ 1328 TCPHiThLxVxAxCSFP "BLN";
BA_ "SignalLongName" SG_ 1328 TCPHiThLxVxAxCSFP "TCP Hi Threat Lateral Position Velocity and Acceleration Compare Signal Fault Pending";
BA_ "VNSigAllNodes" SG_ 1328 TCPHiThLxVxAxCSFP 1;
BA_ "SignalType" SG_ 1328 TCPHiThLxVxAxCSFA "BLN";
BA_ "SignalLongName" SG_ 1328 TCPHiThLxVxAxCSFA "TCP Hi Threat Lateral Position Velocity and Acceleration Compare Signal Fault Active";
BA_ "VNSigAllNodes" SG_ 1328 TCPHiThLxVxAxCSFA 1;
BA_ "SignalType" SG_ 1328 CurSetValDiagFP "BLN";
BA_ "SignalLongName" SG_ 1328 CurSetValDiagFP "Current Setting Vaule Fault Pending";
BA_ "VNSigAllNodes" SG_ 1328 CurSetValDiagFP 1;
BA_ "SignalType" SG_ 1328 CurSetValDiagFA "BLN";
BA_ "SignalLongName" SG_ 1328 CurSetValDiagFA "Current Setting Vaule Fault Active";
BA_ "VNSigAllNodes" SG_ 1328 CurSetValDiagFA 1;
BA_ "SignalType" SG_ 1328 CrsAltDvrSlTpDiagFP "BLN";
BA_ "SignalLongName" SG_ 1328 CrsAltDvrSlTpDiagFP "Crash Alert Driver Selected Type Fault Pending";
BA_ "VNSigAllNodes" SG_ 1328 CrsAltDvrSlTpDiagFP 1;
BA_ "SignalType" SG_ 1328 CrsAltDvrSlTpDiagFA "BLN";
BA_ "SignalLongName" SG_ 1328 CrsAltDvrSlTpDiagFA "Crash Alert Driver Selected Type Fault Active";
BA_ "VNSigAllNodes" SG_ 1328 CrsAltDvrSlTpDiagFA 1;
BA_ "SignalType" SG_ 1328 FCAStatDiagFP "BLN";
BA_ "SignalLongName" SG_ 1328 FCAStatDiagFP "FCA Status Fault Pending";
BA_ "VNSigAllNodes" SG_ 1328 FCAStatDiagFP 1;
BA_ "SignalType" SG_ 1328 FCAStatDiagFA "BLN";
BA_ "SignalLongName" SG_ 1328 FCAStatDiagFA "FCA Status Fault Active";
BA_ "VNSigAllNodes" SG_ 1328 FCAStatDiagFA 1;
BA_ "SignalType" SG_ 1328 RVBBrkCtrlStFP "BLN";
BA_ "SignalLongName" SG_ 1328 RVBBrkCtrlStFP "Rear Virtual Bumper Brake Control Status Fault Pending";
BA_ "VNSigAllNodes" SG_ 1328 RVBBrkCtrlStFP 1;
BA_ "SignalType" SG_ 1328 RVBBrkCtrlStFA "BLN";
BA_ "SignalLongName" SG_ 1328 RVBBrkCtrlStFA "Rear Virtual Bumper Brake Control Status Fault Active";
BA_ "VNSigAllNodes" SG_ 1328 RVBBrkCtrlStFA 1;
BA_ "SignalType" SG_ 1328 RVBOpStFP "BLN";
BA_ "SignalLongName" SG_ 1328 RVBOpStFP "Rear Virtual Bumper Operating State Fault Pending";
BA_ "VNSigAllNodes" SG_ 1328 RVBOpStFP 1;
BA_ "SignalType" SG_ 1328 RVBOpStFA "BLN";
BA_ "SignalLongName" SG_ 1328 RVBOpStFA "Rear Virtual Bumper Operating State Fault Active";
BA_ "VNSigAllNodes" SG_ 1328 RVBOpStFA 1;
BA_ "SignalType" SG_ 1328 RVBBrkCtrlAccFP "BLN";
BA_ "SignalLongName" SG_ 1328 RVBBrkCtrlAccFP "Rear Virtual Bumper Brake Control Acceleration Fault Pending";
BA_ "VNSigAllNodes" SG_ 1328 RVBBrkCtrlAccFP 1;
BA_ "SignalType" SG_ 1328 RVBBrkCtrlAccFA "BLN";
BA_ "SignalLongName" SG_ 1328 RVBBrkCtrlAccFA "Rear Virtual Bumper Brake Control Acceleration Fault Active";
BA_ "VNSigAllNodes" SG_ 1328 RVBBrkCtrlAccFA 1;
BA_ "SignalType" SG_ 1328 RVBAxlTrqRqFP "BLN";
BA_ "SignalLongName" SG_ 1328 RVBAxlTrqRqFP "Rear Virtual Bumper Axle Torque Request Fault Pending";
BA_ "VNSigAllNodes" SG_ 1328 RVBAxlTrqRqFP 1;
BA_ "SignalType" SG_ 1328 RVBAxlTrqRqFA "BLN";
BA_ "SignalLongName" SG_ 1328 RVBAxlTrqRqFA "Rear Virtual Bumper Axle Torque Request Fault Active";
BA_ "VNSigAllNodes" SG_ 1328 RVBAxlTrqRqFA 1;
BA_ "SignalType" SG_ 1328 TVRUPATTCFP "BLN";
BA_ "SignalLongName" SG_ 1328 TVRUPATTCFP "TVR Ultrasonic Park Assist Time to Collision Fault Pending";
BA_ "VNSigAllNodes" SG_ 1328 TVRUPATTCFP 1;
BA_ "SignalType" SG_ 1328 TVRUPATTCFA "BLN";
BA_ "SignalLongName" SG_ 1328 TVRUPATTCFA "TVR Ultrasonic Park Assist Time to Collision Fault Active";
BA_ "VNSigAllNodes" SG_ 1328 TVRUPATTCFA 1;
BA_ "SignalType" SG_ 1328 TVRHiThrtObjIDFP "BLN";
BA_ "SignalLongName" SG_ 1328 TVRHiThrtObjIDFP "TVR Hi Threat Object ID Fault Pending";
BA_ "VNSigAllNodes" SG_ 1328 TVRHiThrtObjIDFP 1;
BA_ "SignalType" SG_ 1328 TVRHiThrtObjIDFA "BLN";
BA_ "SignalLongName" SG_ 1328 TVRHiThrtObjIDFA "TVR Hi Threat Object ID Fault Active";
BA_ "VNSigAllNodes" SG_ 1328 TVRHiThrtObjIDFA 1;
BA_ "SignalType" SG_ 1328 TVRHiThrtTTCFP "BLN";
BA_ "SignalLongName" SG_ 1328 TVRHiThrtTTCFP "TVR Hi Threat Time to Collision Fault Pending";
BA_ "VNSigAllNodes" SG_ 1328 TVRHiThrtTTCFP 1;
BA_ "SignalType" SG_ 1328 TVRHiThrtTTCFA "BLN";
BA_ "SignalLongName" SG_ 1328 TVRHiThrtTTCFA "TVR Hi Threat Time to Collision Fault Active";
BA_ "VNSigAllNodes" SG_ 1328 TVRHiThrtTTCFA 1;
BA_ "SignalType" SG_ 1328 TVRHiThrtLxFP "BLN";
BA_ "SignalLongName" SG_ 1328 TVRHiThrtLxFP "TVR Hi Threat Longitudinal Position Fault Pending";
BA_ "VNSigAllNodes" SG_ 1328 TVRHiThrtLxFP 1;
BA_ "SignalType" SG_ 1328 TVRHiThrtLxFA "BLN";
BA_ "SignalLongName" SG_ 1328 TVRHiThrtLxFA "TVR Hi Threat Longitudinal Position Fault Active";
BA_ "VNSigAllNodes" SG_ 1328 TVRHiThrtLxFA 1;
BA_ "SignalType" SG_ 1328 TVRHiThrtLyFP "BLN";
BA_ "SignalLongName" SG_ 1328 TVRHiThrtLyFP "TVR Hi Threat Lateral Position Fault Pending";
BA_ "VNSigAllNodes" SG_ 1328 TVRHiThrtLyFP 1;
BA_ "SignalType" SG_ 1328 TVRHiThrtLyFA "BLN";
BA_ "SignalLongName" SG_ 1328 TVRHiThrtLyFA "TVR Hi Threat Lateral Position Fault Active";
BA_ "VNSigAllNodes" SG_ 1328 TVRHiThrtLyFA 1;
BA_ "SignalType" SG_ 1328 ROFFuncStFP "BLN";
BA_ "SignalLongName" SG_ 1328 ROFFuncStFP "Rearward Fusion Functional State Fault Pending";
BA_ "VNSigAllNodes" SG_ 1328 ROFFuncStFP 1;
BA_ "SignalType" SG_ 1328 ROFFuncStFA "BLN";
BA_ "SignalLongName" SG_ 1328 ROFFuncStFA "Rearward Fusion Functional State Fault Active";
BA_ "VNSigAllNodes" SG_ 1328 ROFFuncStFA 1;
BA_ "SignalType" SG_ 1328 ROFObjIDFP "BLN";
BA_ "SignalLongName" SG_ 1328 ROFObjIDFP "Rearward Fusion Object ID Diagnostic Fault Pending";
BA_ "VNSigAllNodes" SG_ 1328 ROFObjIDFP 1;
BA_ "SignalType" SG_ 1328 ROFObjIDFA "BLN";
BA_ "SignalLongName" SG_ 1328 ROFObjIDFA "Rearward Fusion Object ID Diagnostic Fault Active";
BA_ "VNSigAllNodes" SG_ 1328 ROFObjIDFA 1;
BA_ "SignalType" SG_ 1328 ROFLatPstnVelRatFP "BLN";
BA_ "SignalLongName" SG_ 1328 ROFLatPstnVelRatFP "Rearward Fusion Lateral Position Velocity Fault Pending";
BA_ "VNSigAllNodes" SG_ 1328 ROFLatPstnVelRatFP 1;
BA_ "SignalType" SG_ 1328 ROFLatPstnVelRatFA "BLN";
BA_ "SignalLongName" SG_ 1328 ROFLatPstnVelRatFA "Rearward Fusion Lateral Position Velocity Fault Active";
BA_ "VNSigAllNodes" SG_ 1328 ROFLatPstnVelRatFA 1;
BA_ "SignalType" SG_ 1328 ROFLonPstnVelFP "BLN";
BA_ "SignalLongName" SG_ 1328 ROFLonPstnVelFP "Rearward Fusion Longitudinal Position Velocity Fault Pending";
BA_ "VNSigAllNodes" SG_ 1328 ROFLonPstnVelFP 1;
BA_ "SignalType" SG_ 1328 ROFLonPstnVelFA "BLN";
BA_ "SignalLongName" SG_ 1328 ROFLonPstnVelFA "Rearward Fusion Longitudinal Position Velocity Fault Active";
BA_ "VNSigAllNodes" SG_ 1328 ROFLonPstnVelFA 1;
BA_ "SignalType" SG_ 1328 ROFRltvLatVelDiagFP "BLN";
BA_ "SignalLongName" SG_ 1328 ROFRltvLatVelDiagFP "Rearward Fusion Relative Lateral Velocity Diagnostic Fault Pending";
BA_ "VNSigAllNodes" SG_ 1328 ROFRltvLatVelDiagFP 1;
BA_ "SignalType" SG_ 1328 ROFRltvLatVelDiagFA "BLN";
BA_ "SignalLongName" SG_ 1328 ROFRltvLatVelDiagFA "Rearward Fusion Relative Lateral Velocity Diagnostic Fault Active";
BA_ "VNSigAllNodes" SG_ 1328 ROFRltvLatVelDiagFA 1;
BA_ "SignalType" SG_ 1328 ROFRltvLatPstnDiagFP "BLN";
BA_ "SignalLongName" SG_ 1328 ROFRltvLatPstnDiagFP "Rearward Fusion Relative Lateral Position Diagnostic Fault Pending";
BA_ "VNSigAllNodes" SG_ 1328 ROFRltvLatPstnDiagFP 1;
BA_ "SignalType" SG_ 1328 ROFRltvLatPstnDiagFA "BLN";
BA_ "SignalLongName" SG_ 1328 ROFRltvLatPstnDiagFA "Rearward Fusion Relative Lateral Position Diagnostic Fault Active";
BA_ "VNSigAllNodes" SG_ 1328 ROFRltvLatPstnDiagFA 1;
BA_ "SignalType" SG_ 1328 ROFNrRltvLonPstnFP "BLN";
BA_ "SignalLongName" SG_ 1328 ROFNrRltvLonPstnFP "Rearward Fusion Nearest Relatiive Longitudinal Position Fault Pending";
BA_ "VNSigAllNodes" SG_ 1328 ROFNrRltvLonPstnFP 1;
BA_ "SignalType" SG_ 1328 ROFNrRltvLonPstnFA "BLN";
BA_ "SignalLongName" SG_ 1328 ROFNrRltvLonPstnFA "Rearward Fusion Nearest Relatiive Longitudinal Position Fault Active";
BA_ "VNSigAllNodes" SG_ 1328 ROFNrRltvLonPstnFA 1;
BA_ "SignalType" SG_ 1328 ROFLonPstnVelRatFP "BLN";
BA_ "SignalLongName" SG_ 1328 ROFLonPstnVelRatFP "Rearward Fusion Longitudinal Position Velocity Rationality Fault Pending";
BA_ "VNSigAllNodes" SG_ 1328 ROFLonPstnVelRatFP 1;
BA_ "SignalType" SG_ 1328 ROFLonPstnVelRatFA "BLN";
BA_ "SignalLongName" SG_ 1328 ROFLonPstnVelRatFA "Rearward Fusion Longitudinal Position Velocity Rationality Fault Active";
BA_ "VNSigAllNodes" SG_ 1328 ROFLonPstnVelRatFA 1;
BA_ "SignalType" SG_ 1328 ROFConfDiagFP "BLN";
BA_ "SignalLongName" SG_ 1328 ROFConfDiagFP "Rearward Fusion Confidence Diagnostic Fault Pending";
BA_ "VNSigAllNodes" SG_ 1328 ROFConfDiagFP 1;
BA_ "SignalType" SG_ 1328 ROFConfDiagFA "BLN";
BA_ "SignalLongName" SG_ 1328 ROFConfDiagFA "Rearward Fusion Confidence Diagnostic Fault Active";
BA_ "VNSigAllNodes" SG_ 1328 ROFConfDiagFA 1;
BA_ "SignalType" SG_ 1328 ROFRltvLnDiagFP "BLN";
BA_ "SignalLongName" SG_ 1328 ROFRltvLnDiagFP "Rearward Fusion Relative Lane Diagnostic Fault Pending";
BA_ "VNSigAllNodes" SG_ 1328 ROFRltvLnDiagFP 1;
BA_ "SignalType" SG_ 1328 ROFRltvLnDiagFA "BLN";
BA_ "SignalLongName" SG_ 1328 ROFRltvLnDiagFA "Rearward Fusion Relative Lane Diagnostic Fault Active";
BA_ "VNSigAllNodes" SG_ 1328 ROFRltvLnDiagFA 1;
BA_ "SignalType" SG_ 1335 BrkSysCmdAxDiagFPQ "BLN";
BA_ "SignalLongName" SG_ 1335 BrkSysCmdAxDiagFPQ "Brake System Comanded Acceleration Diagnostic Fault Pending Q";
BA_ "VNSigAllNodes" SG_ 1335 BrkSysCmdAxDiagFPQ 1;
BA_ "SignalType" SG_ 1335 BrkSysCmdAxDiagFAQ "BLN";
BA_ "SignalLongName" SG_ 1335 BrkSysCmdAxDiagFAQ "Brake System Comanded Acceleration Diagnostic Fault Active Q";
BA_ "VNSigAllNodes" SG_ 1335 BrkSysCmdAxDiagFAQ 1;
BA_ "SignalType" SG_ 1335 AxleTorqReqDiagFPQ "BLN";
BA_ "SignalLongName" SG_ 1335 AxleTorqReqDiagFPQ "Axle Torque Request Diagnostic Fault Pending Q";
BA_ "VNSigAllNodes" SG_ 1335 AxleTorqReqDiagFPQ 1;
BA_ "SignalType" SG_ 1335 AxleTorqReqDiagFAQ "BLN";
BA_ "SignalLongName" SG_ 1335 AxleTorqReqDiagFAQ "Axle Torque Request Diagnostic Fault Active Q";
BA_ "VNSigAllNodes" SG_ 1335 AxleTorqReqDiagFAQ 1;
BA_ "SignalType" SG_ 1335 AutoBrkTypeDiagFPQ "BLN";
BA_ "SignalLongName" SG_ 1335 AutoBrkTypeDiagFPQ "Auto Brake type Diagnostic Fault Pending Q";
BA_ "VNSigAllNodes" SG_ 1335 AutoBrkTypeDiagFPQ 1;
BA_ "SignalType" SG_ 1335 AutoBrkTypeDiagFAQ "BLN";
BA_ "SignalLongName" SG_ 1335 AutoBrkTypeDiagFAQ "Auto Brake type Diagnostic Fault Active Q";
BA_ "VNSigAllNodes" SG_ 1335 AutoBrkTypeDiagFAQ 1;
BA_ "SignalType" SG_ 1335 TCPHiThrtTTCFPQ "BLN";
BA_ "SignalLongName" SG_ 1335 TCPHiThrtTTCFPQ "TCP High Threat Time To Collision Fault Pending Q";
BA_ "VNSigAllNodes" SG_ 1335 TCPHiThrtTTCFPQ 1;
BA_ "SignalType" SG_ 1335 TCPHiThrtTTCFAQ "BLN";
BA_ "SignalLongName" SG_ 1335 TCPHiThrtTTCFAQ "TCP High Threat Time To Collision Fault Active Q";
BA_ "VNSigAllNodes" SG_ 1335 TCPHiThrtTTCFAQ 1;
BA_ "SignalType" SG_ 1335 TCPHiThrtTmpMemFPQ "BLN";
BA_ "SignalLongName" SG_ 1335 TCPHiThrtTmpMemFPQ "TCP Hi Threat Temporal Memory Fault Pending Q";
BA_ "VNSigAllNodes" SG_ 1335 TCPHiThrtTmpMemFPQ 1;
BA_ "SignalType" SG_ 1335 TCPHiThrtTmpMemFAQ "BLN";
BA_ "SignalLongName" SG_ 1335 TCPHiThrtTmpMemFAQ "TCP Hi Threat Temporal Memory Fault Active Q";
BA_ "VNSigAllNodes" SG_ 1335 TCPHiThrtTmpMemFAQ 1;
BA_ "SignalType" SG_ 1335 TCPHiThrtLxVxAxFPQ "BLN";
BA_ "SignalLongName" SG_ 1335 TCPHiThrtLxVxAxFPQ "TCP Hi Threat Longitudinal Position Velocity and Acceleration Fault Pending Q";
BA_ "VNSigAllNodes" SG_ 1335 TCPHiThrtLxVxAxFPQ 1;
BA_ "SignalType" SG_ 1335 TCPHiThrtLxVxAxFAQ "BLN";
BA_ "SignalLongName" SG_ 1335 TCPHiThrtLxVxAxFAQ "TCP Hi Threat Longitudinal Position Velocity and Acceleration Fault Active Q";
BA_ "VNSigAllNodes" SG_ 1335 TCPHiThrtLxVxAxFAQ 1;
BA_ "SignalType" SG_ 1335 TCPHiThrtVyFPQ "BLN";
BA_ "SignalLongName" SG_ 1335 TCPHiThrtVyFPQ "TCP Hi Threat Lateral Velocity Fault Pending Q";
BA_ "VNSigAllNodes" SG_ 1335 TCPHiThrtVyFPQ 1;
BA_ "SignalType" SG_ 1335 TCPHiThrtVyFAQ "BLN";
BA_ "SignalLongName" SG_ 1335 TCPHiThrtVyFAQ "TCP Hi Threat Lateral Velocity Fault Active Q";
BA_ "VNSigAllNodes" SG_ 1335 TCPHiThrtVyFAQ 1;
BA_ "SignalType" SG_ 1335 TCPHiThrtLyFPQ "BLN";
BA_ "SignalLongName" SG_ 1335 TCPHiThrtLyFPQ "TCP Hi Threat Lateral Position Fault Pending Q";
BA_ "VNSigAllNodes" SG_ 1335 TCPHiThrtLyFPQ 1;
BA_ "SignalType" SG_ 1335 TCPHiThrtLyFAQ "BLN";
BA_ "SignalLongName" SG_ 1335 TCPHiThrtLyFAQ "TCP Hi Threat Lateral Position Fault Active Q";
BA_ "VNSigAllNodes" SG_ 1335 TCPHiThrtLyFAQ 1;
BA_ "SignalType" SG_ 1335 TCPHiThrtConPriFPQ "BLN";
BA_ "SignalLongName" SG_ 1335 TCPHiThrtConPriFPQ "TCP Hi Threat Confidence Priority Fault Pending Q";
BA_ "VNSigAllNodes" SG_ 1335 TCPHiThrtConPriFPQ 1;
BA_ "SignalType" SG_ 1335 TCPHiThrtConPriFAQ "BLN";
BA_ "SignalLongName" SG_ 1335 TCPHiThrtConPriFAQ "TCP Hi Threat Confidence Priority Fault Active Q";
BA_ "VNSigAllNodes" SG_ 1335 TCPHiThrtConPriFAQ 1;
BA_ "SignalType" SG_ 1335 TCPHiThrtCJLFPQ "BLN";
BA_ "SignalLongName" SG_ 1335 TCPHiThrtCJLFPQ "TCP Hi Threat Collision Judgement Line Fault Pending Q";
BA_ "VNSigAllNodes" SG_ 1335 TCPHiThrtCJLFPQ 1;
BA_ "SignalType" SG_ 1335 TCPHiThrtCJLFAQ "BLN";
BA_ "SignalLongName" SG_ 1335 TCPHiThrtCJLFAQ "TCP Hi Threat Collision Judgement Line Fault Active Q";
BA_ "VNSigAllNodes" SG_ 1335 TCPHiThrtCJLFAQ 1;
BA_ "SignalType" SG_ 1335 TCPDynPropDiagFPQ "BLN";
BA_ "SignalLongName" SG_ 1335 TCPDynPropDiagFPQ "TCP Dynamic Property Diagnostic Fault Pending Q";
BA_ "VNSigAllNodes" SG_ 1335 TCPDynPropDiagFPQ 1;
BA_ "SignalType" SG_ 1335 TCPDynPropDiagFAQ "BLN";
BA_ "SignalLongName" SG_ 1335 TCPDynPropDiagFAQ "TCP Dynamic Property Diagnostic Fault Active Q";
BA_ "VNSigAllNodes" SG_ 1335 TCPDynPropDiagFAQ 1;
BA_ "SignalType" SG_ 1335 FOFRdTypInfoFPQ "BLN";
BA_ "SignalLongName" SG_ 1335 FOFRdTypInfoFPQ "Forward Fusion Road Type Information Fault Pending Q";
BA_ "VNSigAllNodes" SG_ 1335 FOFRdTypInfoFPQ 1;
BA_ "SignalType" SG_ 1335 FOFRdTypInfoFAQ "BLN";
BA_ "SignalLongName" SG_ 1335 FOFRdTypInfoFAQ "Forward Fusion Road Type Information Fault Active Q";
BA_ "VNSigAllNodes" SG_ 1335 FOFRdTypInfoFAQ 1;
BA_ "SignalType" SG_ 1335 FOFRltvLnDiagFPQ "BLN";
BA_ "SignalLongName" SG_ 1335 FOFRltvLnDiagFPQ "Forward Fusion Relative Lane Diagnostic Fault Pending Q";
BA_ "VNSigAllNodes" SG_ 1335 FOFRltvLnDiagFPQ 1;
BA_ "SignalType" SG_ 1335 FOFRltvLnDiagFAQ "BLN";
BA_ "SignalLongName" SG_ 1335 FOFRltvLnDiagFAQ "Forward Fusion Relative Lane Diagnostic Fault Active Q";
BA_ "VNSigAllNodes" SG_ 1335 FOFRltvLnDiagFAQ 1;
BA_ "SignalType" SG_ 1335 FOFNumCycDiagFPQ "BLN";
BA_ "SignalLongName" SG_ 1335 FOFNumCycDiagFPQ "Forward Fusion Numer of Cycles Diagnostic Fault Pending Q";
BA_ "VNSigAllNodes" SG_ 1335 FOFNumCycDiagFPQ 1;
BA_ "SignalType" SG_ 1335 FOFNumCycDiagFAQ "BLN";
BA_ "SignalLongName" SG_ 1335 FOFNumCycDiagFAQ "Forward Fusion Numer of Cycles Diagnostic Fault Active Q";
BA_ "VNSigAllNodes" SG_ 1335 FOFNumCycDiagFAQ 1;
BA_ "SignalType" SG_ 1335 FOFNumFusCyclsFPQ "BLN";
BA_ "SignalLongName" SG_ 1335 FOFNumFusCyclsFPQ "Forward Fusion Number of Fusion Cycles fault Pending Q";
BA_ "VNSigAllNodes" SG_ 1335 FOFNumFusCyclsFPQ 1;
BA_ "SignalType" SG_ 1335 FOFNumFusCyclsFAQ "BLN";
BA_ "SignalLongName" SG_ 1335 FOFNumFusCyclsFAQ "Forward Fusion Number of Fusion Cycles fault Active Q";
BA_ "VNSigAllNodes" SG_ 1335 FOFNumFusCyclsFAQ 1;
BA_ "SignalType" SG_ 1335 FOFNrRltvLonPstnFPQ "BLN";
BA_ "SignalLongName" SG_ 1335 FOFNrRltvLonPstnFPQ "Forward Fusion Nearest Relatiive Longitudinal Position Fault Pending Q";
BA_ "VNSigAllNodes" SG_ 1335 FOFNrRltvLonPstnFPQ 1;
BA_ "SignalType" SG_ 1335 FOFNrRltvLonPstnFAQ "BLN";
BA_ "SignalLongName" SG_ 1335 FOFNrRltvLonPstnFAQ "Forward Fusion Nearest Relatiive Longitudinal Position Fault Active Q";
BA_ "VNSigAllNodes" SG_ 1335 FOFNrRltvLonPstnFAQ 1;
BA_ "SignalType" SG_ 1335 FOFLonVelAccRatFPQ "BLN";
BA_ "SignalLongName" SG_ 1335 FOFLonVelAccRatFPQ "Forward Fusion Longitudinal Velocity and Acceleration Ratioonality Fault Pending Q";
BA_ "VNSigAllNodes" SG_ 1335 FOFLonVelAccRatFPQ 1;
BA_ "SignalType" SG_ 1335 FOFLonVelAccRatFAQ "BLN";
BA_ "SignalLongName" SG_ 1335 FOFLonVelAccRatFAQ "Forward Fusion Longitudinal Velocity and Acceleration Ratioonality Fault Active Q";
BA_ "VNSigAllNodes" SG_ 1335 FOFLonVelAccRatFAQ 1;
BA_ "SignalType" SG_ 1335 FOFLonPstnVelRatFPQ "BLN";
BA_ "SignalLongName" SG_ 1335 FOFLonPstnVelRatFPQ "Forward Fusion Longitudinal Position Velocity Rationality Fault Pending Q";
BA_ "VNSigAllNodes" SG_ 1335 FOFLonPstnVelRatFPQ 1;
BA_ "SignalType" SG_ 1335 FOFLonPstnVelRatFAQ "BLN";
BA_ "SignalLongName" SG_ 1335 FOFLonPstnVelRatFAQ "Forward Fusion Longitudinal Position Velocity Rationality Fault Active Q";
BA_ "VNSigAllNodes" SG_ 1335 FOFLonPstnVelRatFAQ 1;
BA_ "SignalType" SG_ 1335 FOFLonPosVelAccFPQ "BLN";
BA_ "SignalLongName" SG_ 1335 FOFLonPosVelAccFPQ "Forward Fusion Longitudinal Position Velocity and Acceleration Fault Pending Q";
BA_ "VNSigAllNodes" SG_ 1335 FOFLonPosVelAccFPQ 1;
BA_ "SignalType" SG_ 1335 FOFLonPosVelAccFAQ "BLN";
BA_ "SignalLongName" SG_ 1335 FOFLonPosVelAccFAQ "Forward Fusion Longitudinal Position Velocity and Acceleration Fault Active Q";
BA_ "VNSigAllNodes" SG_ 1335 FOFLonPosVelAccFAQ 1;
BA_ "SignalType" SG_ 1335 FOFLatVelDiagFPQ "BLN";
BA_ "SignalLongName" SG_ 1335 FOFLatVelDiagFPQ "Forward Fusion Lateral Velocity Diagnostic Fault Pending Q";
BA_ "VNSigAllNodes" SG_ 1335 FOFLatVelDiagFPQ 1;
BA_ "SignalType" SG_ 1335 FOFLatVelDiagFAQ "BLN";
BA_ "SignalLongName" SG_ 1335 FOFLatVelDiagFAQ "Forward Fusion Lateral Velocity Diagnostic Fault Active Q";
BA_ "VNSigAllNodes" SG_ 1335 FOFLatVelDiagFAQ 1;
BA_ "SignalType" SG_ 1335 FOFLatPstnDiagFPQ "BLN";
BA_ "SignalLongName" SG_ 1335 FOFLatPstnDiagFPQ "Forward Fusion Lateral Position Diagnostic Fault Pending Q";
BA_ "VNSigAllNodes" SG_ 1335 FOFLatPstnDiagFPQ 1;
BA_ "SignalType" SG_ 1335 FOFLatPstnDiagFAQ "BLN";
BA_ "SignalLongName" SG_ 1335 FOFLatPstnDiagFAQ "Forward Fusion Lateral Position Diagnostic Fault Active Q";
BA_ "VNSigAllNodes" SG_ 1335 FOFLatPstnDiagFAQ 1;
BA_ "SignalType" SG_ 1335 FOFConfDiagFPQ "BLN";
BA_ "SignalLongName" SG_ 1335 FOFConfDiagFPQ "Forward Fusion Confidence Diagnostic Fault Pending Q";
BA_ "VNSigAllNodes" SG_ 1335 FOFConfDiagFPQ 1;
BA_ "SignalType" SG_ 1335 FOFConfDiagFAQ "BLN";
BA_ "SignalLongName" SG_ 1335 FOFConfDiagFAQ "Forward Fusion Confidence Diagnostic Fault Active Q";
BA_ "VNSigAllNodes" SG_ 1335 FOFConfDiagFAQ 1;
BA_ "SignalType" SG_ 1335 ILFOvrlpRtlChk_FAQ "BLN";
BA_ "SignalLongName" SG_ 1335 ILFOvrlpRtlChk_FAQ "Inner Left Front Overlap rationality Check Fault Active Q";
BA_ "VNSigAllNodes" SG_ 1335 ILFOvrlpRtlChk_FAQ 1;
BA_ "SignalType" SG_ 1335 IRFOvrlpRtlChk_FAQ "BLN";
BA_ "SignalLongName" SG_ 1335 IRFOvrlpRtlChk_FAQ "Inner Right Front Overlap rationality Check Fault Active Q";
BA_ "VNSigAllNodes" SG_ 1335 IRFOvrlpRtlChk_FAQ 1;
BA_ "SignalType" SG_ 1335 LRROvrlpRtlChk_FAQ "BLN";
BA_ "SignalLongName" SG_ 1335 LRROvrlpRtlChk_FAQ "Long Range Radar Overlap rationality Check Fault Active Q";
BA_ "VNSigAllNodes" SG_ 1335 LRROvrlpRtlChk_FAQ 1;
BA_ "SignalType" SG_ 1335 VISOvrlpRtlChk_FAQ "BLN";
BA_ "SignalLongName" SG_ 1335 VISOvrlpRtlChk_FAQ "Vision Overlap rationality Check Fault Active Q";
BA_ "VNSigAllNodes" SG_ 1335 VISOvrlpRtlChk_FAQ 1;
BA_ "SignalType" SG_ 1335 VISAlign_FAQ "BLN";
BA_ "SignalLongName" SG_ 1335 VISAlign_FAQ "Vision Alignment Fault Active Q";
BA_ "VNSigAllNodes" SG_ 1335 VISAlign_FAQ 1;
BA_ "SignalType" SG_ 1335 VISSnsr_FAQ "BLN";
BA_ "SignalLongName" SG_ 1335 VISSnsr_FAQ "Vision Sensor Fault Active Q";
BA_ "VNSigAllNodes" SG_ 1335 VISSnsr_FAQ 1;
BA_ "SignalType" SG_ 1335 VISSnsr_FPQ "BLN";
BA_ "SignalLongName" SG_ 1335 VISSnsr_FPQ "Vision Sensor Fault Pending Q";
BA_ "VNSigAllNodes" SG_ 1335 VISSnsr_FPQ 1;
BA_ "SignalType" SG_ 1335 VISFrshns_FAQ "BLN";
BA_ "SignalLongName" SG_ 1335 VISFrshns_FAQ "Vision Sensor Freshness Fault Active Q";
BA_ "VNSigAllNodes" SG_ 1335 VISFrshns_FAQ 1;
BA_ "SignalType" SG_ 1335 LRRAlign_FAQ "BLN";
BA_ "SignalLongName" SG_ 1335 LRRAlign_FAQ "Long Range Radar Alignment Fault Active Q";
BA_ "VNSigAllNodes" SG_ 1335 LRRAlign_FAQ 1;
BA_ "SignalType" SG_ 1335 LRRFrshns_FAQ "BLN";
BA_ "SignalLongName" SG_ 1335 LRRFrshns_FAQ "Long Range Radar Freshness Fault Active Q";
BA_ "VNSigAllNodes" SG_ 1335 LRRFrshns_FAQ 1;
BA_ "SignalType" SG_ 1335 LRRSnsr_FAQ "BLN";
BA_ "SignalLongName" SG_ 1335 LRRSnsr_FAQ "Long Range Radar Sensor Fault Active Q";
BA_ "VNSigAllNodes" SG_ 1335 LRRSnsr_FAQ 1;
BA_ "SignalType" SG_ 1335 LRRSnsr_FPQ "BLN";
BA_ "SignalLongName" SG_ 1335 LRRSnsr_FPQ "Long Range Radar Sensor Fault Pending Q";
BA_ "VNSigAllNodes" SG_ 1335 LRRSnsr_FPQ 1;
BA_ "SignalType" SG_ 1335 IRFSRRAlign_FAQ "BLN";
BA_ "SignalLongName" SG_ 1335 IRFSRRAlign_FAQ "Inner Right Front SRR Alignment Fault Active Q";
BA_ "VNSigAllNodes" SG_ 1335 IRFSRRAlign_FAQ 1;
BA_ "SignalType" SG_ 1335 IRFSRRFrehns_FAQ "BLN";
BA_ "SignalLongName" SG_ 1335 IRFSRRFrehns_FAQ "Inner Right Front SRR Freshness Fault Active Q";
BA_ "VNSigAllNodes" SG_ 1335 IRFSRRFrehns_FAQ 1;
BA_ "SignalType" SG_ 1335 IRFSRRSnsr_FAQ "BLN";
BA_ "SignalLongName" SG_ 1335 IRFSRRSnsr_FAQ "Inner Right Front SRR Sensor Fault Active Q";
BA_ "VNSigAllNodes" SG_ 1335 IRFSRRSnsr_FAQ 1;
BA_ "SignalType" SG_ 1335 IRFSRRSnsr_FPQ "BLN";
BA_ "SignalLongName" SG_ 1335 IRFSRRSnsr_FPQ "Inner Right Front SRR Sensor Fault Pending Q";
BA_ "VNSigAllNodes" SG_ 1335 IRFSRRSnsr_FPQ 1;
BA_ "SignalType" SG_ 1335 ILFSRRSnsr_FPQ "BLN";
BA_ "SignalLongName" SG_ 1335 ILFSRRSnsr_FPQ "Inner Left Front SRR Sensor Fault Pending Q";
BA_ "VNSigAllNodes" SG_ 1335 ILFSRRSnsr_FPQ 1;
BA_ "SignalType" SG_ 1335 ILFSRRSnsr_FAQ "BLN";
BA_ "SignalLongName" SG_ 1335 ILFSRRSnsr_FAQ "Inner Left front SRR Sensor Fault Active Q";
BA_ "VNSigAllNodes" SG_ 1335 ILFSRRSnsr_FAQ 1;
BA_ "SignalType" SG_ 1335 ILFSRRFrshns_FAQ "BLN";
BA_ "SignalLongName" SG_ 1335 ILFSRRFrshns_FAQ "Inner Left Front SRR Freshness Fault Active Q";
BA_ "VNSigAllNodes" SG_ 1335 ILFSRRFrshns_FAQ 1;
BA_ "SignalType" SG_ 1335 ILFSRRAlign_FAQ "BLN";
BA_ "SignalLongName" SG_ 1335 ILFSRRAlign_FAQ "Inner Left Front SRR Alignment Fault Active Q";
BA_ "VNSigAllNodes" SG_ 1335 ILFSRRAlign_FAQ 1;
BA_ "SignalType" SG_ 1331 TCPHiThrtTmpMemFP "BLN";
BA_ "SignalLongName" SG_ 1331 TCPHiThrtTmpMemFP "TCP Hi Threat Temporal Memory Fault Pending";
BA_ "VNSigAllNodes" SG_ 1331 TCPHiThrtTmpMemFP 1;
BA_ "SignalType" SG_ 1331 TCPHiThrtTmpMemFA "BLN";
BA_ "SignalLongName" SG_ 1331 TCPHiThrtTmpMemFA "TCP Hi Threat Temporal Memory Fault Active";
BA_ "VNSigAllNodes" SG_ 1331 TCPHiThrtTmpMemFA 1;
BA_ "SignalType" SG_ 1331 TCPHiThrtConPriFP "BLN";
BA_ "SignalLongName" SG_ 1331 TCPHiThrtConPriFP "TCP Hi Threat Confidence Priority Fault Pending";
BA_ "VNSigAllNodes" SG_ 1331 TCPHiThrtConPriFP 1;
BA_ "SignalType" SG_ 1331 TCPHiThrtConPriFA "BLN";
BA_ "SignalLongName" SG_ 1331 TCPHiThrtConPriFA "TCP Hi Threat Confidence Priority Fault Active";
BA_ "VNSigAllNodes" SG_ 1331 TCPHiThrtConPriFA 1;
BA_ "SignalType" SG_ 1331 TCPHiThrtCJLFP "BLN";
BA_ "SignalLongName" SG_ 1331 TCPHiThrtCJLFP "TCP Hi Threat Collision Judgement Line Fault Pending";
BA_ "VNSigAllNodes" SG_ 1331 TCPHiThrtCJLFP 1;
BA_ "SignalType" SG_ 1331 TCPHiThrtTTCFP "BLN";
BA_ "SignalLongName" SG_ 1331 TCPHiThrtTTCFP "TCP High Threat Time To Collision Fault Pending";
BA_ "VNSigAllNodes" SG_ 1331 TCPHiThrtTTCFP 1;
BA_ "SignalType" SG_ 1331 TCPHiThrtTTCFA "BLN";
BA_ "SignalLongName" SG_ 1331 TCPHiThrtTTCFA "TCP High Threat Time To Collision Fault Active";
BA_ "VNSigAllNodes" SG_ 1331 TCPHiThrtTTCFA 1;
BA_ "SignalType" SG_ 1331 TCPHiThrtVyFP "BLN";
BA_ "SignalLongName" SG_ 1331 TCPHiThrtVyFP "TCP Hi Threat Lateral Velocity Fault Pending";
BA_ "VNSigAllNodes" SG_ 1331 TCPHiThrtVyFP 1;
BA_ "SignalType" SG_ 1331 TCPHiThrtVyFA "BLN";
BA_ "SignalLongName" SG_ 1331 TCPHiThrtVyFA "TCP Hi Threat Lateral Velocity Fault Active";
BA_ "VNSigAllNodes" SG_ 1331 TCPHiThrtVyFA 1;
BA_ "SignalType" SG_ 1331 TCPHiThrtLyFP "BLN";
BA_ "SignalLongName" SG_ 1331 TCPHiThrtLyFP "TCP Hi Threat Lateral Position Fault Pending";
BA_ "VNSigAllNodes" SG_ 1331 TCPHiThrtLyFP 1;
BA_ "SignalType" SG_ 1331 TCPHiThrtLyFA "BLN";
BA_ "SignalLongName" SG_ 1331 TCPHiThrtLyFA "TCP Hi Threat Lateral Position Fault Active";
BA_ "VNSigAllNodes" SG_ 1331 TCPHiThrtLyFA 1;
BA_ "SignalType" SG_ 1331 TCPHiThrtLxVxAxFP "BLN";
BA_ "SignalLongName" SG_ 1331 TCPHiThrtLxVxAxFP "TCP Hi Threat Longitudinal Position Velocity and Acceleration Fault Pending";
BA_ "VNSigAllNodes" SG_ 1331 TCPHiThrtLxVxAxFP 1;
BA_ "SignalType" SG_ 1331 TCPHiThrtLxVxAxFA "BLN";
BA_ "SignalLongName" SG_ 1331 TCPHiThrtLxVxAxFA "TCP Hi Threat Longitudinal Position Velocity and Acceleration Fault Active";
BA_ "VNSigAllNodes" SG_ 1331 TCPHiThrtLxVxAxFA 1;
BA_ "SignalType" SG_ 1331 FOFRdTypInfoFP "BLN";
BA_ "SignalLongName" SG_ 1331 FOFRdTypInfoFP "Forward Fusion Road Type Information Fault Pending";
BA_ "VNSigAllNodes" SG_ 1331 FOFRdTypInfoFP 1;
BA_ "SignalType" SG_ 1331 FOFRdTypInfoFA "BLN";
BA_ "SignalLongName" SG_ 1331 FOFRdTypInfoFA "Forward Fusion Road Type Information Fault Active";
BA_ "VNSigAllNodes" SG_ 1331 FOFRdTypInfoFA 1;
BA_ "SignalType" SG_ 1331 AutoBrkTypeDiagFA "BLN";
BA_ "SignalLongName" SG_ 1331 AutoBrkTypeDiagFA "Auto Brake type Diagnostic Fault Active";
BA_ "VNSigAllNodes" SG_ 1331 AutoBrkTypeDiagFA 1;
BA_ "SignalType" SG_ 1331 BrkSysCmdAxDiagFP "BLN";
BA_ "SignalLongName" SG_ 1331 BrkSysCmdAxDiagFP "Brake System Comanded Acceleration Diagnostic Fault Pending";
BA_ "VNSigAllNodes" SG_ 1331 BrkSysCmdAxDiagFP 1;
BA_ "SignalType" SG_ 1331 BrkSysCmdAxDiagFA "BLN";
BA_ "SignalLongName" SG_ 1331 BrkSysCmdAxDiagFA "Brake System Comanded Acceleration Diagnostic Fault Active";
BA_ "VNSigAllNodes" SG_ 1331 BrkSysCmdAxDiagFA 1;
BA_ "SignalType" SG_ 1331 AxleTorqReqDiagFP "BLN";
BA_ "SignalLongName" SG_ 1331 AxleTorqReqDiagFP "Axle Torque Request Diagnostic Fault Pending";
BA_ "VNSigAllNodes" SG_ 1331 AxleTorqReqDiagFP 1;
BA_ "SignalType" SG_ 1331 AxleTorqReqDiagFA "BLN";
BA_ "SignalLongName" SG_ 1331 AxleTorqReqDiagFA "Axle Torque Request Diagnostic Fault Active";
BA_ "VNSigAllNodes" SG_ 1331 AxleTorqReqDiagFA 1;
BA_ "SignalType" SG_ 1331 TCPDynPropDiagFP "BLN";
BA_ "SignalLongName" SG_ 1331 TCPDynPropDiagFP "TCP Dynamic Property Diagnostic Fault Pending";
BA_ "VNSigAllNodes" SG_ 1331 TCPDynPropDiagFP 1;
BA_ "SignalType" SG_ 1331 TCPDynPropDiagFA "BLN";
BA_ "SignalLongName" SG_ 1331 TCPDynPropDiagFA "TCP Dynamic Property Diagnostic Fault Active";
BA_ "VNSigAllNodes" SG_ 1331 TCPDynPropDiagFA 1;
BA_ "SignalType" SG_ 1331 TCPHiThrtCJLFA "BLN";
BA_ "SignalLongName" SG_ 1331 TCPHiThrtCJLFA "TCP Hi Threat Collision Judgement Line Fault Active";
BA_ "VNSigAllNodes" SG_ 1331 TCPHiThrtCJLFA 1;
BA_ "SignalType" SG_ 1331 FOFNumFusCyclsFP "BLN";
BA_ "SignalLongName" SG_ 1331 FOFNumFusCyclsFP "Forward Fusion Number of Fusion Cycles fault Pending";
BA_ "VNSigAllNodes" SG_ 1331 FOFNumFusCyclsFP 1;
BA_ "SignalType" SG_ 1331 AutoBrkTypeDiagFP "BLN";
BA_ "SignalLongName" SG_ 1331 AutoBrkTypeDiagFP "Auto Brake type Diagnostic Fault Pending";
BA_ "VNSigAllNodes" SG_ 1331 AutoBrkTypeDiagFP 1;
BA_ "SignalType" SG_ 1331 FOFNumFusCyclsFA "BLN";
BA_ "SignalLongName" SG_ 1331 FOFNumFusCyclsFA "Forward Fusion Number of Fusion Cycles fault Active";
BA_ "VNSigAllNodes" SG_ 1331 FOFNumFusCyclsFA 1;
BA_ "SignalType" SG_ 1331 FOFLatVelDiagFP "BLN";
BA_ "SignalLongName" SG_ 1331 FOFLatVelDiagFP "Forward Fusion Lateral Velocity Diagnostic Fault Pending";
BA_ "VNSigAllNodes" SG_ 1331 FOFLatVelDiagFP 1;
BA_ "SignalType" SG_ 1331 FOFLatVelDiagFA "BLN";
BA_ "SignalLongName" SG_ 1331 FOFLatVelDiagFA "Forward Fusion Lateral Velocity Diagnostic Fault Active";
BA_ "VNSigAllNodes" SG_ 1331 FOFLatVelDiagFA 1;
BA_ "SignalType" SG_ 1331 FOFLatPstnDiagFP "BLN";
BA_ "SignalLongName" SG_ 1331 FOFLatPstnDiagFP "Forward Fusion Lateral Position Diagnostic Fault Pending";
BA_ "VNSigAllNodes" SG_ 1331 FOFLatPstnDiagFP 1;
BA_ "SignalType" SG_ 1331 FOFLatPstnDiagFA "BLN";
BA_ "SignalLongName" SG_ 1331 FOFLatPstnDiagFA "Forward Fusion Lateral Position Diagnostic Fault Active";
BA_ "VNSigAllNodes" SG_ 1331 FOFLatPstnDiagFA 1;
BA_ "SignalType" SG_ 1331 FOFNumCycDiagFP "BLN";
BA_ "SignalLongName" SG_ 1331 FOFNumCycDiagFP "Forward Fusion Numer of Cycles Diagnostic Fault Pending";
BA_ "VNSigAllNodes" SG_ 1331 FOFNumCycDiagFP 1;
BA_ "SignalType" SG_ 1331 FOFNumCycDiagFA "BLN";
BA_ "SignalLongName" SG_ 1331 FOFNumCycDiagFA "Forward Fusion Numer of Cycles Diagnostic Fault Active";
BA_ "VNSigAllNodes" SG_ 1331 FOFNumCycDiagFA 1;
BA_ "SignalType" SG_ 1331 FOFRltvLnDiagFP "BLN";
BA_ "SignalLongName" SG_ 1331 FOFRltvLnDiagFP "Forward Fusion Relative Lane Diagnostic Fault Pending";
BA_ "VNSigAllNodes" SG_ 1331 FOFRltvLnDiagFP 1;
BA_ "SignalType" SG_ 1331 FOFRltvLnDiagFA "BLN";
BA_ "SignalLongName" SG_ 1331 FOFRltvLnDiagFA "Forward Fusion Relative Lane Diagnostic Fault Active";
BA_ "VNSigAllNodes" SG_ 1331 FOFRltvLnDiagFA 1;
BA_ "SignalType" SG_ 1331 FOFConfDiagFP "BLN";
BA_ "SignalLongName" SG_ 1331 FOFConfDiagFP "Forward Fusion Confidence Diagnostic Fault Pending";
BA_ "VNSigAllNodes" SG_ 1331 FOFConfDiagFP 1;
BA_ "SignalType" SG_ 1331 FOFConfDiagFA "BLN";
BA_ "SignalLongName" SG_ 1331 FOFConfDiagFA "Forward Fusion Confidence Diagnostic Fault Active";
BA_ "VNSigAllNodes" SG_ 1331 FOFConfDiagFA 1;
BA_ "SignalType" SG_ 1331 FOFLonVelAccRatFP "BLN";
BA_ "SignalLongName" SG_ 1331 FOFLonVelAccRatFP "Forward Fusion Longitudinal Velocity and Acceleration Ratioonality Fault Pending";
BA_ "VNSigAllNodes" SG_ 1331 FOFLonVelAccRatFP 1;
BA_ "SignalType" SG_ 1331 FOFLonVelAccRatFA "BLN";
BA_ "SignalLongName" SG_ 1331 FOFLonVelAccRatFA "Forward Fusion Longitudinal Velocity and Acceleration Ratioonality Fault Active";
BA_ "VNSigAllNodes" SG_ 1331 FOFLonVelAccRatFA 1;
BA_ "SignalType" SG_ 1331 FOFLonPstnVelRatFP "BLN";
BA_ "SignalLongName" SG_ 1331 FOFLonPstnVelRatFP "Forward Fusion Longitudinal Position Velocity Rationality Fault Pending";
BA_ "VNSigAllNodes" SG_ 1331 FOFLonPstnVelRatFP 1;
BA_ "SignalType" SG_ 1331 FOFLonPstnVelRatFA "BLN";
BA_ "SignalLongName" SG_ 1331 FOFLonPstnVelRatFA "Forward Fusion Longitudinal Position Velocity Rationality Fault Active";
BA_ "VNSigAllNodes" SG_ 1331 FOFLonPstnVelRatFA 1;
BA_ "SignalType" SG_ 1331 FOFNrRltvLonPstnFP "BLN";
BA_ "SignalLongName" SG_ 1331 FOFNrRltvLonPstnFP "Forward Fusion Nearest Relatiive Longitudinal Position Fault Pending";
BA_ "VNSigAllNodes" SG_ 1331 FOFNrRltvLonPstnFP 1;
BA_ "SignalType" SG_ 1331 FOFNrRltvLonPstnFA "BLN";
BA_ "SignalLongName" SG_ 1331 FOFNrRltvLonPstnFA "Forward Fusion Nearest Relatiive Longitudinal Position Fault Active";
BA_ "VNSigAllNodes" SG_ 1331 FOFNrRltvLonPstnFA 1;
BA_ "SignalType" SG_ 1331 FOFLonPosVelAccFP "BLN";
BA_ "SignalLongName" SG_ 1331 FOFLonPosVelAccFP "Forward Fusion Longitudinal Position Velocity and Acceleration Fault Pending";
BA_ "VNSigAllNodes" SG_ 1331 FOFLonPosVelAccFP 1;
BA_ "SignalType" SG_ 1331 FOFLonPosVelAccFA "BLN";
BA_ "SignalLongName" SG_ 1331 FOFLonPosVelAccFA "Forward Fusion Longitudinal Position Velocity and Acceleration Fault Active";
BA_ "VNSigAllNodes" SG_ 1331 FOFLonPosVelAccFA 1;
BA_ "SignalType" SG_ 1331 VISOvrlpRtlChk_FA "BLN";
BA_ "SignalLongName" SG_ 1331 VISOvrlpRtlChk_FA "Vision Overlap rationality Check Fault Active";
BA_ "VNSigAllNodes" SG_ 1331 VISOvrlpRtlChk_FA 1;
BA_ "SignalType" SG_ 1331 LRROvrlpRtlChk_FA "BLN";
BA_ "SignalLongName" SG_ 1331 LRROvrlpRtlChk_FA "Long Range Radar Overlap rationality Check Fault Active";
BA_ "VNSigAllNodes" SG_ 1331 LRROvrlpRtlChk_FA 1;
BA_ "SignalType" SG_ 1331 IRFOvrlpRtlChk_FA "BLN";
BA_ "SignalLongName" SG_ 1331 IRFOvrlpRtlChk_FA "Inner Right Front Overlap rationality Check Fault Active";
BA_ "VNSigAllNodes" SG_ 1331 IRFOvrlpRtlChk_FA 1;
BA_ "SignalType" SG_ 1331 ILFOvrlpRtlChk_FA "BLN";
BA_ "SignalLongName" SG_ 1331 ILFOvrlpRtlChk_FA "Inner Left Front Overlap rationality Check Fault Active";
BA_ "VNSigAllNodes" SG_ 1331 ILFOvrlpRtlChk_FA 1;
BA_ "SignalType" SG_ 1331 VISAlign_FA "BLN";
BA_ "SignalLongName" SG_ 1331 VISAlign_FA "Vision Alignment Fault Active";
BA_ "VNSigAllNodes" SG_ 1331 VISAlign_FA 1;
BA_ "SignalType" SG_ 1331 VISFrshns_FA "BLN";
BA_ "SignalLongName" SG_ 1331 VISFrshns_FA "Vision Sensor Freshness Fault Active";
BA_ "VNSigAllNodes" SG_ 1331 VISFrshns_FA 1;
BA_ "SignalType" SG_ 1331 VISSnsr_FP "BLN";
BA_ "SignalLongName" SG_ 1331 VISSnsr_FP "Vision Sensor Fault Pending";
BA_ "VNSigAllNodes" SG_ 1331 VISSnsr_FP 1;
BA_ "SignalType" SG_ 1331 VISSnsr_FA "BLN";
BA_ "SignalLongName" SG_ 1331 VISSnsr_FA "Vision Sensor Fault Active";
BA_ "VNSigAllNodes" SG_ 1331 VISSnsr_FA 1;
BA_ "SignalType" SG_ 1331 LRRAlign_FA "BLN";
BA_ "SignalLongName" SG_ 1331 LRRAlign_FA "Long Range Radar Alignment Fault Active";
BA_ "VNSigAllNodes" SG_ 1331 LRRAlign_FA 1;
BA_ "SignalType" SG_ 1331 LRRFrshns_FA "BLN";
BA_ "SignalLongName" SG_ 1331 LRRFrshns_FA "Long Range Radar Freshness Fault Active";
BA_ "VNSigAllNodes" SG_ 1331 LRRFrshns_FA 1;
BA_ "SignalType" SG_ 1331 LRRSnsr_FP "BLN";
BA_ "SignalLongName" SG_ 1331 LRRSnsr_FP "Long Range Radar Sensor Fault Pending";
BA_ "VNSigAllNodes" SG_ 1331 LRRSnsr_FP 1;
BA_ "SignalType" SG_ 1331 LRRSnsr_FA "BLN";
BA_ "SignalLongName" SG_ 1331 LRRSnsr_FA "Long Range Radar Sensor Fault Active";
BA_ "VNSigAllNodes" SG_ 1331 LRRSnsr_FA 1;
BA_ "SignalType" SG_ 1331 IRFSRRAlign_FA "BLN";
BA_ "SignalLongName" SG_ 1331 IRFSRRAlign_FA "Inner Right Front SRR Alignment Fault Active";
BA_ "VNSigAllNodes" SG_ 1331 IRFSRRAlign_FA 1;
BA_ "SignalType" SG_ 1331 IRFSRRFrehns_FA "BLN";
BA_ "SignalLongName" SG_ 1331 IRFSRRFrehns_FA "Inner Right Front SRR Freshness Fault Active";
BA_ "VNSigAllNodes" SG_ 1331 IRFSRRFrehns_FA 1;
BA_ "SignalType" SG_ 1331 IRFSRRSnsr_FP "BLN";
BA_ "SignalLongName" SG_ 1331 IRFSRRSnsr_FP "Inner Right Front SRR Sensor Fault Pending";
BA_ "VNSigAllNodes" SG_ 1331 IRFSRRSnsr_FP 1;
BA_ "SignalType" SG_ 1331 IRFSRRSnsr_FA "BLN";
BA_ "SignalLongName" SG_ 1331 IRFSRRSnsr_FA "Inner Right Front SRR Sensor Fault Active";
BA_ "VNSigAllNodes" SG_ 1331 IRFSRRSnsr_FA 1;
BA_ "SignalType" SG_ 1331 ILFSRRAlign_FA "BLN";
BA_ "SignalLongName" SG_ 1331 ILFSRRAlign_FA "Inner Left Front SRR Alignment Fault Active";
BA_ "VNSigAllNodes" SG_ 1331 ILFSRRAlign_FA 1;
BA_ "SignalType" SG_ 1331 ILFSRRFrshns_FA "BLN";
BA_ "SignalLongName" SG_ 1331 ILFSRRFrshns_FA "Inner Left Front SRR Freshness Fault Active";
BA_ "VNSigAllNodes" SG_ 1331 ILFSRRFrshns_FA 1;
BA_ "SignalType" SG_ 1331 ILFSRRSnsr_FP "BLN";
BA_ "SignalLongName" SG_ 1331 ILFSRRSnsr_FP "Inner Left Front SRR Sensor Fault Pending";
BA_ "VNSigAllNodes" SG_ 1331 ILFSRRSnsr_FP 1;
BA_ "SignalType" SG_ 1331 ILFSRRSnsr_FA "BLN";
BA_ "SignalLongName" SG_ 1331 ILFSRRSnsr_FA "Inner Left front SRR Sensor Fault Active";
BA_ "VNSigAllNodes" SG_ 1331 ILFSRRSnsr_FA 1;
BA_ "SignalType" SG_ 1787 RFSRREngRspDta "UNM";
BA_ "SignalLongName" SG_ 1787 RFSRREngRspDta "Right Front Short Range Radar Engineering Response Data";
BA_ "VNSigAllNodes" SG_ 1787 RFSRREngRspDta 1;
BA_ "SignalType" SG_ 1788 LFSRREngRspDta "UNM";
BA_ "SignalLongName" SG_ 1788 LFSRREngRspDta "Left Front Short Range Radar Engineering Response Data";
BA_ "VNSigAllNodes" SG_ 1788 LFSRREngRspDta 1;
BA_ "SignalType" SG_ 1790 RFSRREngCmdDta "UNM";
BA_ "SignalLongName" SG_ 1790 RFSRREngCmdDta "Right Front Short Range Radar Engineering Command Data";
BA_ "VNSigAllNodes" SG_ 1790 RFSRREngCmdDta 1;
BA_ "SignalType" SG_ 1791 LFSRREngCmdDta "UNM";
BA_ "SignalLongName" SG_ 1791 LFSRREngCmdDta "Left Front Short Range Radar Engineering Command Data";
BA_ "VNSigAllNodes" SG_ 1791 LFSRREngCmdDta 1;
BA_ "SignalType" SG_ 1786 RSRREngRspDta "UNM";
BA_ "SignalLongName" SG_ 1786 RSRREngRspDta "Rear Short Range Radar Engineering Response Data";
BA_ "VNSigAllNodes" SG_ 1786 RSRREngRspDta 1;
BA_ "SignalType" SG_ 1789 RSRREngCmdDta "UNM";
BA_ "SignalLongName" SG_ 1789 RSRREngCmdDta "Rear Short Range Radar Engineering Command Data";
BA_ "VNSigAllNodes" SG_ 1789 RSRREngCmdDta 1;
BA_ "SignalType" SG_ 1149 FLRRTrk20AzmthRate "SNM";
BA_ "SignalLongName" SG_ 1149 FLRRTrk20AzmthRate "Front Long Range Radar Track 20 Azimuth Rate";
BA_ "VNSigAllNodes" SG_ 1149 FLRRTrk20AzmthRate 1;
BA_ "SignalType" SG_ 1149 FLRRTrk19AzmthRate "SNM";
BA_ "SignalLongName" SG_ 1149 FLRRTrk19AzmthRate "Front Long Range Radar Track 19 Azimuth Rate";
BA_ "VNSigAllNodes" SG_ 1149 FLRRTrk19AzmthRate 1;
BA_ "SignalType" SG_ 1149 FLRRTrk18AzmthRate "SNM";
BA_ "SignalLongName" SG_ 1149 FLRRTrk18AzmthRate "Front Long Range Radar Track 18 Azimuth Rate";
BA_ "VNSigAllNodes" SG_ 1149 FLRRTrk18AzmthRate 1;
BA_ "SignalType" SG_ 1149 FLRRTrk17AzmthRate "SNM";
BA_ "SignalLongName" SG_ 1149 FLRRTrk17AzmthRate "Front Long Range Radar Track 17 Azimuth Rate";
BA_ "VNSigAllNodes" SG_ 1149 FLRRTrk17AzmthRate 1;
BA_ "SignalType" SG_ 1149 FLRRTrk16AzmthRate "SNM";
BA_ "SignalLongName" SG_ 1149 FLRRTrk16AzmthRate "Front Long Range Radar Track 16 Azimuth Rate";
BA_ "VNSigAllNodes" SG_ 1149 FLRRTrk16AzmthRate 1;
BA_ "SignalType" SG_ 1149 FLRRAzRtInf4BurstID "UNM";
BA_ "SignalLongName" SG_ 1149 FLRRAzRtInf4BurstID "Front Long Range Radar Azimuth Rate Info 4 Burst ID";
BA_ "VNSigAllNodes" SG_ 1149 FLRRAzRtInf4BurstID 1;
BA_ "SignalType" SG_ 1148 FLRRTrk15AzmthRate "SNM";
BA_ "SignalLongName" SG_ 1148 FLRRTrk15AzmthRate "Front Long Range Radar Track 15 Azimuth Rate";
BA_ "VNSigAllNodes" SG_ 1148 FLRRTrk15AzmthRate 1;
BA_ "SignalType" SG_ 1148 FLRRTrk14AzmthRate "SNM";
BA_ "SignalLongName" SG_ 1148 FLRRTrk14AzmthRate "Front Long Range Radar Track 14 Azimuth Rate";
BA_ "VNSigAllNodes" SG_ 1148 FLRRTrk14AzmthRate 1;
BA_ "SignalType" SG_ 1148 FLRRTrk13AzmthRate "SNM";
BA_ "SignalLongName" SG_ 1148 FLRRTrk13AzmthRate "Front Long Range Radar Track 13 Azimuth Rate";
BA_ "VNSigAllNodes" SG_ 1148 FLRRTrk13AzmthRate 1;
BA_ "SignalType" SG_ 1148 FLRRTrk12AzmthRate "SNM";
BA_ "SignalLongName" SG_ 1148 FLRRTrk12AzmthRate "Front Long Range Radar Track 12 Azimuth Rate";
BA_ "VNSigAllNodes" SG_ 1148 FLRRTrk12AzmthRate 1;
BA_ "SignalType" SG_ 1148 FLRRTrk11AzmthRate "SNM";
BA_ "SignalLongName" SG_ 1148 FLRRTrk11AzmthRate "Front Long Range Radar Track 11 Azimuth Rate";
BA_ "VNSigAllNodes" SG_ 1148 FLRRTrk11AzmthRate 1;
BA_ "SignalType" SG_ 1148 FLRRAzRtInf3BurstID "UNM";
BA_ "SignalLongName" SG_ 1148 FLRRAzRtInf3BurstID "Front Long Range Radar Azimuth Rate Info 3 Burst ID";
BA_ "VNSigAllNodes" SG_ 1148 FLRRAzRtInf3BurstID 1;
BA_ "SignalType" SG_ 1147 FLRRTrk9AzmthRate "SNM";
BA_ "SignalLongName" SG_ 1147 FLRRTrk9AzmthRate "Front Long Range Radar Track 9 Azimuth Rate";
BA_ "VNSigAllNodes" SG_ 1147 FLRRTrk9AzmthRate 1;
BA_ "SignalType" SG_ 1147 FLRRTrk8AzmthRate "SNM";
BA_ "SignalLongName" SG_ 1147 FLRRTrk8AzmthRate "Front Long Range Radar Track 8 Azimuth Rate";
BA_ "VNSigAllNodes" SG_ 1147 FLRRTrk8AzmthRate 1;
BA_ "SignalType" SG_ 1147 FLRRTrk7AzmthRate "SNM";
BA_ "SignalLongName" SG_ 1147 FLRRTrk7AzmthRate "Front Long Range Radar Track 7 Azimuth Rate";
BA_ "VNSigAllNodes" SG_ 1147 FLRRTrk7AzmthRate 1;
BA_ "SignalType" SG_ 1147 FLRRTrk6AzmthRate "SNM";
BA_ "SignalLongName" SG_ 1147 FLRRTrk6AzmthRate "Front Long Range Radar Track 6 Azimuth Rate";
BA_ "VNSigAllNodes" SG_ 1147 FLRRTrk6AzmthRate 1;
BA_ "SignalType" SG_ 1147 FLRRTrk10AzmthRate "SNM";
BA_ "SignalLongName" SG_ 1147 FLRRTrk10AzmthRate "Front Long Range Radar Track 10 Azimuth Rate";
BA_ "VNSigAllNodes" SG_ 1147 FLRRTrk10AzmthRate 1;
BA_ "SignalType" SG_ 1147 FLRRAzRtInf2BurstID "UNM";
BA_ "SignalLongName" SG_ 1147 FLRRAzRtInf2BurstID "Front Long Range Radar Azimuth Rate Info 2 Burst ID";
BA_ "VNSigAllNodes" SG_ 1147 FLRRAzRtInf2BurstID 1;
BA_ "SignalType" SG_ 1146 FLRRTrk5AzmthRate "SNM";
BA_ "SignalLongName" SG_ 1146 FLRRTrk5AzmthRate "Front Long Range Radar Track 5 Azimuth Rate";
BA_ "VNSigAllNodes" SG_ 1146 FLRRTrk5AzmthRate 1;
BA_ "SignalType" SG_ 1146 FLRRTrk4AzmthRate "SNM";
BA_ "SignalLongName" SG_ 1146 FLRRTrk4AzmthRate "Front Long Range Radar Track 4 Azimuth Rate";
BA_ "VNSigAllNodes" SG_ 1146 FLRRTrk4AzmthRate 1;
BA_ "SignalType" SG_ 1146 FLRRTrk3AzmthRate "SNM";
BA_ "SignalLongName" SG_ 1146 FLRRTrk3AzmthRate "Front Long Range Radar Track 3 Azimuth Rate";
BA_ "VNSigAllNodes" SG_ 1146 FLRRTrk3AzmthRate 1;
BA_ "SignalType" SG_ 1146 FLRRTrk2AzmthRate "SNM";
BA_ "SignalLongName" SG_ 1146 FLRRTrk2AzmthRate "Front Long Range Radar Track 2 Azimuth Rate";
BA_ "VNSigAllNodes" SG_ 1146 FLRRTrk2AzmthRate 1;
BA_ "SignalType" SG_ 1146 FLRRTrk1AzmthRate "SNM";
BA_ "SignalLongName" SG_ 1146 FLRRTrk1AzmthRate "Front Long Range Radar Track 1 Azimuth Rate";
BA_ "VNSigAllNodes" SG_ 1146 FLRRTrk1AzmthRate 1;
BA_ "SignalType" SG_ 1146 FLRRAzRtInf1BurstID "UNM";
BA_ "SignalLongName" SG_ 1146 FLRRAzRtInf1BurstID "Front Long Range Radar Azimuth Rate Info 1 Burst ID";
BA_ "VNSigAllNodes" SG_ 1146 FLRRAzRtInf1BurstID 1;
BA_ "SignalType" SG_ 1143 FLRRAddInfo3BurstID "UNM";
BA_ "SignalLongName" SG_ 1143 FLRRAddInfo3BurstID "Front Long Range Radar Additional Information 3 Burst ID";
BA_ "VNSigAllNodes" SG_ 1143 FLRRAddInfo3BurstID 1;
BA_ "SignalType" SG_ 1143 FLRRTrk13ObstType "ENM";
BA_ "SignalLongName" SG_ 1143 FLRRTrk13ObstType "Front Long Range Radar Obstacle Type Track 13";
BA_ "VNSigAllNodes" SG_ 1143 FLRRTrk13ObstType 1;
BA_ "SignalType" SG_ 1143 FLRRTrk20ObstTypeConf "UNM";
BA_ "SignalLongName" SG_ 1143 FLRRTrk20ObstTypeConf "Front Long Range Radar Obstacle Type Confirmation Track 20";
BA_ "VNSigAllNodes" SG_ 1143 FLRRTrk20ObstTypeConf 1;
BA_ "SignalType" SG_ 1143 FLRRTrk20ObstType "ENM";
BA_ "SignalLongName" SG_ 1143 FLRRTrk20ObstType "Front Long Range Radar Obstacle Type Track 20";
BA_ "VNSigAllNodes" SG_ 1143 FLRRTrk20ObstType 1;
BA_ "SignalType" SG_ 1143 FLRRTrk19ObstTypeConf "UNM";
BA_ "SignalLongName" SG_ 1143 FLRRTrk19ObstTypeConf "Front Long Range Radar Obstacle Type Confirmation Track 19";
BA_ "VNSigAllNodes" SG_ 1143 FLRRTrk19ObstTypeConf 1;
BA_ "SignalType" SG_ 1143 FLRRTrk19ObstType "ENM";
BA_ "SignalLongName" SG_ 1143 FLRRTrk19ObstType "Front Long Range Radar Obstacle Type Track 19";
BA_ "VNSigAllNodes" SG_ 1143 FLRRTrk19ObstType 1;
BA_ "SignalType" SG_ 1143 FLRRTrk18ObstTypeConf "UNM";
BA_ "SignalLongName" SG_ 1143 FLRRTrk18ObstTypeConf "Front Long Range Radar Obstacle Type Confirmation Track 18";
BA_ "VNSigAllNodes" SG_ 1143 FLRRTrk18ObstTypeConf 1;
BA_ "SignalType" SG_ 1143 FLRRTrk18ObstType "ENM";
BA_ "SignalLongName" SG_ 1143 FLRRTrk18ObstType "Front Long Range Radar Obstacle Type Track 18";
BA_ "VNSigAllNodes" SG_ 1143 FLRRTrk18ObstType 1;
BA_ "SignalType" SG_ 1143 FLRRTrk17ObstTypeConf "UNM";
BA_ "SignalLongName" SG_ 1143 FLRRTrk17ObstTypeConf "Front Long Range Radar Obstacle Type Confirmation Track 17";
BA_ "VNSigAllNodes" SG_ 1143 FLRRTrk17ObstTypeConf 1;
BA_ "SignalType" SG_ 1143 FLRRTrk17ObstType "ENM";
BA_ "SignalLongName" SG_ 1143 FLRRTrk17ObstType "Front Long Range Radar Obstacle Type Track 17";
BA_ "VNSigAllNodes" SG_ 1143 FLRRTrk17ObstType 1;
BA_ "SignalType" SG_ 1143 FLRRTrk16ObstTypeConf "UNM";
BA_ "SignalLongName" SG_ 1143 FLRRTrk16ObstTypeConf "Front Long Range Radar Obstacle Type Confirmation Track 16";
BA_ "VNSigAllNodes" SG_ 1143 FLRRTrk16ObstTypeConf 1;
BA_ "SignalType" SG_ 1143 FLRRTrk16ObstType "ENM";
BA_ "SignalLongName" SG_ 1143 FLRRTrk16ObstType "Front Long Range Radar Obstacle Type Track 16";
BA_ "VNSigAllNodes" SG_ 1143 FLRRTrk16ObstType 1;
BA_ "SignalType" SG_ 1143 FLRRTrk15ObstTypeConf "UNM";
BA_ "SignalLongName" SG_ 1143 FLRRTrk15ObstTypeConf "Front Long Range Radar Obstacle Type Confirmation Track 15";
BA_ "VNSigAllNodes" SG_ 1143 FLRRTrk15ObstTypeConf 1;
BA_ "SignalType" SG_ 1143 FLRRTrk15ObstType "ENM";
BA_ "SignalLongName" SG_ 1143 FLRRTrk15ObstType "Front Long Range Radar Obstacle Type Track 15";
BA_ "VNSigAllNodes" SG_ 1143 FLRRTrk15ObstType 1;
BA_ "SignalType" SG_ 1143 FLRRTrk14ObstTypeConf "UNM";
BA_ "SignalLongName" SG_ 1143 FLRRTrk14ObstTypeConf "Front Long Range Radar Obstacle Type Confirmation Track 14";
BA_ "VNSigAllNodes" SG_ 1143 FLRRTrk14ObstTypeConf 1;
BA_ "SignalType" SG_ 1143 FLRRTrk14ObstType "ENM";
BA_ "SignalLongName" SG_ 1143 FLRRTrk14ObstType "Front Long Range Radar Obstacle Type Track 14";
BA_ "VNSigAllNodes" SG_ 1143 FLRRTrk14ObstType 1;
BA_ "SignalType" SG_ 1142 FLRRAddInfo2BurstID "UNM";
BA_ "SignalLongName" SG_ 1142 FLRRAddInfo2BurstID "Front Long Range Radar Additional Information 2 Burst ID";
BA_ "VNSigAllNodes" SG_ 1142 FLRRAddInfo2BurstID 1;
BA_ "SignalType" SG_ 1142 FLRRTrk13ObstTypeConf "UNM";
BA_ "SignalLongName" SG_ 1142 FLRRTrk13ObstTypeConf "Front Long Range Radar Obstacle Type Confirmation Track 13";
BA_ "VNSigAllNodes" SG_ 1142 FLRRTrk13ObstTypeConf 1;
BA_ "SignalType" SG_ 1142 FLRRTrk12ObstTypeConf "UNM";
BA_ "SignalLongName" SG_ 1142 FLRRTrk12ObstTypeConf "Front Long Range Radar Obstacle Type Confirmation Track 12";
BA_ "VNSigAllNodes" SG_ 1142 FLRRTrk12ObstTypeConf 1;
BA_ "SignalType" SG_ 1142 FLRRTrk12ObstType "ENM";
BA_ "SignalLongName" SG_ 1142 FLRRTrk12ObstType "Front Long Range Radar Obstacle Type Track 12";
BA_ "VNSigAllNodes" SG_ 1142 FLRRTrk12ObstType 1;
BA_ "SignalType" SG_ 1142 FLRRTrk11ObstTypeConf "UNM";
BA_ "SignalLongName" SG_ 1142 FLRRTrk11ObstTypeConf "Front Long Range Radar Obstacle Type Confirmation Track 11";
BA_ "VNSigAllNodes" SG_ 1142 FLRRTrk11ObstTypeConf 1;
BA_ "SignalType" SG_ 1142 FLRRTrk11ObstType "ENM";
BA_ "SignalLongName" SG_ 1142 FLRRTrk11ObstType "Front Long Range Radar Obstacle Type Track 11";
BA_ "VNSigAllNodes" SG_ 1142 FLRRTrk11ObstType 1;
BA_ "SignalType" SG_ 1142 FLRRTrk10ObstTypeConf "UNM";
BA_ "SignalLongName" SG_ 1142 FLRRTrk10ObstTypeConf "Front Long Range Radar Obstacle Type Confirmation Track 10";
BA_ "VNSigAllNodes" SG_ 1142 FLRRTrk10ObstTypeConf 1;
BA_ "SignalType" SG_ 1142 FLRRTrk10ObstType "ENM";
BA_ "SignalLongName" SG_ 1142 FLRRTrk10ObstType "Front Long Range Radar Obstacle Type Track 10";
BA_ "VNSigAllNodes" SG_ 1142 FLRRTrk10ObstType 1;
BA_ "SignalType" SG_ 1142 FLRRTrk9ObstTypeConf "UNM";
BA_ "SignalLongName" SG_ 1142 FLRRTrk9ObstTypeConf "Front Long Range Radar Obstacle Type Confirmation Track 9";
BA_ "VNSigAllNodes" SG_ 1142 FLRRTrk9ObstTypeConf 1;
BA_ "SignalType" SG_ 1142 FLRRTrk9ObstType "ENM";
BA_ "SignalLongName" SG_ 1142 FLRRTrk9ObstType "Front Long Range Radar Obstacle Type Track 9";
BA_ "VNSigAllNodes" SG_ 1142 FLRRTrk9ObstType 1;
BA_ "SignalType" SG_ 1142 FLRRTrk8ObstTypeConf "UNM";
BA_ "SignalLongName" SG_ 1142 FLRRTrk8ObstTypeConf "Front Long Range Radar Obstacle Type Confirmation Track 8";
BA_ "VNSigAllNodes" SG_ 1142 FLRRTrk8ObstTypeConf 1;
BA_ "SignalType" SG_ 1142 FLRRTrk8ObstType "ENM";
BA_ "SignalLongName" SG_ 1142 FLRRTrk8ObstType "Front Long Range Radar Obstacle Type Track 8";
BA_ "VNSigAllNodes" SG_ 1142 FLRRTrk8ObstType 1;
BA_ "SignalType" SG_ 1142 FLRRTrk7ObstTypeConf "UNM";
BA_ "SignalLongName" SG_ 1142 FLRRTrk7ObstTypeConf "Front Long Range Radar Obstacle Type Confirmation Track 7";
BA_ "VNSigAllNodes" SG_ 1142 FLRRTrk7ObstTypeConf 1;
BA_ "SignalType" SG_ 1142 FLRRTrk7ObstType "ENM";
BA_ "SignalLongName" SG_ 1142 FLRRTrk7ObstType "Front Long Range Radar Obstacle Type Track 7";
BA_ "VNSigAllNodes" SG_ 1142 FLRRTrk7ObstType 1;
BA_ "SignalType" SG_ 1142 FLRRTrk1ObstTypeConf "UNM";
BA_ "SignalLongName" SG_ 1142 FLRRTrk1ObstTypeConf "Front Long Range Radar Obstacle Type Confirmation Track 1";
BA_ "VNSigAllNodes" SG_ 1142 FLRRTrk1ObstTypeConf 1;
BA_ "SignalType" SG_ 1142 FLRRTrk1ObstType "ENM";
BA_ "SignalLongName" SG_ 1142 FLRRTrk1ObstType "Front Long Range Radar Obstacle Type Track 1";
BA_ "VNSigAllNodes" SG_ 1142 FLRRTrk1ObstType 1;
BA_ "SignalType" SG_ 1376 R_FusHeadRollingCount "UNM";
BA_ "SignalLongName" SG_ 1376 R_FusHeadRollingCount "Rearward Fusion Header Rolling Count";
BA_ "VNSigAllNodes" SG_ 1376 R_FusHeadRollingCount 1;
BA_ "SignalType" SG_ 1376 R_FusHeadFuncState "ENM";
BA_ "SignalLongName" SG_ 1376 R_FusHeadFuncState "Rearward Fusion Header Functional State";
BA_ "VNSigAllNodes" SG_ 1376 R_FusHeadFuncState 1;
BA_ "SignalType" SG_ 1376 R_FusHedNmValTargts "UNM";
BA_ "SignalLongName" SG_ 1376 R_FusHedNmValTargts "Rearward Fusion Header Number of Valid Targets";
BA_ "VNSigAllNodes" SG_ 1376 R_FusHedNmValTargts 1;
BA_ "SignalType" SG_ 1376 R_FusHead_LrrOK "ENM";
BA_ "SignalLongName" SG_ 1376 R_FusHead_LrrOK "Rearward Fusion Header LRR OK";
BA_ "VNSigAllNodes" SG_ 1376 R_FusHead_LrrOK 1;
BA_ "SignalType" SG_ 1376 R_FusHead_LRSRROK "ENM";
BA_ "SignalLongName" SG_ 1376 R_FusHead_LRSRROK "Rearward Fusion Header LRSRR OK";
BA_ "VNSigAllNodes" SG_ 1376 R_FusHead_LRSRROK 1;
BA_ "SignalType" SG_ 1376 R_FusHead_VIsOK "ENM";
BA_ "SignalLongName" SG_ 1376 R_FusHead_VIsOK "Rearward Fusion Header VIS OK";
BA_ "VNSigAllNodes" SG_ 1376 R_FusHead_VIsOK 1;
BA_ "SignalType" SG_ 1376 R_FusHead_MapDataOK "ENM";
BA_ "SignalLongName" SG_ 1376 R_FusHead_MapDataOK "Rearward Fusion Header Map Data OK";
BA_ "VNSigAllNodes" SG_ 1376 R_FusHead_MapDataOK 1;
BA_ "SignalType" SG_ 1376 R_FusHeadTimStmpV "ENM";
BA_ "SignalLongName" SG_ 1376 R_FusHeadTimStmpV "Rearward Fusion Header Time Stamp Validity";
BA_ "VNSigAllNodes" SG_ 1376 R_FusHeadTimStmpV 1;
BA_ "SignalType" SG_ 1376 R_FusHeadTimStmp "UNM";
BA_ "SignalLongName" SG_ 1376 R_FusHeadTimStmp "Rearward Fusion Header Time Stamp";
BA_ "VNSigAllNodes" SG_ 1376 R_FusHeadTimStmp 1;
BA_ "SignalType" SG_ 1376 R_FusHead_LCSRROK "ENM";
BA_ "SignalLongName" SG_ 1376 R_FusHead_LCSRROK "Rearward Fusion Header LCSRR OK";
BA_ "VNSigAllNodes" SG_ 1376 R_FusHead_LCSRROK 1;
BA_ "SignalType" SG_ 1376 R_FusHead_RCSRROK "ENM";
BA_ "SignalLongName" SG_ 1376 R_FusHead_RCSRROK "Rearward Fusion Header RCSRR OK";
BA_ "VNSigAllNodes" SG_ 1376 R_FusHead_RCSRROK 1;
BA_ "SignalType" SG_ 1376 R_FusHead_RRSRROK "ENM";
BA_ "SignalLongName" SG_ 1376 R_FusHead_RRSRROK "Rearward Fusion Header RRSRR OK";
BA_ "VNSigAllNodes" SG_ 1376 R_FusHead_RRSRROK 1;
BA_ "SignalType" SG_ 1376 R_FusHed_ObjClstrCurv "SNM";
BA_ "SignalLongName" SG_ 1376 R_FusHed_ObjClstrCurv "Rearward Fusion Header Object Cluster Path Curvature";
BA_ "VNSigAllNodes" SG_ 1376 R_FusHed_ObjClstrCurv 1;
BA_ "SignalType" SG_ 1376 R_FusHdObjClstTanHdng "SNM";
BA_ "SignalLongName" SG_ 1376 R_FusHdObjClstTanHdng "Rearward Fusion Header Object Cluster Tangent Heading";
BA_ "VNSigAllNodes" SG_ 1376 R_FusHdObjClstTanHdng 1;
BA_ "SignalType" SG_ 851 LnSnsCrvtGrdntLft "SNM";
BA_ "SignalLongName" SG_ 851 LnSnsCrvtGrdntLft "Lane Sense Curvature Gradient Left";
BA_ "VNSigAllNodes" SG_ 851 LnSnsCrvtGrdntLft 1;
BA_ "SignalType" SG_ 851 LnSnsBurstID2 "UNM";
BA_ "SignalLongName" SG_ 851 LnSnsBurstID2 "Lane Sense Burst ID 2";
BA_ "VNSigAllNodes" SG_ 851 LnSnsBurstID2 1;
BA_ "SignalType" SG_ 850 LnSnsLnCrvtrLftV "ENM";
BA_ "SignalLongName" SG_ 850 LnSnsLnCrvtrLftV "Lane Sense Lane Curvature Left Validity";
BA_ "VNSigAllNodes" SG_ 850 LnSnsLnCrvtrLftV 1;
BA_ "SignalType" SG_ 850 LnSnsLnCrvtrLft "SNM";
BA_ "SignalLongName" SG_ 850 LnSnsLnCrvtrLft "Lane Sense Lane Curvature Left";
BA_ "VNSigAllNodes" SG_ 850 LnSnsLnCrvtrLft 1;
BA_ "SignalType" SG_ 850 LnSnsTngtOfHdngLnLftV "ENM";
BA_ "SignalLongName" SG_ 850 LnSnsTngtOfHdngLnLftV "Lane Sense Tangent Of Heading In Lane Left Validity";
BA_ "VNSigAllNodes" SG_ 850 LnSnsTngtOfHdngLnLftV 1;
BA_ "SignalType" SG_ 850 LnSnsTngtOfHdngLnLft "SNM";
BA_ "SignalLongName" SG_ 850 LnSnsTngtOfHdngLnLft "Lane Sense Tangent Of Heading In Lane Left";
BA_ "VNSigAllNodes" SG_ 850 LnSnsTngtOfHdngLnLft 1;
BA_ "SignalType" SG_ 850 LnMrkrTypRght "ENM";
BA_ "SignalLongName" SG_ 850 LnMrkrTypRght "Lane Marker Type Right";
BA_ "VNSigAllNodes" SG_ 850 LnMrkrTypRght 1;
BA_ "SignalType" SG_ 850 LnMrkrTypLft "ENM";
BA_ "SignalLongName" SG_ 850 LnMrkrTypLft "Lane Marker Type Left";
BA_ "VNSigAllNodes" SG_ 850 LnMrkrTypLft 1;
BA_ "SignalType" SG_ 850 LnMrkrElvtdRght "BLN";
BA_ "SignalLongName" SG_ 850 LnMrkrElvtdRght "Lane Marker Elevated Right";
BA_ "VNSigAllNodes" SG_ 850 LnMrkrElvtdRght 1;
BA_ "SignalType" SG_ 850 LnMrkrElvtdLft "BLN";
BA_ "SignalLongName" SG_ 850 LnMrkrElvtdLft "Lane Marker Elevated Left";
BA_ "VNSigAllNodes" SG_ 850 LnMrkrElvtdLft 1;
BA_ "SignalType" SG_ 850 LnSnsBurstID1 "UNM";
BA_ "SignalLongName" SG_ 850 LnSnsBurstID1 "Lane Sense Burst ID 1";
BA_ "VNSigAllNodes" SG_ 850 LnSnsBurstID1 1;
BA_ "SignalType" SG_ 850 LnQltyCnfdncLvlRght "UNM";
BA_ "SignalLongName" SG_ 850 LnQltyCnfdncLvlRght "Lane Quality Confidence Level Right";
BA_ "VNSigAllNodes" SG_ 850 LnQltyCnfdncLvlRght 1;
BA_ "SignalType" SG_ 850 LnQltyCnfdncLvlLft "UNM";
BA_ "SignalLongName" SG_ 850 LnQltyCnfdncLvlLft "Lane Quality Confidence Level Left";
BA_ "VNSigAllNodes" SG_ 850 LnQltyCnfdncLvlLft 1;
BA_ "SignalType" SG_ 850 LnPrvwDstncRght "UNM";
BA_ "SignalLongName" SG_ 850 LnPrvwDstncRght "Lane Preview Distance Right";
BA_ "VNSigAllNodes" SG_ 850 LnPrvwDstncRght 1;
BA_ "SignalType" SG_ 850 LnPrvwDstncLft "UNM";
BA_ "SignalLongName" SG_ 850 LnPrvwDstncLft "Lane Preview Distance Left";
BA_ "VNSigAllNodes" SG_ 850 LnPrvwDstncLft 1;
BA_REL_ "GenSigTimeoutMsg" BU_SG_REL_ EOCM_F_FO SG_ 851 LnSnsCrvtGrdntLft 851;
BA_REL_ "GenSigTimeoutMsg" BU_SG_REL_ EOCM_F_FO SG_ 851 LnSnsBurstID2 851;
VAL_ 1323 FwdFusTrkB11DynProp 4 "Moving in opposite direction" 3 "Moving in same direction as host" 2 "Has moved but currently stopped" 1 "Has never moved" 0 "Unknown" ;
VAL_ 1323 FwdFusTrkB11RelLane 3 "Left Lane" 2 "Right Lane" 1 "Host Lane" 0 "Unknown" ;
VAL_ 1323 FFusTrkB11ObjSrcLFSrr 1 "true" 0 "false" ;
VAL_ 1323 FFusTrkB11ObjSrcLCSrr 1 "true" 0 "false" ;
VAL_ 1323 FFusTrkB11ObjSrcRCSrr 1 "true" 0 "false" ;
VAL_ 1323 FFusTrkB11ObjSrcRFSrr 1 "true" 0 "false" ;
VAL_ 1323 FFusTrkB11ObjSrcVIs 1 "true" 0 "false" ;
VAL_ 1323 FwdFusTrkB11ObjSrcLrr 1 "true" 0 "false" ;
VAL_ 1322 FwdFusTrkB10DynProp 4 "Moving in opposite direction" 3 "Moving in same direction as host" 2 "Has moved but currently stopped" 1 "Has never moved" 0 "Unknown" ;
VAL_ 1322 FwdFusTrkB10RelLane 3 "Left Lane" 2 "Right Lane" 1 "Host Lane" 0 "Unknown" ;
VAL_ 1322 FFusTrkB10ObjSrcLFSrr 1 "true" 0 "false" ;
VAL_ 1322 FFusTrkB10ObjSrcLCSrr 1 "true" 0 "false" ;
VAL_ 1322 FFusTrkB10ObjSrcRCSrr 1 "true" 0 "false" ;
VAL_ 1322 FFusTrkB10ObjSrcRFSrr 1 "true" 0 "false" ;
VAL_ 1322 FFusTrkB10ObjSrcVIs 1 "true" 0 "false" ;
VAL_ 1322 FwdFusTrkB10ObjSrcLrr 1 "true" 0 "false" ;
VAL_ 1313 FwdFusTrkB1DynProp 4 "Moving in opposite direction" 3 "Moving in same direction as host" 2 "Has moved but currently stopped" 1 "Has never moved" 0 "Unknown" ;
VAL_ 1313 FwdFusTrkB1RelLane 3 "Left Lane" 2 "Right Lane" 1 "Host Lane" 0 "Unknown" ;
VAL_ 1313 FFusTrkB1ObjSrcLFSrr 1 "true" 0 "false" ;
VAL_ 1313 FFusTrkB1ObjSrcLCSrr 1 "true" 0 "false" ;
VAL_ 1313 FFusTrkB1ObjSrcRCSrr 1 "true" 0 "false" ;
VAL_ 1313 FFusTrkB1ObjSrcRFSrr 1 "true" 0 "false" ;
VAL_ 1313 FFusTrkB1ObjSrcVIs 1 "true" 0 "false" ;
VAL_ 1313 FwdFusTrkB1ObjSrcLrr 1 "true" 0 "false" ;
VAL_ 1305 FwdFusTrkA9Confidence 3 "confident" 2 "speculative" 1 "highly speculative" 0 "invalid" ;
VAL_ 1305 FwdFusTrkA9MeasStatus 3 "Measured this cycle" 2 "Latent track not detctd this cyc" 1 "New Object" 0 "No Object" ;
VAL_ 1305 FwdFusTrkA9ObjType 7 "no object present" 6 "fixed roadside object" 5 "fixed overhead object" 4 "pedestrian" 3 "motocycle  / bicycle" 2 "Large vehicle (semi)" 1 "4 Wheel Vehicle (car, small trk)" 0 "Unknown" ;
VAL_ 1304 FwdFusTrkA8Confidence 3 "confident" 2 "speculative" 1 "highly speculative" 0 "invalid" ;
VAL_ 1304 FwdFusTrkA8MeasStatus 3 "Measured this cycle" 2 "Latent track not detctd this cyc" 1 "New Object" 0 "No Object" ;
VAL_ 1304 FwdFusTrkA8ObjType 7 "no object present" 6 "fixed roadside object" 5 "fixed overhead object" 4 "pedestrian" 3 "motocycle  / bicycle" 2 "Large vehicle (semi)" 1 "4 Wheel Vehicle (car, small trk)" 0 "Unknown" ;
VAL_ 1303 FwdFusTrkA7Confidence 3 "confident" 2 "speculative" 1 "highly speculative" 0 "invalid" ;
VAL_ 1303 FwdFusTrkA7MeasStatus 3 "Measured this cycle" 2 "Latent track not detctd this cyc" 1 "New Object" 0 "No Object" ;
VAL_ 1303 FwdFusTrkA7ObjType 7 "no object present" 6 "fixed roadside object" 5 "fixed overhead object" 4 "pedestrian" 3 "motocycle  / bicycle" 2 "Large vehicle (semi)" 1 "4 Wheel Vehicle (car, small trk)" 0 "Unknown" ;
VAL_ 1302 FwdFusTrkA6Confidence 3 "confident" 2 "speculative" 1 "highly speculative" 0 "invalid" ;
VAL_ 1302 FwdFusTrkA6MeasStatus 3 "Measured this cycle" 2 "Latent track not detctd this cyc" 1 "New Object" 0 "No Object" ;
VAL_ 1302 FwdFusTrkA6ObjType 7 "no object present" 6 "fixed roadside object" 5 "fixed overhead object" 4 "pedestrian" 3 "motocycle  / bicycle" 2 "Large vehicle (semi)" 1 "4 Wheel Vehicle (car, small trk)" 0 "Unknown" ;
VAL_ 1301 FwdFusTrkA5Confidence 3 "confident" 2 "speculative" 1 "highly speculative" 0 "invalid" ;
VAL_ 1301 FwdFusTrkA5MeasStatus 3 "Measured this cycle" 2 "Latent track not detctd this cyc" 1 "New Object" 0 "No Object" ;
VAL_ 1301 FwdFusTrkA5ObjType 7 "no object present" 6 "fixed roadside object" 5 "fixed overhead object" 4 "pedestrian" 3 "motocycle  / bicycle" 2 "Large vehicle (semi)" 1 "4 Wheel Vehicle (car, small trk)" 0 "Unknown" ;
VAL_ 1300 FwdFusTrkA4Confidence 3 "confident" 2 "speculative" 1 "highly speculative" 0 "invalid" ;
VAL_ 1300 FwdFusTrkA4MeasStatus 3 "Measured this cycle" 2 "Latent track not detctd this cyc" 1 "New Object" 0 "No Object" ;
VAL_ 1300 FwdFusTrkA4ObjType 7 "no object present" 6 "fixed roadside object" 5 "fixed overhead object" 4 "pedestrian" 3 "motocycle  / bicycle" 2 "Large vehicle (semi)" 1 "4 Wheel Vehicle (car, small trk)" 0 "Unknown" ;
VAL_ 1299 FwdFusTrkA3Confidence 3 "confident" 2 "speculative" 1 "highly speculative" 0 "invalid" ;
VAL_ 1299 FwdFusTrkA3MeasStatus 3 "Measured this cycle" 2 "Latent track not detctd this cyc" 1 "New Object" 0 "No Object" ;
VAL_ 1299 FwdFusTrkA3ObjType 7 "no object present" 6 "fixed roadside object" 5 "fixed overhead object" 4 "pedestrian" 3 "motocycle  / bicycle" 2 "Large vehicle (semi)" 1 "4 Wheel Vehicle (car, small trk)" 0 "Unknown" ;
VAL_ 1298 FwdFusTrkA2Confidence 3 "confident" 2 "speculative" 1 "highly speculative" 0 "invalid" ;
VAL_ 1298 FwdFusTrkA2MeasStatus 3 "Measured this cycle" 2 "Latent track not detctd this cyc" 1 "New Object" 0 "No Object" ;
VAL_ 1298 FwdFusTrkA2ObjType 7 "no object present" 6 "fixed roadside object" 5 "fixed overhead object" 4 "pedestrian" 3 "motocycle  / bicycle" 2 "Large vehicle (semi)" 1 "4 Wheel Vehicle (car, small trk)" 0 "Unknown" ;
VAL_ 1311 FwdFusTrkA15Confidence 3 "confident" 2 "speculative" 1 "highly speculative" 0 "invalid" ;
VAL_ 1311 FwdFusTrkA15MeasStatus 3 "Measured this cycle" 2 "Latent track not detctd this cyc" 1 "New Object" 0 "No Object" ;
VAL_ 1311 FwdFusTrkA15ObjType 7 "no object present" 6 "fixed roadside object" 5 "fixed overhead object" 4 "pedestrian" 3 "motocycle  / bicycle" 2 "Large vehicle (semi)" 1 "4 Wheel Vehicle (car, small trk)" 0 "Unknown" ;
VAL_ 1310 FwdFusTrkA14Confidence 3 "confident" 2 "speculative" 1 "highly speculative" 0 "invalid" ;
VAL_ 1310 FwdFusTrkA14MeasStatus 3 "Measured this cycle" 2 "Latent track not detctd this cyc" 1 "New Object" 0 "No Object" ;
VAL_ 1310 FwdFusTrkA14ObjType 7 "no object present" 6 "fixed roadside object" 5 "fixed overhead object" 4 "pedestrian" 3 "motocycle  / bicycle" 2 "Large vehicle (semi)" 1 "4 Wheel Vehicle (car, small trk)" 0 "Unknown" ;
VAL_ 1309 FwdFusTrkA13Confidence 3 "confident" 2 "speculative" 1 "highly speculative" 0 "invalid" ;
VAL_ 1309 FwdFusTrkA13MeasStatus 3 "Measured this cycle" 2 "Latent track not detctd this cyc" 1 "New Object" 0 "No Object" ;
VAL_ 1309 FwdFusTrkA13ObjType 7 "no object present" 6 "fixed roadside object" 5 "fixed overhead object" 4 "pedestrian" 3 "motocycle  / bicycle" 2 "Large vehicle (semi)" 1 "4 Wheel Vehicle (car, small trk)" 0 "Unknown" ;
VAL_ 1308 FwdFusTrkA12Confidence 3 "confident" 2 "speculative" 1 "highly speculative" 0 "invalid" ;
VAL_ 1308 FwdFusTrkA12MeasStatus 3 "Measured this cycle" 2 "Latent track not detctd this cyc" 1 "New Object" 0 "No Object" ;
VAL_ 1308 FwdFusTrkA12ObjType 7 "no object present" 6 "fixed roadside object" 5 "fixed overhead object" 4 "pedestrian" 3 "motocycle  / bicycle" 2 "Large vehicle (semi)" 1 "4 Wheel Vehicle (car, small trk)" 0 "Unknown" ;
VAL_ 1307 FwdFusTrkA11Confidence 3 "confident" 2 "speculative" 1 "highly speculative" 0 "invalid" ;
VAL_ 1307 FwdFusTrkA11MeasStatus 3 "Measured this cycle" 2 "Latent track not detctd this cyc" 1 "New Object" 0 "No Object" ;
VAL_ 1307 FwdFusTrkA11ObjType 7 "no object present" 6 "fixed roadside object" 5 "fixed overhead object" 4 "pedestrian" 3 "motocycle  / bicycle" 2 "Large vehicle (semi)" 1 "4 Wheel Vehicle (car, small trk)" 0 "Unknown" ;
VAL_ 1306 FwdFusTrkA10Confidence 3 "confident" 2 "speculative" 1 "highly speculative" 0 "invalid" ;
VAL_ 1306 FwdFusTrkA10MeasStatus 3 "Measured this cycle" 2 "Latent track not detctd this cyc" 1 "New Object" 0 "No Object" ;
VAL_ 1306 FwdFusTrkA10ObjType 7 "no object present" 6 "fixed roadside object" 5 "fixed overhead object" 4 "pedestrian" 3 "motocycle  / bicycle" 2 "Large vehicle (semi)" 1 "4 Wheel Vehicle (car, small trk)" 0 "Unknown" ;
VAL_ 1297 FwdFusTrkA1Confidence 3 "confident" 2 "speculative" 1 "highly speculative" 0 "invalid" ;
VAL_ 1297 FwdFusTrkA1MeasStatus 3 "Measured this cycle" 2 "Latent track not detctd this cyc" 1 "New Object" 0 "No Object" ;
VAL_ 1297 FwdFusTrkA1ObjType 7 "no object present" 6 "fixed roadside object" 5 "fixed overhead object" 4 "pedestrian" 3 "motocycle  / bicycle" 2 "Large vehicle (semi)" 1 "4 Wheel Vehicle (car, small trk)" 0 "Unknown" ;
VAL_ 1296 F_FusHeadFuncState 3 "Undefined" 2 "Run" 1 "Disabled" 0 "Off" ;
VAL_ 1296 F_FusHead_LrrOK 1 "true" 0 "false" ;
VAL_ 1296 F_FusHead_LFSRROK 1 "true" 0 "false" ;
VAL_ 1296 F_FusHead_VIsOK 1 "true" 0 "false" ;
VAL_ 1296 F_FusHead_MapDataOK 1 "true" 0 "false" ;
VAL_ 1296 F_FusHeadTimStmpV 1 "Invalid" 0 "Valid" ;
VAL_ 1296 F_FusHead_LCSRROK 1 "true" 0 "false" ;
VAL_ 1296 F_FusHead_RCSRROK 1 "true" 0 "false" ;
VAL_ 1296 F_FusHead_RFSRROK 1 "true" 0 "false" ;
VAL_ 1296 RoadTypeInfo 5 "Constiction Zone Exit" 4 "Construction Zone Entry" 3 "Highway" 2 "Secondary Road" 1 "City" 0 "Unknown" ;
VAL_ 1338 FrtRWARateDiagFA 1 "true" 0 "false" ;
VAL_ 1338 FrtRWABiasDiagFA 1 "true" 0 "false" ;
VAL_ 1338 HWAFrtVal 1 "true" 0 "false" ;
VAL_ 1338 HWADotValFrt 1 "true" 0 "false" ;
VAL_ 1338 S2VehAxRangeFA 1 "true" 0 "false" ;
VAL_ 1338 S2VehAxRateFA 1 "true" 0 "false" ;
VAL_ 1338 S2VehAxBiasFA 1 "true" 0 "false" ;
VAL_ 1338 VehAxCompFA 1 "true" 0 "false" ;
VAL_ 1338 S1VehAxVal 1 "true" 0 "false" ;
VAL_ 1338 S2VehAxVal 1 "true" 0 "false" ;
VAL_ 1338 FrtRWACorrFA 1 "true" 0 "false" ;
VAL_ 1338 FrtRWARangeDiagFA 1 "true" 0 "false" ;
VAL_ 1338 S2VehAyBiasFA 1 "true" 0 "false" ;
VAL_ 1338 VehAyCompFA 1 "true" 0 "false" ;
VAL_ 1338 S1VehAyVal 1 "true" 0 "false" ;
VAL_ 1338 S2VehAyVal 1 "true" 0 "false" ;
VAL_ 1338 VehAxCorrFA 1 "true" 0 "false" ;
VAL_ 1338 S1VehAxRangeFA 1 "true" 0 "false" ;
VAL_ 1338 S1VehAxRateFA 1 "true" 0 "false" ;
VAL_ 1338 S1VehAxBiasFA 1 "true" 0 "false" ;
VAL_ 1338 S1VehWzVal 1 "true" 0 "false" ;
VAL_ 1338 S2VehWzVal 1 "true" 0 "false" ;
VAL_ 1338 VehAyCorrDiagFA 1 "true" 0 "false" ;
VAL_ 1338 S1VehAyRangeFA 1 "true" 0 "false" ;
VAL_ 1338 S1VehAyRateFA 1 "true" 0 "false" ;
VAL_ 1338 S1VehAyBiasFA 1 "true" 0 "false" ;
VAL_ 1338 S2VehAyRangeFA 1 "true" 0 "false" ;
VAL_ 1338 S2VehAyRateFA 1 "true" 0 "false" ;
VAL_ 1338 VehWzCorrDiagFA 1 "true" 0 "false" ;
VAL_ 1338 S1VehWzRangeFA 1 "true" 0 "false" ;
VAL_ 1338 S1VehWzRateFA 1 "true" 0 "false" ;
VAL_ 1338 S1VehWzBiasFA 1 "true" 0 "false" ;
VAL_ 1338 S2VehWzRangeFA 1 "true" 0 "false" ;
VAL_ 1338 S2VehWzRateFA 1 "true" 0 "false" ;
VAL_ 1338 S2VehWzBiasFA 1 "true" 0 "false" ;
VAL_ 1338 VehWzCompFA 1 "true" 0 "false" ;
VAL_ 1338 WhlVxLFCorrDiagFA 1 "true" 0 "false" ;
VAL_ 1338 WhlVxRFCorrDiagFA 1 "true" 0 "false" ;
VAL_ 1338 WhlVxLRCorrDiagFA 1 "true" 0 "false" ;
VAL_ 1338 WhlVxRRCorrDiagFA 1 "true" 0 "false" ;
VAL_ 1338 WhlLFVal 1 "true" 0 "false" ;
VAL_ 1338 WhlRFVal 1 "true" 0 "false" ;
VAL_ 1338 WhlLRVal 1 "true" 0 "false" ;
VAL_ 1338 WhlRRVal 1 "true" 0 "false" ;
VAL_ 1328 AlrtWrnIndReqFP 1 "true" 0 "false" ;
VAL_ 1328 AlrtWrnIndReqFA 1 "true" 0 "false" ;
VAL_ 1328 ILRSRRSnsr_FP 1 "true" 0 "false" ;
VAL_ 1328 ILRSRRSnsr_FA 1 "true" 0 "false" ;
VAL_ 1328 ILRSRRFrehns_FA 1 "true" 0 "false" ;
VAL_ 1328 VehPathEstCrvCSFP 1 "true" 0 "false" ;
VAL_ 1328 VehPathEstCrvCSFA 1 "true" 0 "false" ;
VAL_ 1328 VehPathWzEstCSFP 1 "true" 0 "false" ;
VAL_ 1328 VehPathWzEstCSFA 1 "true" 0 "false" ;
VAL_ 1328 VehPathVyEstCSFP 1 "true" 0 "false" ;
VAL_ 1328 VehPathVyEstCSFA 1 "true" 0 "false" ;
VAL_ 1328 VehPathVxEstCSFP 1 "true" 0 "false" ;
VAL_ 1328 VehPathVxEstCSFA 1 "true" 0 "false" ;
VAL_ 1328 TCPHiThrtTTCCSFP 1 "true" 0 "false" ;
VAL_ 1328 TCPHiThrtTTCCSFA 1 "true" 0 "false" ;
VAL_ 1328 TCPHiThrtLyCSFP 1 "true" 0 "false" ;
VAL_ 1328 TCPHiThrtLyCSFA 1 "true" 0 "false" ;
VAL_ 1328 TCPHiThLxVxAxCSFP 1 "true" 0 "false" ;
VAL_ 1328 TCPHiThLxVxAxCSFA 1 "true" 0 "false" ;
VAL_ 1328 CurSetValDiagFP 1 "true" 0 "false" ;
VAL_ 1328 CurSetValDiagFA 1 "true" 0 "false" ;
VAL_ 1328 CrsAltDvrSlTpDiagFP 1 "true" 0 "false" ;
VAL_ 1328 CrsAltDvrSlTpDiagFA 1 "true" 0 "false" ;
VAL_ 1328 FCAStatDiagFP 1 "true" 0 "false" ;
VAL_ 1328 FCAStatDiagFA 1 "true" 0 "false" ;
VAL_ 1328 RVBBrkCtrlStFP 1 "true" 0 "false" ;
VAL_ 1328 RVBBrkCtrlStFA 1 "true" 0 "false" ;
VAL_ 1328 RVBOpStFP 1 "true" 0 "false" ;
VAL_ 1328 RVBOpStFA 1 "true" 0 "false" ;
VAL_ 1328 RVBBrkCtrlAccFP 1 "true" 0 "false" ;
VAL_ 1328 RVBBrkCtrlAccFA 1 "true" 0 "false" ;
VAL_ 1328 RVBAxlTrqRqFP 1 "true" 0 "false" ;
VAL_ 1328 RVBAxlTrqRqFA 1 "true" 0 "false" ;
VAL_ 1328 TVRUPATTCFP 1 "true" 0 "false" ;
VAL_ 1328 TVRUPATTCFA 1 "true" 0 "false" ;
VAL_ 1328 TVRHiThrtObjIDFP 1 "true" 0 "false" ;
VAL_ 1328 TVRHiThrtObjIDFA 1 "true" 0 "false" ;
VAL_ 1328 TVRHiThrtTTCFP 1 "true" 0 "false" ;
VAL_ 1328 TVRHiThrtTTCFA 1 "true" 0 "false" ;
VAL_ 1328 TVRHiThrtLxFP 1 "true" 0 "false" ;
VAL_ 1328 TVRHiThrtLxFA 1 "true" 0 "false" ;
VAL_ 1328 TVRHiThrtLyFP 1 "true" 0 "false" ;
VAL_ 1328 TVRHiThrtLyFA 1 "true" 0 "false" ;
VAL_ 1328 ROFFuncStFP 1 "true" 0 "false" ;
VAL_ 1328 ROFFuncStFA 1 "true" 0 "false" ;
VAL_ 1328 ROFObjIDFP 1 "true" 0 "false" ;
VAL_ 1328 ROFObjIDFA 1 "true" 0 "false" ;
VAL_ 1328 ROFLatPstnVelRatFP 1 "true" 0 "false" ;
VAL_ 1328 ROFLatPstnVelRatFA 1 "true" 0 "false" ;
VAL_ 1328 ROFLonPstnVelFP 1 "true" 0 "false" ;
VAL_ 1328 ROFLonPstnVelFA 1 "true" 0 "false" ;
VAL_ 1328 ROFRltvLatVelDiagFP 1 "true" 0 "false" ;
VAL_ 1328 ROFRltvLatVelDiagFA 1 "true" 0 "false" ;
VAL_ 1328 ROFRltvLatPstnDiagFP 1 "true" 0 "false" ;
VAL_ 1328 ROFRltvLatPstnDiagFA 1 "true" 0 "false" ;
VAL_ 1328 ROFNrRltvLonPstnFP 1 "true" 0 "false" ;
VAL_ 1328 ROFNrRltvLonPstnFA 1 "true" 0 "false" ;
VAL_ 1328 ROFLonPstnVelRatFP 1 "true" 0 "false" ;
VAL_ 1328 ROFLonPstnVelRatFA 1 "true" 0 "false" ;
VAL_ 1328 ROFConfDiagFP 1 "true" 0 "false" ;
VAL_ 1328 ROFConfDiagFA 1 "true" 0 "false" ;
VAL_ 1328 ROFRltvLnDiagFP 1 "true" 0 "false" ;
VAL_ 1328 ROFRltvLnDiagFA 1 "true" 0 "false" ;
VAL_ 1335 BrkSysCmdAxDiagFPQ 1 "true" 0 "false" ;
VAL_ 1335 BrkSysCmdAxDiagFAQ 1 "true" 0 "false" ;
VAL_ 1335 AxleTorqReqDiagFPQ 1 "true" 0 "false" ;
VAL_ 1335 AxleTorqReqDiagFAQ 1 "true" 0 "false" ;
VAL_ 1335 AutoBrkTypeDiagFPQ 1 "true" 0 "false" ;
VAL_ 1335 AutoBrkTypeDiagFAQ 1 "true" 0 "false" ;
VAL_ 1335 TCPHiThrtTTCFPQ 1 "true" 0 "false" ;
VAL_ 1335 TCPHiThrtTTCFAQ 1 "true" 0 "false" ;
VAL_ 1335 TCPHiThrtTmpMemFPQ 1 "true" 0 "false" ;
VAL_ 1335 TCPHiThrtTmpMemFAQ 1 "true" 0 "false" ;
VAL_ 1335 TCPHiThrtLxVxAxFPQ 1 "true" 0 "false" ;
VAL_ 1335 TCPHiThrtLxVxAxFAQ 1 "true" 0 "false" ;
VAL_ 1335 TCPHiThrtVyFPQ 1 "true" 0 "false" ;
VAL_ 1335 TCPHiThrtVyFAQ 1 "true" 0 "false" ;
VAL_ 1335 TCPHiThrtLyFPQ 1 "true" 0 "false" ;
VAL_ 1335 TCPHiThrtLyFAQ 1 "true" 0 "false" ;
VAL_ 1335 TCPHiThrtConPriFPQ 1 "true" 0 "false" ;
VAL_ 1335 TCPHiThrtConPriFAQ 1 "true" 0 "false" ;
VAL_ 1335 TCPHiThrtCJLFPQ 1 "true" 0 "false" ;
VAL_ 1335 TCPHiThrtCJLFAQ 1 "true" 0 "false" ;
VAL_ 1335 TCPDynPropDiagFPQ 1 "true" 0 "false" ;
VAL_ 1335 TCPDynPropDiagFAQ 1 "true" 0 "false" ;
VAL_ 1335 FOFRdTypInfoFPQ 1 "true" 0 "false" ;
VAL_ 1335 FOFRdTypInfoFAQ 1 "true" 0 "false" ;
VAL_ 1335 FOFRltvLnDiagFPQ 1 "true" 0 "false" ;
VAL_ 1335 FOFRltvLnDiagFAQ 1 "true" 0 "false" ;
VAL_ 1335 FOFNumCycDiagFPQ 1 "true" 0 "false" ;
VAL_ 1335 FOFNumCycDiagFAQ 1 "true" 0 "false" ;
VAL_ 1335 FOFNumFusCyclsFPQ 1 "true" 0 "false" ;
VAL_ 1335 FOFNumFusCyclsFAQ 1 "true" 0 "false" ;
VAL_ 1335 FOFNrRltvLonPstnFPQ 1 "true" 0 "false" ;
VAL_ 1335 FOFNrRltvLonPstnFAQ 1 "true" 0 "false" ;
VAL_ 1335 FOFLonVelAccRatFPQ 1 "true" 0 "false" ;
VAL_ 1335 FOFLonVelAccRatFAQ 1 "true" 0 "false" ;
VAL_ 1335 FOFLonPstnVelRatFPQ 1 "true" 0 "false" ;
VAL_ 1335 FOFLonPstnVelRatFAQ 1 "true" 0 "false" ;
VAL_ 1335 FOFLonPosVelAccFPQ 1 "true" 0 "false" ;
VAL_ 1335 FOFLonPosVelAccFAQ 1 "true" 0 "false" ;
VAL_ 1335 FOFLatVelDiagFPQ 1 "true" 0 "false" ;
VAL_ 1335 FOFLatVelDiagFAQ 1 "true" 0 "false" ;
VAL_ 1335 FOFLatPstnDiagFPQ 1 "true" 0 "false" ;
VAL_ 1335 FOFLatPstnDiagFAQ 1 "true" 0 "false" ;
VAL_ 1335 FOFConfDiagFPQ 1 "true" 0 "false" ;
VAL_ 1335 FOFConfDiagFAQ 1 "true" 0 "false" ;
VAL_ 1335 ILFOvrlpRtlChk_FAQ 1 "true" 0 "false" ;
VAL_ 1335 IRFOvrlpRtlChk_FAQ 1 "true" 0 "false" ;
VAL_ 1335 LRROvrlpRtlChk_FAQ 1 "true" 0 "false" ;
VAL_ 1335 VISOvrlpRtlChk_FAQ 1 "true" 0 "false" ;
VAL_ 1335 VISAlign_FAQ 1 "true" 0 "false" ;
VAL_ 1335 VISSnsr_FAQ 1 "true" 0 "false" ;
VAL_ 1335 VISSnsr_FPQ 1 "true" 0 "false" ;
VAL_ 1335 VISFrshns_FAQ 1 "true" 0 "false" ;
VAL_ 1335 LRRAlign_FAQ 1 "true" 0 "false" ;
VAL_ 1335 LRRFrshns_FAQ 1 "true" 0 "false" ;
VAL_ 1335 LRRSnsr_FAQ 1 "true" 0 "false" ;
VAL_ 1335 LRRSnsr_FPQ 1 "true" 0 "false" ;
VAL_ 1335 IRFSRRAlign_FAQ 1 "true" 0 "false" ;
VAL_ 1335 IRFSRRFrehns_FAQ 1 "true" 0 "false" ;
VAL_ 1335 IRFSRRSnsr_FAQ 1 "true" 0 "false" ;
VAL_ 1335 IRFSRRSnsr_FPQ 1 "true" 0 "false" ;
VAL_ 1335 ILFSRRSnsr_FPQ 1 "true" 0 "false" ;
VAL_ 1335 ILFSRRSnsr_FAQ 1 "true" 0 "false" ;
VAL_ 1335 ILFSRRFrshns_FAQ 1 "true" 0 "false" ;
VAL_ 1335 ILFSRRAlign_FAQ 1 "true" 0 "false" ;
VAL_ 1331 TCPHiThrtTmpMemFP 1 "true" 0 "false" ;
VAL_ 1331 TCPHiThrtTmpMemFA 1 "true" 0 "false" ;
VAL_ 1331 TCPHiThrtConPriFP 1 "true" 0 "false" ;
VAL_ 1331 TCPHiThrtConPriFA 1 "true" 0 "false" ;
VAL_ 1331 TCPHiThrtCJLFP 1 "true" 0 "false" ;
VAL_ 1331 TCPHiThrtTTCFP 1 "true" 0 "false" ;
VAL_ 1331 TCPHiThrtTTCFA 1 "true" 0 "false" ;
VAL_ 1331 TCPHiThrtVyFP 1 "true" 0 "false" ;
VAL_ 1331 TCPHiThrtVyFA 1 "true" 0 "false" ;
VAL_ 1331 TCPHiThrtLyFP 1 "true" 0 "false" ;
VAL_ 1331 TCPHiThrtLyFA 1 "true" 0 "false" ;
VAL_ 1331 TCPHiThrtLxVxAxFP 1 "true" 0 "false" ;
VAL_ 1331 TCPHiThrtLxVxAxFA 1 "true" 0 "false" ;
VAL_ 1331 FOFRdTypInfoFP 1 "true" 0 "false" ;
VAL_ 1331 FOFRdTypInfoFA 1 "true" 0 "false" ;
VAL_ 1331 AutoBrkTypeDiagFA 1 "true" 0 "false" ;
VAL_ 1331 BrkSysCmdAxDiagFP 1 "true" 0 "false" ;
VAL_ 1331 BrkSysCmdAxDiagFA 1 "true" 0 "false" ;
VAL_ 1331 AxleTorqReqDiagFP 1 "true" 0 "false" ;
VAL_ 1331 AxleTorqReqDiagFA 1 "true" 0 "false" ;
VAL_ 1331 TCPDynPropDiagFP 1 "true" 0 "false" ;
VAL_ 1331 TCPDynPropDiagFA 1 "true" 0 "false" ;
VAL_ 1331 TCPHiThrtCJLFA 1 "true" 0 "false" ;
VAL_ 1331 FOFNumFusCyclsFP 1 "true" 0 "false" ;
VAL_ 1331 AutoBrkTypeDiagFP 1 "true" 0 "false" ;
VAL_ 1331 FOFNumFusCyclsFA 1 "true" 0 "false" ;
VAL_ 1331 FOFLatVelDiagFP 1 "true" 0 "false" ;
VAL_ 1331 FOFLatVelDiagFA 1 "true" 0 "false" ;
VAL_ 1331 FOFLatPstnDiagFP 1 "true" 0 "false" ;
VAL_ 1331 FOFLatPstnDiagFA 1 "true" 0 "false" ;
VAL_ 1331 FOFNumCycDiagFP 1 "true" 0 "false" ;
VAL_ 1331 FOFNumCycDiagFA 1 "true" 0 "false" ;
VAL_ 1331 FOFRltvLnDiagFP 1 "true" 0 "false" ;
VAL_ 1331 FOFRltvLnDiagFA 1 "true" 0 "false" ;
VAL_ 1331 FOFConfDiagFP 1 "true" 0 "false" ;
VAL_ 1331 FOFConfDiagFA 1 "true" 0 "false" ;
VAL_ 1331 FOFLonVelAccRatFP 1 "true" 0 "false" ;
VAL_ 1331 FOFLonVelAccRatFA 1 "true" 0 "false" ;
VAL_ 1331 FOFLonPstnVelRatFP 1 "true" 0 "false" ;
VAL_ 1331 FOFLonPstnVelRatFA 1 "true" 0 "false" ;
VAL_ 1331 FOFNrRltvLonPstnFP 1 "true" 0 "false" ;
VAL_ 1331 FOFNrRltvLonPstnFA 1 "true" 0 "false" ;
VAL_ 1331 FOFLonPosVelAccFP 1 "true" 0 "false" ;
VAL_ 1331 FOFLonPosVelAccFA 1 "true" 0 "false" ;
VAL_ 1331 VISOvrlpRtlChk_FA 1 "true" 0 "false" ;
VAL_ 1331 LRROvrlpRtlChk_FA 1 "true" 0 "false" ;
VAL_ 1331 IRFOvrlpRtlChk_FA 1 "true" 0 "false" ;
VAL_ 1331 ILFOvrlpRtlChk_FA 1 "true" 0 "false" ;
VAL_ 1331 VISAlign_FA 1 "true" 0 "false" ;
VAL_ 1331 VISFrshns_FA 1 "true" 0 "false" ;
VAL_ 1331 VISSnsr_FP 1 "true" 0 "false" ;
VAL_ 1331 VISSnsr_FA 1 "true" 0 "false" ;
VAL_ 1331 LRRAlign_FA 1 "true" 0 "false" ;
VAL_ 1331 LRRFrshns_FA 1 "true" 0 "false" ;
VAL_ 1331 LRRSnsr_FP 1 "true" 0 "false" ;
VAL_ 1331 LRRSnsr_FA 1 "true" 0 "false" ;
VAL_ 1331 IRFSRRAlign_FA 1 "true" 0 "false" ;
VAL_ 1331 IRFSRRFrehns_FA 1 "true" 0 "false" ;
VAL_ 1331 IRFSRRSnsr_FP 1 "true" 0 "false" ;
VAL_ 1331 IRFSRRSnsr_FA 1 "true" 0 "false" ;
VAL_ 1331 ILFSRRAlign_FA 1 "true" 0 "false" ;
VAL_ 1331 ILFSRRFrshns_FA 1 "true" 0 "false" ;
VAL_ 1331 ILFSRRSnsr_FP 1 "true" 0 "false" ;
VAL_ 1331 ILFSRRSnsr_FA 1 "true" 0 "false" ;
VAL_ 1143 FLRRTrk13ObstType 6 "NO_OBJECT" 5 "OBJ_GUARDRAIL" 4 "OBJ_TUNNEL " 3 "OBJ_TRAFFIC_SIGN" 2 "OBJ_VEHICLE" 1 "OBJ_BRIDGE " 0 "OBJ_UNKNOWN" ;
VAL_ 1143 FLRRTrk20ObstType 6 "NO_OBJECT" 5 "OBJ_GUARDRAIL" 4 "OBJ_TUNNEL " 3 "OBJ_TRAFFIC_SIGN" 2 "OBJ_VEHICLE" 1 "OBJ_BRIDGE " 0 "OBJ_UNKNOWN" ;
VAL_ 1143 FLRRTrk19ObstType 6 "NO_OBJECT" 5 "OBJ_GUARDRAIL" 4 "OBJ_TUNNEL " 3 "OBJ_TRAFFIC_SIGN" 2 "OBJ_VEHICLE" 1 "OBJ_BRIDGE " 0 "OBJ_UNKNOWN" ;
VAL_ 1143 FLRRTrk18ObstType 6 "NO_OBJECT" 5 "OBJ_GUARDRAIL" 4 "OBJ_TUNNEL " 3 "OBJ_TRAFFIC_SIGN" 2 "OBJ_VEHICLE" 1 "OBJ_BRIDGE " 0 "OBJ_UNKNOWN" ;
VAL_ 1143 FLRRTrk17ObstType 6 "NO_OBJECT" 5 "OBJ_GUARDRAIL" 4 "OBJ_TUNNEL " 3 "OBJ_TRAFFIC_SIGN" 2 "OBJ_VEHICLE" 1 "OBJ_BRIDGE " 0 "OBJ_UNKNOWN" ;
VAL_ 1143 FLRRTrk16ObstType 6 "NO_OBJECT" 5 "OBJ_GUARDRAIL" 4 "OBJ_TUNNEL " 3 "OBJ_TRAFFIC_SIGN" 2 "OBJ_VEHICLE" 1 "OBJ_BRIDGE " 0 "OBJ_UNKNOWN" ;
VAL_ 1143 FLRRTrk15ObstType 6 "NO_OBJECT" 5 "OBJ_GUARDRAIL" 4 "OBJ_TUNNEL " 3 "OBJ_TRAFFIC_SIGN" 2 "OBJ_VEHICLE" 1 "OBJ_BRIDGE " 0 "OBJ_UNKNOWN" ;
VAL_ 1143 FLRRTrk14ObstType 6 "NO_OBJECT" 5 "OBJ_GUARDRAIL" 4 "OBJ_TUNNEL " 3 "OBJ_TRAFFIC_SIGN" 2 "OBJ_VEHICLE" 1 "OBJ_BRIDGE " 0 "OBJ_UNKNOWN" ;
VAL_ 1142 FLRRTrk12ObstType 6 "NO_OBJECT" 5 "OBJ_GUARDRAIL" 4 "OBJ_TUNNEL " 3 "OBJ_TRAFFIC_SIGN" 2 "OBJ_VEHICLE" 1 "OBJ_BRIDGE " 0 "OBJ_UNKNOWN" ;
VAL_ 1142 FLRRTrk11ObstType 6 "NO_OBJECT" 5 "OBJ_GUARDRAIL" 4 "OBJ_TUNNEL " 3 "OBJ_TRAFFIC_SIGN" 2 "OBJ_VEHICLE" 1 "OBJ_BRIDGE " 0 "OBJ_UNKNOWN" ;
VAL_ 1142 FLRRTrk10ObstType 6 "NO_OBJECT" 5 "OBJ_GUARDRAIL" 4 "OBJ_TUNNEL " 3 "OBJ_TRAFFIC_SIGN" 2 "OBJ_VEHICLE" 1 "OBJ_BRIDGE " 0 "OBJ_UNKNOWN" ;
VAL_ 1142 FLRRTrk9ObstType 6 "NO_OBJECT" 5 "OBJ_GUARDRAIL" 4 "OBJ_TUNNEL " 3 "OBJ_TRAFFIC_SIGN" 2 "OBJ_VEHICLE" 1 "OBJ_BRIDGE " 0 "OBJ_UNKNOWN" ;
VAL_ 1142 FLRRTrk8ObstType 6 "NO_OBJECT" 5 "OBJ_GUARDRAIL" 4 "OBJ_TUNNEL " 3 "OBJ_TRAFFIC_SIGN" 2 "OBJ_VEHICLE" 1 "OBJ_BRIDGE " 0 "OBJ_UNKNOWN" ;
VAL_ 1142 FLRRTrk7ObstType 6 "NO_OBJECT" 5 "OBJ_GUARDRAIL" 4 "OBJ_TUNNEL " 3 "OBJ_TRAFFIC_SIGN" 2 "OBJ_VEHICLE" 1 "OBJ_BRIDGE " 0 "OBJ_UNKNOWN" ;
VAL_ 1142 FLRRTrk1ObstType 6 "NO_OBJECT" 5 "OBJ_GUARDRAIL" 4 "OBJ_TUNNEL " 3 "OBJ_TRAFFIC_SIGN" 2 "OBJ_VEHICLE" 1 "OBJ_BRIDGE " 0 "OBJ_UNKNOWN" ;
VAL_ 1376 R_FusHeadFuncState 3 "Undefined" 2 "Run" 1 "Disabled" 0 "Off" ;
VAL_ 1376 R_FusHead_LrrOK 0 "false" 1 "true" ;
VAL_ 1376 R_FusHead_LRSRROK 1 "true" 0 "false" ;
VAL_ 1376 R_FusHead_VIsOK 1 "true" 0 "false" ;
VAL_ 1376 R_FusHead_MapDataOK 1 "true" 0 "false" ;
VAL_ 1376 R_FusHeadTimStmpV 1 "Invalid" 0 "Valid" ;
VAL_ 1376 R_FusHead_LCSRROK 1 "true" 0 "false" ;
VAL_ 1376 R_FusHead_RCSRROK 1 "true" 0 "false" ;
VAL_ 1376 R_FusHead_RRSRROK 1 "true" 0 "false" ;
VAL_ 850 LnSnsLnCrvtrLftV 1 "Invalid" 0 "Valid" ;
VAL_ 850 LnSnsTngtOfHdngLnLftV 1 "Invalid" 0 "Valid" ;
VAL_ 850 LnMrkrTypRght 0 "Unknown" 1 "Solid" 2 "Dashed" 3 "Dotted" ;
VAL_ 850 LnMrkrTypLft 0 "Unknown" 1 "Solid" 2 "Dashed" 3 "Dotted" ;
VAL_ 850 LnMrkrElvtdRght 1 "true" 0 "false" ;
VAL_ 850 LnMrkrElvtdLft 1 "true" 0 "false" ;
